VERSION "ZCUD_CAN1"

NS_ :

BS_:

BU_: ETC OGM POT SRS3 TRM ZCUD

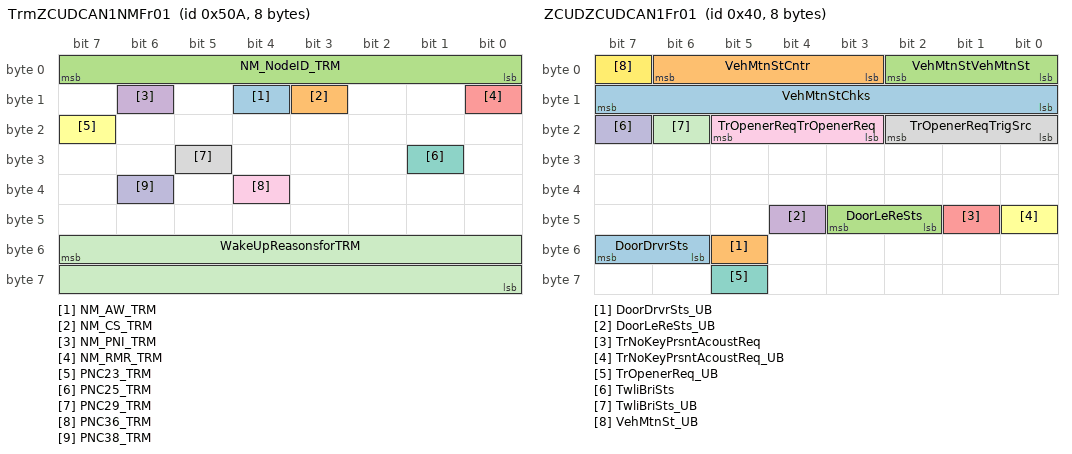
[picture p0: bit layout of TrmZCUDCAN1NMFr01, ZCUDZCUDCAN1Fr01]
BO_ 1290 TrmZCUDCAN1NMFr01: 8 TRM
 SG_ NM_AW_TRM : 12|1@0+ (1,0) [0|0] "" Vector__XXX
 SG_ NM_CS_TRM : 11|1@0+ (1,0) [0|0] "" Vector__XXX
 SG_ NM_NodeID_TRM : 7|8@0+ (1,0) [0|0] "" Vector__XXX
 SG_ NM_PNI_TRM : 14|1@0+ (1,0) [0|0] "" Vector__XXX
 SG_ NM_RMR_TRM : 8|1@0+ (1,0) [0|0] "" Vector__XXX
 SG_ PNC23_TRM : 23|1@0+ (1,0) [0|0] "" Vector__XXX
 SG_ PNC25_TRM : 25|1@0+ (1,0) [0|0] "" Vector__XXX
 SG_ PNC29_TRM : 29|1@0+ (1,0) [0|0] "" Vector__XXX
 SG_ PNC36_TRM : 36|1@0+ (1,0) [0|0] "" Vector__XXX
 SG_ PNC38_TRM : 38|1@0+ (1,0) [0|0] "" Vector__XXX
 SG_ WakeUpReasonsforTRM : 55|16@0+ (1,0) [0|65535] "" Vector__XXX

BO_ 1354 TrmZcudCAN1VFCVectorFr: 8 TRM
 SG_ VFCVectorTRMBlockID : 1|2@0+ (1,0) [0|3] "Unitless"  ZCUD
 SG_ VFCVectorTRMVFCid0 : 2|1@0+ (1,0) [0|1] ""  ZCUD
 SG_ VFCVectorTRMVFCid1 : 3|1@0+ (1,0) [0|1] ""  ZCUD
 SG_ VFCVectorTRMVFCid10 : 12|1@0+ (1,0) [0|1] ""  ZCUD
 SG_ VFCVectorTRMVFCid11 : 13|1@0+ (1,0) [0|1] ""  ZCUD
 SG_ VFCVectorTRMVFCid12 : 14|1@0+ (1,0) [0|1] ""  ZCUD
 SG_ VFCVectorTRMVFCid13 : 15|1@0+ (1,0) [0|1] ""  ZCUD
 SG_ VFCVectorTRMVFCid14 : 16|1@0+ (1,0) [0|1] ""  ZCUD
 SG_ VFCVectorTRMVFCid15 : 17|1@0+ (1,0) [0|1] ""  ZCUD
 SG_ VFCVectorTRMVFCid16 : 18|1@0+ (1,0) [0|1] ""  ZCUD
 SG_ VFCVectorTRMVFCid17 : 19|1@0+ (1,0) [0|1] ""  ZCUD
 SG_ VFCVectorTRMVFCid18 : 20|1@0+ (1,0) [0|1] ""  ZCUD
 SG_ VFCVectorTRMVFCid19 : 21|1@0+ (1,0) [0|1] ""  ZCUD
 SG_ VFCVectorTRMVFCid2 : 4|1@0+ (1,0) [0|1] ""  ZCUD
 SG_ VFCVectorTRMVFCid20 : 22|1@0+ (1,0) [0|1] ""  ZCUD
 SG_ VFCVectorTRMVFCid21 : 23|1@0+ (1,0) [0|1] ""  ZCUD
 SG_ VFCVectorTRMVFCid22 : 24|1@0+ (1,0) [0|1] ""  ZCUD
 SG_ VFCVectorTRMVFCid23 : 25|1@0+ (1,0) [0|1] ""  ZCUD
 SG_ VFCVectorTRMVFCid24 : 26|1@0+ (1,0) [0|1] ""  ZCUD
 SG_ VFCVectorTRMVFCid25 : 27|1@0+ (1,0) [0|1] ""  ZCUD
 SG_ VFCVectorTRMVFCid26 : 28|1@0+ (1,0) [0|1] ""  ZCUD
 SG_ VFCVectorTRMVFCid27 : 29|1@0+ (1,0) [0|1] ""  ZCUD
 SG_ VFCVectorTRMVFCid28 : 30|1@0+ (1,0) [0|1] ""  ZCUD
 SG_ VFCVectorTRMVFCid29 : 31|1@0+ (1,0) [0|1] ""  ZCUD
 SG_ VFCVectorTRMVFCid3 : 5|1@0+ (1,0) [0|1] ""  ZCUD
 SG_ VFCVectorTRMVFCid30 : 32|1@0+ (1,0) [0|1] ""  ZCUD
 SG_ VFCVectorTRMVFCid31 : 33|1@0+ (1,0) [0|1] ""  ZCUD
 SG_ VFCVectorTRMVFCid32 : 34|1@0+ (1,0) [0|1] ""  ZCUD
 SG_ VFCVectorTRMVFCid33 : 35|1@0+ (1,0) [0|1] ""  ZCUD
 SG_ VFCVectorTRMVFCid34 : 36|1@0+ (1,0) [0|1] ""  ZCUD
 SG_ VFCVectorTRMVFCid35 : 37|1@0+ (1,0) [0|1] ""  ZCUD
 SG_ VFCVectorTRMVFCid36 : 38|1@0+ (1,0) [0|1] ""  ZCUD
 SG_ VFCVectorTRMVFCid37 : 39|1@0+ (1,0) [0|1] ""  ZCUD
 SG_ VFCVectorTRMVFCid38 : 40|1@0+ (1,0) [0|1] ""  ZCUD
 SG_ VFCVectorTRMVFCid39 : 41|1@0+ (1,0) [0|1] ""  ZCUD
 SG_ VFCVectorTRMVFCid4 : 6|1@0+ (1,0) [0|1] ""  ZCUD
 SG_ VFCVectorTRMVFCid40 : 42|1@0+ (1,0) [0|1] ""  ZCUD
 SG_ VFCVectorTRMVFCid41 : 43|1@0+ (1,0) [0|1] ""  ZCUD
 SG_ VFCVectorTRMVFCid42 : 44|1@0+ (1,0) [0|1] ""  ZCUD
 SG_ VFCVectorTRMVFCid43 : 45|1@0+ (1,0) [0|1] ""  ZCUD
 SG_ VFCVectorTRMVFCid44 : 46|1@0+ (1,0) [0|1] ""  ZCUD
 SG_ VFCVectorTRMVFCid45 : 47|1@0+ (1,0) [0|1] ""  ZCUD
 SG_ VFCVectorTRMVFCid46 : 48|1@0+ (1,0) [0|1] ""  ZCUD
 SG_ VFCVectorTRMVFCid47 : 49|1@0+ (1,0) [0|1] ""  ZCUD
 SG_ VFCVectorTRMVFCid48 : 50|1@0+ (1,0) [0|1] ""  ZCUD
 SG_ VFCVectorTRMVFCid49 : 51|1@0+ (1,0) [0|1] ""  ZCUD
 SG_ VFCVectorTRMVFCid5 : 7|1@0+ (1,0) [0|1] ""  ZCUD
 SG_ VFCVectorTRMVFCid50 : 52|1@0+ (1,0) [0|1] ""  ZCUD
 SG_ VFCVectorTRMVFCid51 : 53|1@0+ (1,0) [0|1] ""  ZCUD
 SG_ VFCVectorTRMVFCid52 : 54|1@0+ (1,0) [0|1] ""  ZCUD
 SG_ VFCVectorTRMVFCid53 : 55|1@0+ (1,0) [0|1] ""  ZCUD
 SG_ VFCVectorTRMVFCid54 : 56|1@0+ (1,0) [0|1] ""  ZCUD
 SG_ VFCVectorTRMVFCid55 : 57|1@0+ (1,0) [0|1] ""  ZCUD
 SG_ VFCVectorTRMVFCid56 : 58|1@0+ (1,0) [0|1] ""  ZCUD
 SG_ VFCVectorTRMVFCid57 : 59|1@0+ (1,0) [0|1] ""  ZCUD
 SG_ VFCVectorTRMVFCid58 : 60|1@0+ (1,0) [0|1] ""  ZCUD
 SG_ VFCVectorTRMVFCid59 : 61|1@0+ (1,0) [0|1] ""  ZCUD
 SG_ VFCVectorTRMVFCid6 : 8|1@0+ (1,0) [0|1] ""  ZCUD
 SG_ VFCVectorTRMVFCid60 : 62|1@0+ (1,0) [0|1] ""  ZCUD
 SG_ VFCVectorTRMVFCid61 : 63|1@0+ (1,0) [0|1] ""  ZCUD
 SG_ VFCVectorTRMVFCid7 : 9|1@0+ (1,0) [0|1] ""  ZCUD
 SG_ VFCVectorTRMVFCid8 : 10|1@0+ (1,0) [0|1] ""  ZCUD
 SG_ VFCVectorTRMVFCid9 : 11|1@0+ (1,0) [0|1] ""  ZCUD

BO_ 2047 ZcudToAllFuncZcudCAN1DiagReqFr: 8 ZCUD
 SG_ ZcudToAllFuncZcudCAN1DiagReqNpdu : 7|64@0+ (1,0) [0|0] ""  OGM,POT,SRS3,TRM

BO_ 1820 ZcudToCmdZCUDCan1DiagReqFr: 8 ZCUD
 SG_ ZcudToCmdZCUDCan1DiagReqNpdu : 7|64@0+ (1,0) [0|0] "" Vector__XXX

BO_ 1830 ZcudToCrpmZCUDCan1DiagReqFr: 8 ZCUD
 SG_ ZcudToCrpmZCUDCan1DiagReqNpdu : 7|64@0+ (1,0) [0|0] "" Vector__XXX

BO_ 1840 ZcudToHrmZCUDCan1DiagReqFr: 8 ZCUD
 SG_ ZcudToHrmZCUDCAN1DiagReqNpdu : 7|64@0+ (1,0) [0|0] "" Vector__XXX

BO_ 1852 ZcudToOgmZCUDCan1DiagReqFr: 8 ZCUD
 SG_ ZcudToOgmZCUDCan1DiagReqNpdu : 7|64@0+ (1,0) [0|0] ""  OGM

BO_ 1813 ZcudToPotZCUDCan1DiagReqFr: 8 ZCUD
 SG_ ZcudToPotZCUDCan1DiagReqNpdu : 7|64@0+ (1,0) [0|0] ""  POT

BO_ 1808 ZcudToRmlZCUDCAN1DiagReqFrame: 8 ZCUD
 SG_ ZcudToRmlZCUDCAN1DiagReqNpdu : 7|64@0+ (1,0) [0|0] "" Vector__XXX

BO_ 1809 ZcudToRmrZCUDCAN1DiagReqFrame: 8 ZCUD
 SG_ ZcudToRmrZCUDCAN1DiagReqNpdu : 7|64@0+ (1,0) [0|0] "" Vector__XXX

BO_ 1827 ZcudToSdlZCUDCan1DiagReqFr: 8 ZCUD
 SG_ ZcudToSdlZCUDCAN1DiagReqNpdu : 7|64@0+ (1,0) [0|0] "" Vector__XXX

BO_ 1828 ZcudToSdrZCUDCan1DiagReqFr: 8 ZCUD
 SG_ ZcudToSdrZCUDCAN1DiagReqNpdu : 7|64@0+ (1,0) [0|0] "" Vector__XXX

BO_ 1841 ZcudToSmblZCUDCAN1DiagReqFrame: 8 ZCUD
 SG_ ZcudToSmblZCUDCAN1DiagReqNpdu : 7|64@0+ (1,0) [0|0] "" Vector__XXX

BO_ 1842 ZcudToSmbrZCUDCAN1DiagReqFrame: 8 ZCUD
 SG_ ZcudToSmbrZCUDCAN1DiagReqNpdu : 7|64@0+ (1,0) [0|0] "" Vector__XXX

BO_ 1833 ZcudToSmrZCUDCAN1DiagReqFrame: 8 ZCUD
 SG_ ZcudToSmbZCUDCAN1DiagReqNpdu : 7|64@0+ (1,0) [0|0] "" Vector__XXX

BO_ 2033 ZcudToSrsISO26021ZCUDCAN1DiagRes: 8 ZCUD
 SG_ ZcudToSrsISO26021ZCUDCan1ReqNpdu : 7|64@0+ (1,0) [0|0] ""  SRS3

BO_ 1849 ZcudToSrsZCUDCan1DiagReqFr: 8 ZCUD
 SG_ ZcudToSrsZCUDCan1DiagReqNpdu : 7|64@0+ (1,0) [0|0] ""  SRS3

BO_ 1834 ZcudToTcmbZCUDCan1DiagReqFr: 8 ZCUD
 SG_ ZcudToTcmbZCUDCan1DiagReqNpdu : 7|64@0+ (1,0) [0|0] "" Vector__XXX

BO_ 1815 ZcudToTrmZCUDCAN1DiagReqFrame: 8 ZCUD
 SG_ ZcudToTrmZCUDCAN1DiagReqNpdu : 7|64@0+ (1,0) [0|0] ""  TRM

BO_ 1835 ZcudToWpcZCUDCan1DiagReqFr: 8 ZCUD
 SG_ ZcudToWpcZCUDCan1DiagReqNpdu : 7|64@0+ (1,0) [0|0] "" Vector__XXX

BO_ 1846 ZcudToWprlZCUDCan1DiagReqFr: 8 ZCUD
 SG_ ZcudToWprlZCUDCAN1DiagReqNpdu : 7|64@0+ (1,0) [0|0] "" Vector__XXX

BO_ 1847 ZcudToWprrZCUDCan1DiagReqFr: 8 ZCUD
 SG_ ZcudToWprrZCUDCAN1DiagReqNpdu : 7|64@0+ (1,0) [0|0] "" Vector__XXX

BO_ 1345 ZcudZCUCAN1VFCVectorFr: 8 ZCUD
 SG_ VFCVectorZCUDMBlockID : 1|2@0+ (1,0) [0|3] "Unitless" Vector__XXX
 SG_ VFCVectorZCUDMVFCid0 : 2|1@0+ (1,0) [0|1] "" Vector__XXX
 SG_ VFCVectorZCUDMVFCid1 : 3|1@0+ (1,0) [0|1] "" Vector__XXX
 SG_ VFCVectorZCUDMVFCid10 : 12|1@0+ (1,0) [0|1] "" Vector__XXX
 SG_ VFCVectorZCUDMVFCid11 : 13|1@0+ (1,0) [0|1] "" Vector__XXX
 SG_ VFCVectorZCUDMVFCid12 : 14|1@0+ (1,0) [0|1] "" Vector__XXX
 SG_ VFCVectorZCUDMVFCid13 : 15|1@0+ (1,0) [0|1] "" Vector__XXX
 SG_ VFCVectorZCUDMVFCid14 : 16|1@0+ (1,0) [0|1] "" Vector__XXX
 SG_ VFCVectorZCUDMVFCid15 : 17|1@0+ (1,0) [0|1] "" Vector__XXX
 SG_ VFCVectorZCUDMVFCid16 : 18|1@0+ (1,0) [0|1] "" Vector__XXX
 SG_ VFCVectorZCUDMVFCid17 : 19|1@0+ (1,0) [0|1] "" Vector__XXX
 SG_ VFCVectorZCUDMVFCid18 : 20|1@0+ (1,0) [0|1] "" Vector__XXX
 SG_ VFCVectorZCUDMVFCid19 : 21|1@0+ (1,0) [0|1] "" Vector__XXX
 SG_ VFCVectorZCUDMVFCid2 : 4|1@0+ (1,0) [0|1] "" Vector__XXX
 SG_ VFCVectorZCUDMVFCid20 : 22|1@0+ (1,0) [0|1] "" Vector__XXX
 SG_ VFCVectorZCUDMVFCid21 : 23|1@0+ (1,0) [0|1] "" Vector__XXX
 SG_ VFCVectorZCUDMVFCid22 : 24|1@0+ (1,0) [0|1] "" Vector__XXX
 SG_ VFCVectorZCUDMVFCid23 : 25|1@0+ (1,0) [0|1] "" Vector__XXX
 SG_ VFCVectorZCUDMVFCid24 : 26|1@0+ (1,0) [0|1] "" Vector__XXX
 SG_ VFCVectorZCUDMVFCid25 : 27|1@0+ (1,0) [0|1] "" Vector__XXX
 SG_ VFCVectorZCUDMVFCid26 : 28|1@0+ (1,0) [0|1] "" Vector__XXX
 SG_ VFCVectorZCUDMVFCid27 : 29|1@0+ (1,0) [0|1] "" Vector__XXX
 SG_ VFCVectorZCUDMVFCid28 : 30|1@0+ (1,0) [0|1] "" Vector__XXX
 SG_ VFCVectorZCUDMVFCid29 : 31|1@0+ (1,0) [0|1] "" Vector__XXX
 SG_ VFCVectorZCUDMVFCid3 : 5|1@0+ (1,0) [0|1] "" Vector__XXX
 SG_ VFCVectorZCUDMVFCid30 : 32|1@0+ (1,0) [0|1] "" Vector__XXX
 SG_ VFCVectorZCUDMVFCid31 : 33|1@0+ (1,0) [0|1] "" Vector__XXX
 SG_ VFCVectorZCUDMVFCid32 : 34|1@0+ (1,0) [0|1] "" Vector__XXX
 SG_ VFCVectorZCUDMVFCid33 : 35|1@0+ (1,0) [0|1] "" Vector__XXX
 SG_ VFCVectorZCUDMVFCid34 : 36|1@0+ (1,0) [0|1] "" Vector__XXX
 SG_ VFCVectorZCUDMVFCid35 : 37|1@0+ (1,0) [0|1] "" Vector__XXX
 SG_ VFCVectorZCUDMVFCid36 : 38|1@0+ (1,0) [0|1] "" Vector__XXX
 SG_ VFCVectorZCUDMVFCid37 : 39|1@0+ (1,0) [0|1] "" Vector__XXX
 SG_ VFCVectorZCUDMVFCid38 : 40|1@0+ (1,0) [0|1] "" Vector__XXX
 SG_ VFCVectorZCUDMVFCid39 : 41|1@0+ (1,0) [0|1] "" Vector__XXX
 SG_ VFCVectorZCUDMVFCid4 : 6|1@0+ (1,0) [0|1] "" Vector__XXX
 SG_ VFCVectorZCUDMVFCid40 : 42|1@0+ (1,0) [0|1] "" Vector__XXX
 SG_ VFCVectorZCUDMVFCid41 : 43|1@0+ (1,0) [0|1] "" Vector__XXX
 SG_ VFCVectorZCUDMVFCid42 : 44|1@0+ (1,0) [0|1] "" Vector__XXX
 SG_ VFCVectorZCUDMVFCid43 : 45|1@0+ (1,0) [0|1] "" Vector__XXX
 SG_ VFCVectorZCUDMVFCid44 : 46|1@0+ (1,0) [0|1] "" Vector__XXX
 SG_ VFCVectorZCUDMVFCid45 : 47|1@0+ (1,0) [0|1] "" Vector__XXX
 SG_ VFCVectorZCUDMVFCid46 : 48|1@0+ (1,0) [0|1] "" Vector__XXX
 SG_ VFCVectorZCUDMVFCid47 : 49|1@0+ (1,0) [0|1] "" Vector__XXX
 SG_ VFCVectorZCUDMVFCid48 : 50|1@0+ (1,0) [0|1] "" Vector__XXX
 SG_ VFCVectorZCUDMVFCid49 : 51|1@0+ (1,0) [0|1] "" Vector__XXX
 SG_ VFCVectorZCUDMVFCid5 : 7|1@0+ (1,0) [0|1] "" Vector__XXX
 SG_ VFCVectorZCUDMVFCid50 : 52|1@0+ (1,0) [0|1] "" Vector__XXX
 SG_ VFCVectorZCUDMVFCid51 : 53|1@0+ (1,0) [0|1] "" Vector__XXX
 SG_ VFCVectorZCUDMVFCid52 : 54|1@0+ (1,0) [0|1] "" Vector__XXX
 SG_ VFCVectorZCUDMVFCid53 : 55|1@0+ (1,0) [0|1] "" Vector__XXX
 SG_ VFCVectorZCUDMVFCid54 : 56|1@0+ (1,0) [0|1] "" Vector__XXX
 SG_ VFCVectorZCUDMVFCid55 : 57|1@0+ (1,0) [0|1] "" Vector__XXX
 SG_ VFCVectorZCUDMVFCid56 : 58|1@0+ (1,0) [0|1] "" Vector__XXX
 SG_ VFCVectorZCUDMVFCid57 : 59|1@0+ (1,0) [0|1] "" Vector__XXX
 SG_ VFCVectorZCUDMVFCid58 : 60|1@0+ (1,0) [0|1] "" Vector__XXX
 SG_ VFCVectorZCUDMVFCid59 : 61|1@0+ (1,0) [0|1] "" Vector__XXX
 SG_ VFCVectorZCUDMVFCid6 : 8|1@0+ (1,0) [0|1] "" Vector__XXX
 SG_ VFCVectorZCUDMVFCid60 : 62|1@0+ (1,0) [0|1] "" Vector__XXX
 SG_ VFCVectorZCUDMVFCid61 : 63|1@0+ (1,0) [0|1] "" Vector__XXX
 SG_ VFCVectorZCUDMVFCid7 : 9|1@0+ (1,0) [0|1] "" Vector__XXX
 SG_ VFCVectorZCUDMVFCid8 : 10|1@0+ (1,0) [0|1] "" Vector__XXX
 SG_ VFCVectorZCUDMVFCid9 : 11|1@0+ (1,0) [0|1] "" Vector__XXX

BO_ 64 ZCUDZCUDCAN1Fr01: 8 ZCUD
 SG_ DoorDrvrSts : 55|2@0+ (1,0) [0|3] ""  SRS3,TRM
 SG_ DoorDrvrSts_UB : 53|1@0+ (1,0) [0|1] ""  SRS3,TRM
 SG_ DoorLeReSts : 43|2@0+ (1,0) [0|3] ""  SRS3,TRM
 SG_ DoorLeReSts_UB : 44|1@0+ (1,0) [0|1] ""  SRS3,TRM
 SG_ TrNoKeyPrsntAcoustReq : 41|1@0+ (1,0) [0|1] "" Vector__XXX
 SG_ TrNoKeyPrsntAcoustReq_UB : 40|1@0+ (1,0) [0|1] "" Vector__XXX
 SG_ TrOpenerReq_UB : 61|1@0+ (1,0) [0|1] "" Vector__XXX
 SG_ TrOpenerReqTrigSrc : 18|3@0+ (1,0) [0|7] "" Vector__XXX
 SG_ TrOpenerReqTrOpenerReq : 21|3@0+ (1,0) [0|7] "" Vector__XXX
 SG_ TwliBriSts : 23|1@0+ (1,0) [0|1] ""  TRM
 SG_ TwliBriSts_UB : 22|1@0+ (1,0) [0|1] ""  TRM
 SG_ VehMtnSt_UB : 7|1@0+ (1,0) [0|1] ""  POT,SRS3,TRM
 SG_ VehMtnStChks : 15|8@0+ (1,0) [0|255] "Unitless"  POT,SRS3,TRM
 SG_ VehMtnStCntr : 6|4@0+ (1,0) [0|15] "Unitless"  POT,SRS3,TRM
 SG_ VehMtnStVehMtnSt : 2|3@0+ (1,0) [0|7] ""  POT,SRS3,TRM

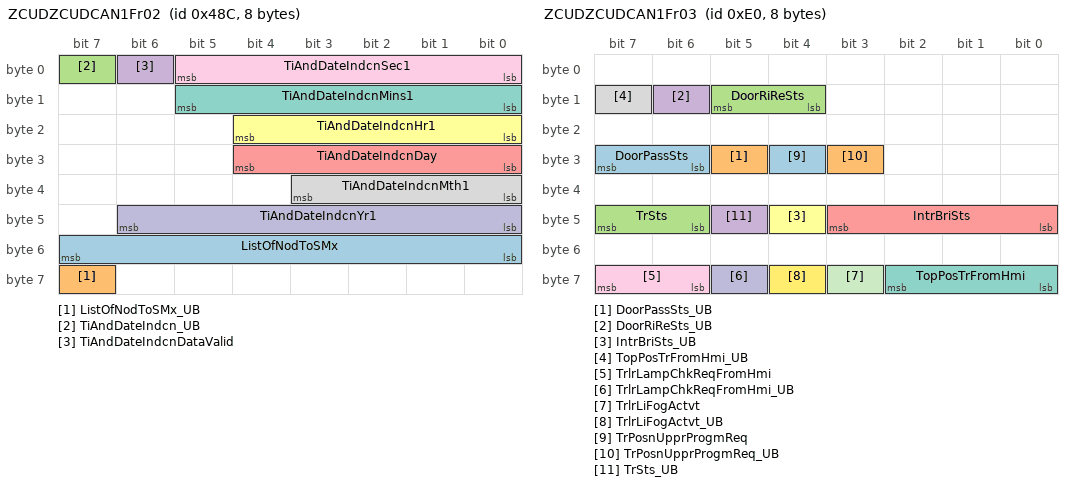
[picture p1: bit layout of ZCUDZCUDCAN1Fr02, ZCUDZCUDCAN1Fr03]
BO_ 1164 ZCUDZCUDCAN1Fr02: 8 ZCUD
 SG_ ListOfNodToSMx : 55|8@0+ (1,0) [0|255] "Unitless" Vector__XXX
 SG_ ListOfNodToSMx_UB : 63|1@0+ (1,0) [0|1] "" Vector__XXX
 SG_ TiAndDateIndcn_UB : 7|1@0+ (1,0) [0|1] ""  OGM,POT,SRS3,TRM
 SG_ TiAndDateIndcnDataValid : 6|1@0+ (1,0) [0|1] ""  OGM,POT,SRS3,TRM
 SG_ TiAndDateIndcnDay : 28|5@0+ (1,0) [1|31] "Days"  OGM,POT,SRS3,TRM
 SG_ TiAndDateIndcnHr1 : 20|5@0+ (1,0) [0|23] "hours"  OGM,POT,SRS3,TRM
 SG_ TiAndDateIndcnMins1 : 13|6@0+ (1,0) [0|59] "Mins"  OGM,POT,SRS3,TRM
 SG_ TiAndDateIndcnMth1 : 35|4@0+ (1,0) [1|12] "Month"  OGM,POT,SRS3,TRM
 SG_ TiAndDateIndcnSec1 : 5|6@0+ (1,0) [0|59] "s"  OGM,POT,SRS3,TRM
 SG_ TiAndDateIndcnYr1 : 46|7@0+ (1,0) [0|99] "Year"  OGM,POT,SRS3,TRM

BO_ 224 ZCUDZCUDCAN1Fr03: 8 ZCUD
 SG_ DoorPassSts : 31|2@0+ (1,0) [0|3] ""  SRS3,TRM
 SG_ DoorPassSts_UB : 29|1@0+ (1,0) [0|1] ""  SRS3,TRM
 SG_ DoorRiReSts : 13|2@0+ (1,0) [0|3] ""  SRS3,TRM
 SG_ DoorRiReSts_UB : 14|1@0+ (1,0) [0|1] ""  SRS3,TRM
 SG_ IntrBriSts : 43|4@0+ (1,0) [0|15] "Unitless" Vector__XXX
 SG_ IntrBriSts_UB : 44|1@0+ (1,0) [0|1] "" Vector__XXX
 SG_ TopPosTrFromHmi : 58|3@0+ (1,0) [0|7] "" Vector__XXX
 SG_ TopPosTrFromHmi_UB : 15|1@0+ (1,0) [0|1] "" Vector__XXX
 SG_ TrlrLampChkReqFromHmi : 63|2@0+ (1,0) [0|3] ""  TRM
 SG_ TrlrLampChkReqFromHmi_UB : 61|1@0+ (1,0) [0|1] ""  TRM
 SG_ TrlrLiFogActvt : 59|1@0+ (1,0) [0|1] ""  TRM
 SG_ TrlrLiFogActvt_UB : 60|1@0+ (1,0) [0|1] ""  TRM
 SG_ TrPosnUpprProgmReq : 28|1@0+ (1,0) [0|1] "" Vector__XXX
 SG_ TrPosnUpprProgmReq_UB : 27|1@0+ (1,0) [0|1] "" Vector__XXX
 SG_ TrSts : 47|2@0+ (1,0) [0|3] ""  POT,TRM
 SG_ TrSts_UB : 45|1@0+ (1,0) [0|1] ""  POT,TRM

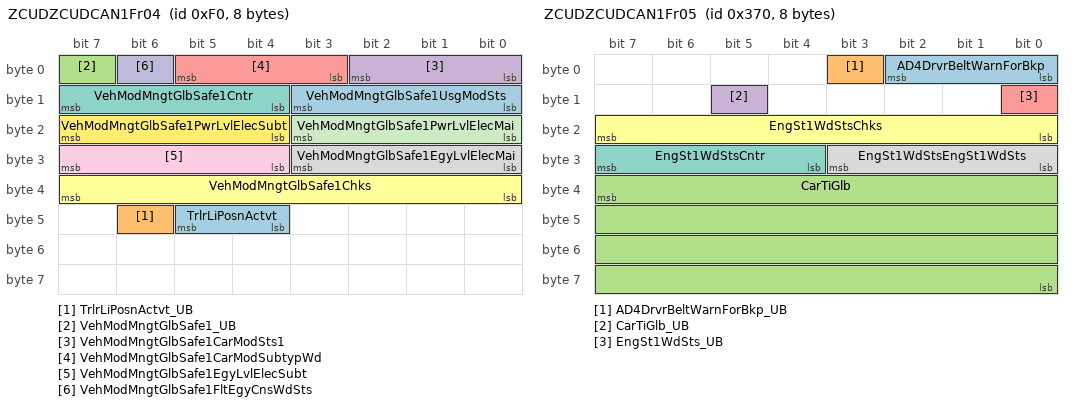
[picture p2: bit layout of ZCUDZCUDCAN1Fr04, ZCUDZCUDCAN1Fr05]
BO_ 240 ZCUDZCUDCAN1Fr04: 8 ZCUD
 SG_ TrlrLiPosnActvt : 45|2@0+ (1,0) [0|3] ""  TRM
 SG_ TrlrLiPosnActvt_UB : 46|1@0+ (1,0) [0|1] ""  TRM
 SG_ VehModMngtGlbSafe1_UB : 7|1@0+ (1,0) [0|1] ""  OGM,POT,SRS3,TRM
 SG_ VehModMngtGlbSafe1CarModSts1 : 2|3@0+ (1,0) [0|7] ""  OGM,POT,SRS3,TRM
 SG_ VehModMngtGlbSafe1CarModSubtypWd : 5|3@0+ (1,0) [0|7] "Unitless"  OGM,POT,SRS3,TRM
 SG_ VehModMngtGlbSafe1Chks : 39|8@0+ (1,0) [0|255] "Unitless"  OGM,POT,SRS3,TRM
 SG_ VehModMngtGlbSafe1Cntr : 15|4@0+ (1,0) [0|15] "Unitless"  OGM,POT,SRS3,TRM
 SG_ VehModMngtGlbSafe1EgyLvlElecMai : 27|4@0+ (1,0) [0|15] "Unitless"  OGM,POT,SRS3,TRM
 SG_ VehModMngtGlbSafe1EgyLvlElecSubt : 31|4@0+ (1,0) [0|15] "Unitless"  OGM,POT,SRS3,TRM
 SG_ VehModMngtGlbSafe1FltEgyCnsWdSts : 6|1@0+ (1,0) [0|1] ""  OGM,POT,SRS3,TRM
 SG_ VehModMngtGlbSafe1PwrLvlElecMai : 19|4@0+ (1,0) [0|15] "Unitless"  OGM,POT,SRS3,TRM
 SG_ VehModMngtGlbSafe1PwrLvlElecSubt : 23|4@0+ (1,0) [0|15] "Unitless"  OGM,POT,SRS3,TRM
 SG_ VehModMngtGlbSafe1UsgModSts : 11|4@0+ (1,0) [0|15] ""  OGM,POT,SRS3,TRM

BO_ 880 ZCUDZCUDCAN1Fr05: 8 ZCUD
 SG_ AD4DrvrBeltWarnForBkp : 2|3@0+ (1,0) [0|7] "" Vector__XXX
 SG_ AD4DrvrBeltWarnForBkp_UB : 3|1@0+ (1,0) [0|1] "" Vector__XXX
 SG_ CarTiGlb : 39|32@0+ (0.1,0) [0|429496729.5] "s"  OGM,POT,SRS3,TRM
 SG_ CarTiGlb_UB : 13|1@0+ (1,0) [0|1] ""  OGM,POT,SRS3,TRM
 SG_ EngSt1WdSts_UB : 8|1@0+ (1,0) [0|1] "" Vector__XXX
 SG_ EngSt1WdStsChks : 23|8@0+ (1,0) [0|255] "Unitless" Vector__XXX
 SG_ EngSt1WdStsCntr : 31|4@0+ (1,0) [0|15] "Unitless" Vector__XXX
 SG_ EngSt1WdStsEngSt1WdSts : 27|4@0+ (1,0) [0|15] "" Vector__XXX

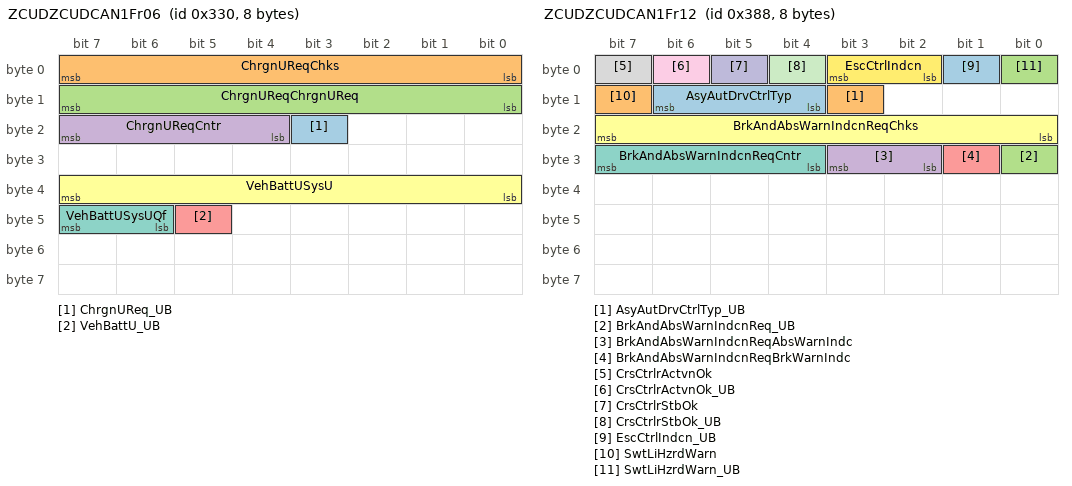
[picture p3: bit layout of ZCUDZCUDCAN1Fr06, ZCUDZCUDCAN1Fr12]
BO_ 816 ZCUDZCUDCAN1Fr06: 8 ZCUD
 SG_ ChrgnUReq_UB : 19|1@0+ (1,0) [0|1] "" Vector__XXX
 SG_ ChrgnUReqChks : 7|8@0+ (1,0) [0|255] "Unitless" Vector__XXX
 SG_ ChrgnUReqChrgnUReq : 15|8@0+ (0.025,10.6) [10.6|16] "Volt" Vector__XXX
 SG_ ChrgnUReqCntr : 23|4@0+ (1,0) [0|15] "Unitless" Vector__XXX
 SG_ VehBattU_UB : 45|1@0+ (1,0) [0|1] ""  OGM,POT,SRS3,TRM
 SG_ VehBattUSysU : 39|8@0+ (0.1,0) [0|25] "Volt"  OGM,POT,SRS3,TRM
 SG_ VehBattUSysUQf : 47|2@0+ (1,0) [0|3] ""  OGM,POT,SRS3,TRM

BO_ 881 ZCUDZCUDCAN1Fr09: 8 ZCUD
 SG_ AD4DrvrBeltWarn : 2|3@0+ (1,0) [0|7] "" Vector__XXX
 SG_ AD4DrvrBeltWarn_UB : 3|1@0+ (1,0) [0|1] "" Vector__XXX
 SG_ CarModCrashSaved : 7|1@0+ (1,0) [0|1] ""  SRS3
 SG_ CarModCrashSaved_UB : 6|1@0+ (1,0) [0|1] ""  SRS3
 SG_ DrvrSeatSnsrSts : 5|2@0+ (1,0) [0|3] "" Vector__XXX
 SG_ DrvrSeatSnsrSts_UB : 31|1@0+ (1,0) [0|1] "" Vector__XXX
 SG_ EngN2 : 14|15@0+ (0.5,0) [0|16383.5] "rpm"  SRS3
 SG_ EngN2_UB : 15|1@0+ (1,0) [0|1] ""  SRS3
 SG_ HvBattPreChrgReq : 52|1@0+ (1,0) [0|1] "" Vector__XXX
 SG_ HvBattPreChrgReq_UB : 51|1@0+ (1,0) [0|1] "" Vector__XXX
 SG_ IsgSpdActSgn : 39|16@0+ (1,-20000) [-20000|45535] "rpm"  SRS3
 SG_ IsgSpdActSgn_UB : 53|1@0+ (1,0) [0|1] ""  SRS3
 SG_ PostImpctBrkgRdy : 29|2@0+ (1,0) [0|3] ""  SRS3
 SG_ PostImpctBrkgRdy_UB : 30|1@0+ (1,0) [0|1] ""  SRS3
 SG_ RlyPwrDistbnCmd1WdPreBattSaveCmd : 50|1@0+ (1,0) [0|1] "" Vector__XXX
 SG_ RlyPwrDistbnCmd1WdPreBattSa_0000 : 49|1@0+ (1,0) [0|1] "" Vector__XXX
 SG_ SeatOccptAtRowSecDrSide2 : 27|2@0+ (1,0) [0|3] "" Vector__XXX
 SG_ SeatOccptAtRowSecDrSide2_UB : 25|1@0+ (1,0) [0|1] "" Vector__XXX
 SG_ SeatOccptAtRowSecDrSideSnsSts2 : 55|2@0+ (1,0) [0|3] "" Vector__XXX
 SG_ SeatOccptAtRowSecDrSideSnsSts2_U : 24|1@0+ (1,0) [0|1] "" Vector__XXX

BO_ 912 ZCUDZCUDCAN1Fr10: 8 ZCUD
 SG_ DispOfPrpsnMod : 60|4@0+ (1,0) [0|15] ""  SRS3
 SG_ DispOfPrpsnMod_UB : 56|1@0+ (1,0) [0|1] ""  SRS3
 SG_ DispOfPrpsnModForEv : 7|4@0+ (1,0) [0|15] ""  SRS3
 SG_ DispOfPrpsnModForEv_UB : 3|1@0+ (1,0) [0|1] ""  SRS3
 SG_ DrvrSeatPosPerc_UB : 2|1@0+ (1,0) [0|1] ""  SRS3
 SG_ DrvrSeatPosPercSeatPosFrntHeiPer : 15|10@0+ (0.1,0) [0|100] "%"  SRS3
 SG_ DrvrSeatPosPercSeatPosFrntHeiQF : 1|2@0+ (1,0) [0|3] ""  SRS3
 SG_ DrvrSeatPosPercSeatPosHeiPerc : 17|10@0+ (0.1,0) [0|100] "%"  SRS3
 SG_ DrvrSeatPosPercSeatPosHeiQF : 19|2@0+ (1,0) [0|3] ""  SRS3
 SG_ DrvrSeatPosPercSeatPosSldPerc : 39|10@0+ (0.1,0) [0|100] "%"  SRS3
 SG_ DrvrSeatPosPercSeatPosSldQF : 21|2@0+ (1,0) [0|3] ""  SRS3
 SG_ PassAirbLampStsRec_UB : 63|1@0+ (1,0) [0|1] ""  SRS3
 SG_ PassAirbLampStsRecPassAirbLampSt : 45|2@0+ (1,0) [0|3] ""  SRS3
 SG_ PassAirbLampStsRecPassAirbL_0000 : 55|8@0+ (1,0) [0|255] "Unitless"  SRS3
 SG_ PassAirbLampStsRecPassAirbL_0001 : 43|4@0+ (1,0) [0|15] "Unitless"  SRS3
 SG_ RlyPwrDistbnCmd1WdIgnRlyExtCmd : 62|1@0+ (1,0) [0|1] ""  SRS3
 SG_ RlyPwrDistbnCmd1WdIgnRlyExtCmd_U : 61|1@0+ (1,0) [0|1] ""  SRS3

BO_ 924 ZCUDZCUDCAN1Fr11: 8 ZCUD
 SG_ RiFrntTireMsg_UB : 31|1@0+ (1,0) [0|1] ""  SRS3
 SG_ RiFrntTireMsgBattLoSt : 7|1@0+ (1,0) [0|1] ""  SRS3
 SG_ RiFrntTireMsgFastLoseWarnFlg : 6|1@0+ (1,0) [0|1] ""  SRS3
 SG_ RiFrntTireMsgMsgOldFlg : 5|1@0+ (1,0) [0|1] ""  SRS3
 SG_ RiFrntTireMsgP : 15|8@0+ (1.373,0) [0|350.115] "KiloPa"  SRS3
 SG_ RiFrntTireMsgPWarnFlg : 4|2@0+ (1,0) [0|3] ""  SRS3
 SG_ RiFrntTireMsgSysWarnFlg : 2|1@0+ (1,0) [0|1] ""  SRS3
 SG_ RiFrntTireMsgT : 23|8@0+ (1,-50) [-50|205] "degC"  SRS3
 SG_ RiFrntTireMsgTireFillgAssiPSts : 0|1@0+ (1,0) [0|1] ""  SRS3
 SG_ RiFrntTireMsgTWarnFlg : 1|1@0+ (1,0) [0|1] ""  SRS3
 SG_ RiReTireMsg_UB : 30|1@0+ (1,0) [0|1] ""  SRS3
 SG_ RiReTireMsgBattLoSt : 47|1@0+ (1,0) [0|1] ""  SRS3
 SG_ RiReTireMsgFastLoseWarnFlg : 46|1@0+ (1,0) [0|1] ""  SRS3
 SG_ RiReTireMsgMsgOldFlg : 45|1@0+ (1,0) [0|1] ""  SRS3
 SG_ RiReTireMsgP : 55|8@0+ (1.373,0) [0|350.115] "KiloPa"  SRS3
 SG_ RiReTireMsgPWarnFlg : 44|2@0+ (1,0) [0|3] ""  SRS3
 SG_ RiReTireMsgSysWarnFlg : 42|1@0+ (1,0) [0|1] ""  SRS3
 SG_ RiReTireMsgT : 63|8@0+ (1,-50) [-50|205] "degC"  SRS3
 SG_ RiReTireMsgTireFillgAssiPSts : 40|1@0+ (1,0) [0|1] ""  SRS3
 SG_ RiReTireMsgTWarnFlg : 41|1@0+ (1,0) [0|1] ""  SRS3

BO_ 904 ZCUDZCUDCAN1Fr12: 8 ZCUD
 SG_ AsyAutDrvCtrlTyp : 14|3@0+ (1,0) [0|7] ""  SRS3
 SG_ AsyAutDrvCtrlTyp_UB : 11|1@0+ (1,0) [0|1] ""  SRS3
 SG_ BrkAndAbsWarnIndcnReq_UB : 24|1@0+ (1,0) [0|1] ""  SRS3
 SG_ BrkAndAbsWarnIndcnReqAbsWarnIndc : 27|2@0+ (1,0) [0|3] ""  SRS3
 SG_ BrkAndAbsWarnIndcnReqBrkWarnIndc : 25|1@0+ (1,0) [0|1] ""  SRS3
 SG_ BrkAndAbsWarnIndcnReqChks : 23|8@0+ (1,0) [0|255] "Unitless"  SRS3
 SG_ BrkAndAbsWarnIndcnReqCntr : 31|4@0+ (1,0) [0|15] "Unitless"  SRS3
 SG_ CrsCtrlrActvnOk : 7|1@0+ (1,0) [0|1] ""  SRS3
 SG_ CrsCtrlrActvnOk_UB : 6|1@0+ (1,0) [0|1] ""  SRS3
 SG_ CrsCtrlrStbOk : 5|1@0+ (1,0) [0|1] ""  SRS3
 SG_ CrsCtrlrStbOk_UB : 4|1@0+ (1,0) [0|1] ""  SRS3
 SG_ EscCtrlIndcn : 3|2@0+ (1,0) [0|3] ""  SRS3
 SG_ EscCtrlIndcn_UB : 1|1@0+ (1,0) [0|1] ""  SRS3
 SG_ SwtLiHzrdWarn : 15|1@0+ (1,0) [0|1] ""  SRS3
 SG_ SwtLiHzrdWarn_UB : 0|1@0+ (1,0) [0|1] ""  SRS3

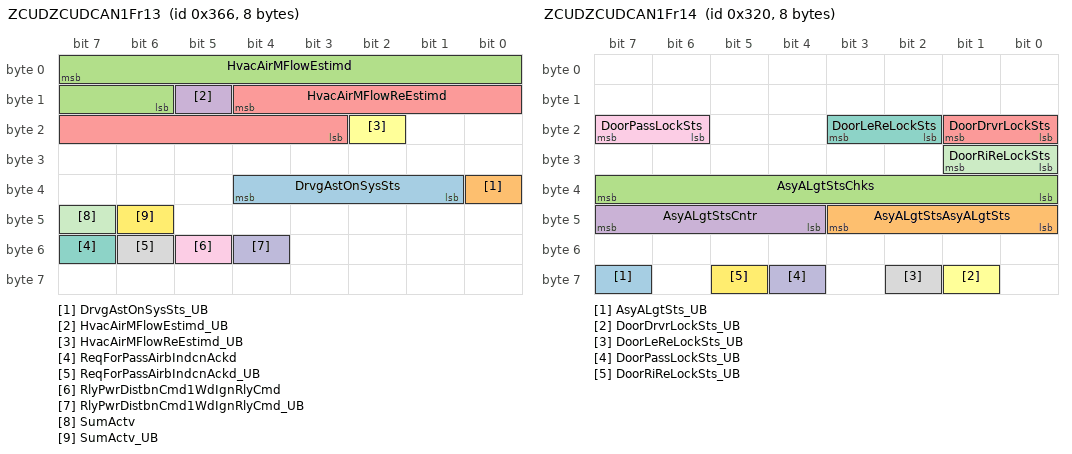
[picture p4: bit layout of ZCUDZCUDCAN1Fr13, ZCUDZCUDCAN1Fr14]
BO_ 870 ZCUDZCUDCAN1Fr13: 8 ZCUD
 SG_ DrvgAstOnSysSts : 36|4@0+ (1,0) [0|15] "" Vector__XXX
 SG_ DrvgAstOnSysSts_UB : 32|1@0+ (1,0) [0|1] "" Vector__XXX
 SG_ HvacAirMFlowEstimd : 7|10@0+ (1,0) [0|1000] "Kg / h" Vector__XXX
 SG_ HvacAirMFlowEstimd_UB : 13|1@0+ (1,0) [0|1] "" Vector__XXX
 SG_ HvacAirMFlowReEstimd : 12|10@0+ (1,0) [0|1000] "Kg / h" Vector__XXX
 SG_ HvacAirMFlowReEstimd_UB : 18|1@0+ (1,0) [0|1] "" Vector__XXX
 SG_ ReqForPassAirbIndcnAckd : 55|1@0+ (1,0) [0|1] ""  SRS3
 SG_ ReqForPassAirbIndcnAckd_UB : 54|1@0+ (1,0) [0|1] ""  SRS3
 SG_ RlyPwrDistbnCmd1WdIgnRlyCmd : 53|1@0+ (1,0) [0|1] ""  SRS3
 SG_ RlyPwrDistbnCmd1WdIgnRlyCmd_UB : 52|1@0+ (1,0) [0|1] ""  SRS3
 SG_ SumActv : 47|1@0+ (1,0) [0|1] ""  SRS3
 SG_ SumActv_UB : 46|1@0+ (1,0) [0|1] ""  SRS3

BO_ 800 ZCUDZCUDCAN1Fr14: 8 ZCUD
 SG_ AsyALgtSts_UB : 63|1@0+ (1,0) [0|1] ""  SRS3
 SG_ AsyALgtStsAsyALgtSts : 43|4@0+ (1,0) [0|15] ""  SRS3
 SG_ AsyALgtStsChks : 39|8@0+ (1,0) [0|255] "Unitless"  SRS3
 SG_ AsyALgtStsCntr : 47|4@0+ (1,0) [0|15] "Unitless"  SRS3
 SG_ DoorDrvrLockSts : 17|2@0+ (1,0) [0|3] ""  SRS3
 SG_ DoorDrvrLockSts_UB : 57|1@0+ (1,0) [0|1] ""  SRS3
 SG_ DoorLeReLockSts : 19|2@0+ (1,0) [0|3] ""  SRS3
 SG_ DoorLeReLockSts_UB : 58|1@0+ (1,0) [0|1] ""  SRS3
 SG_ DoorPassLockSts : 23|2@0+ (1,0) [0|3] ""  SRS3
 SG_ DoorPassLockSts_UB : 60|1@0+ (1,0) [0|1] ""  SRS3
 SG_ DoorRiReLockSts : 25|2@0+ (1,0) [0|3] ""  SRS3
 SG_ DoorRiReLockSts_UB : 61|1@0+ (1,0) [0|1] ""  SRS3

BO_ 385 ZCUDZCUDCAN1Fr18: 8 ZCUD
 SG_ EmgyAsscTrigSts : 53|2@0+ (1,0) [0|3] ""  SRS3
 SG_ EmgyAsscTrigSts_UB : 54|1@0+ (1,0) [0|1] ""  SRS3

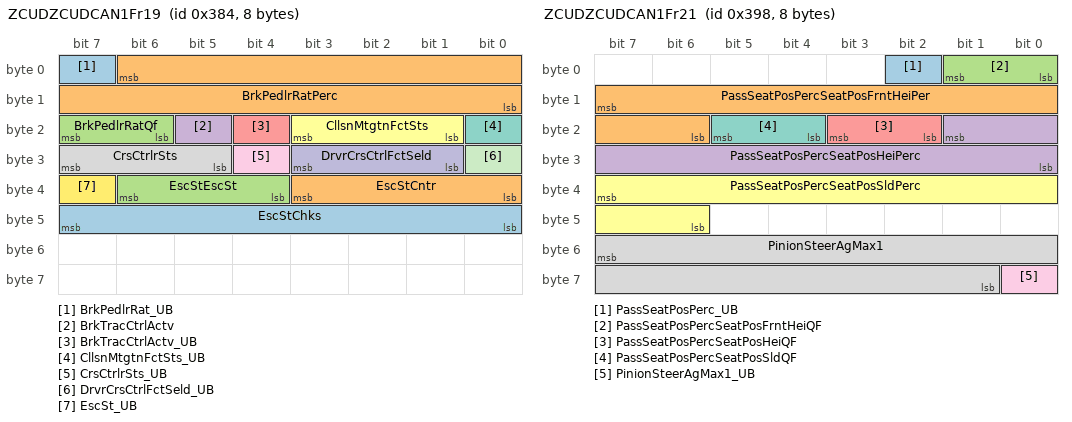
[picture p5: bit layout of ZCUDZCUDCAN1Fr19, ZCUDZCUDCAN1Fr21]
BO_ 900 ZCUDZCUDCAN1Fr19: 8 ZCUD
 SG_ BrkPedlrRat_UB : 7|1@0+ (1,0) [0|1] ""  SRS3
 SG_ BrkPedlrRatPerc : 6|15@0+ (0.00390625,0) [0|100] "%"  SRS3
 SG_ BrkPedlrRatQf : 23|2@0+ (1,0) [0|3] ""  SRS3
 SG_ BrkTracCtrlActv : 21|1@0+ (1,0) [0|1] ""  SRS3
 SG_ BrkTracCtrlActv_UB : 20|1@0+ (1,0) [0|1] ""  SRS3
 SG_ CllsnMtgtnFctSts : 19|3@0+ (1,0) [0|7] ""  SRS3
 SG_ CllsnMtgtnFctSts_UB : 16|1@0+ (1,0) [0|1] ""  SRS3
 SG_ CrsCtrlrSts : 31|3@0+ (1,0) [0|7] ""  SRS3
 SG_ CrsCtrlrSts_UB : 28|1@0+ (1,0) [0|1] ""  SRS3
 SG_ DrvrCrsCtrlFctSeld : 27|3@0+ (1,0) [0|7] ""  SRS3
 SG_ DrvrCrsCtrlFctSeld_UB : 24|1@0+ (1,0) [0|1] ""  SRS3
 SG_ EscSt_UB : 39|1@0+ (1,0) [0|1] ""  SRS3
 SG_ EscStChks : 47|8@0+ (1,0) [0|255] "Unitless"  SRS3
 SG_ EscStCntr : 35|4@0+ (1,0) [0|15] "Unitless"  SRS3
 SG_ EscStEscSt : 38|3@0+ (1,0) [0|7] ""  SRS3

BO_ 916 ZCUDZCUDCAN1Fr20: 8 ZCUD
 SG_ LeFrntTireMsg_UB : 31|1@0+ (1,0) [0|1] ""  SRS3
 SG_ LeFrntTireMsgBattLoSt : 7|1@0+ (1,0) [0|1] ""  SRS3
 SG_ LeFrntTireMsgFastLoseWarnFlg : 6|1@0+ (1,0) [0|1] ""  SRS3
 SG_ LeFrntTireMsgMsgOldFlg : 5|1@0+ (1,0) [0|1] ""  SRS3
 SG_ LeFrntTireMsgP : 15|8@0+ (1.373,0) [0|350.115] "KiloPa"  SRS3
 SG_ LeFrntTireMsgPWarnFlg : 4|2@0+ (1,0) [0|3] ""  SRS3
 SG_ LeFrntTireMsgSysWarnFlg : 2|1@0+ (1,0) [0|1] ""  SRS3
 SG_ LeFrntTireMsgT : 23|8@0+ (1,-50) [-50|205] "degC"  SRS3
 SG_ LeFrntTireMsgTireFillgAssiPSts : 0|1@0+ (1,0) [0|1] ""  SRS3
 SG_ LeFrntTireMsgTWarnFlg : 1|1@0+ (1,0) [0|1] ""  SRS3
 SG_ LeReTireMsg_UB : 30|1@0+ (1,0) [0|1] ""  SRS3
 SG_ LeReTireMsgBattLoSt : 47|1@0+ (1,0) [0|1] ""  SRS3
 SG_ LeReTireMsgFastLoseWarnFlg : 46|1@0+ (1,0) [0|1] ""  SRS3
 SG_ LeReTireMsgMsgOldFlg : 45|1@0+ (1,0) [0|1] ""  SRS3
 SG_ LeReTireMsgP : 55|8@0+ (1.373,0) [0|350.115] "KiloPa"  SRS3
 SG_ LeReTireMsgPWarnFlg : 44|2@0+ (1,0) [0|3] ""  SRS3
 SG_ LeReTireMsgSysWarnFlg : 42|1@0+ (1,0) [0|1] ""  SRS3
 SG_ LeReTireMsgT : 63|8@0+ (1,-50) [-50|205] "degC"  SRS3
 SG_ LeReTireMsgTireFillgAssiPSts : 40|1@0+ (1,0) [0|1] ""  SRS3
 SG_ LeReTireMsgTWarnFlg : 41|1@0+ (1,0) [0|1] ""  SRS3

BO_ 920 ZCUDZCUDCAN1Fr21: 8 ZCUD
 SG_ PassSeatPosPerc_UB : 2|1@0+ (1,0) [0|1] ""  SRS3
 SG_ PassSeatPosPercSeatPosFrntHeiPer : 15|10@0+ (0.1,0) [0|100] "%"  SRS3
 SG_ PassSeatPosPercSeatPosFrntHeiQF : 1|2@0+ (1,0) [0|3] ""  SRS3
 SG_ PassSeatPosPercSeatPosHeiPerc : 17|10@0+ (0.1,0) [0|100] "%"  SRS3
 SG_ PassSeatPosPercSeatPosHeiQF : 19|2@0+ (1,0) [0|3] ""  SRS3
 SG_ PassSeatPosPercSeatPosSldPerc : 39|10@0+ (0.1,0) [0|100] "%"  SRS3
 SG_ PassSeatPosPercSeatPosSldQF : 21|2@0+ (1,0) [0|3] ""  SRS3
 SG_ PinionSteerAgMax1 : 55|15@0- (0.0009765625,0) [-14.5|14.5] "rad"  SRS3
 SG_ PinionSteerAgMax1_UB : 56|1@0+ (1,0) [0|1] ""  SRS3

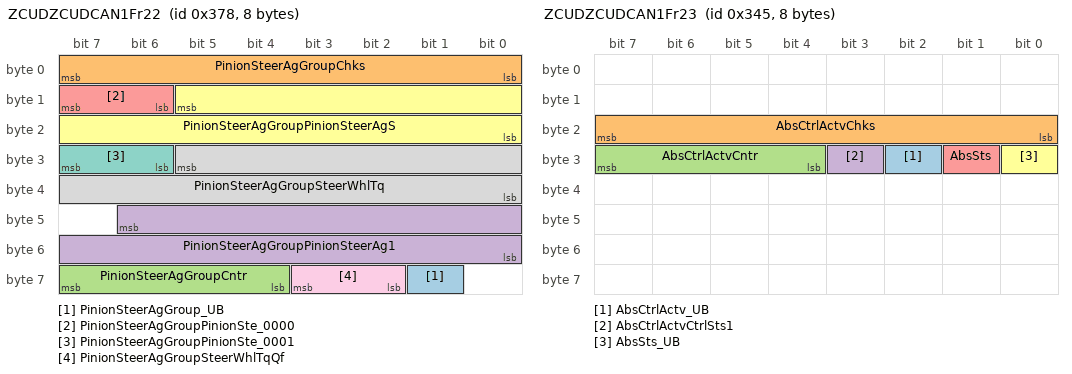
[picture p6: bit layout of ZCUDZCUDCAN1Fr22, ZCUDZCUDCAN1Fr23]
BO_ 888 ZCUDZCUDCAN1Fr22: 8 ZCUD
 SG_ PinionSteerAgGroup_UB : 57|1@0+ (1,0) [0|1] ""  SRS3
 SG_ PinionSteerAgGroupChks : 7|8@0+ (1,0) [0|255] "Unitless"  SRS3
 SG_ PinionSteerAgGroupCntr : 63|4@0+ (1,0) [0|15] "Unitless"  SRS3
 SG_ PinionSteerAgGroupPinionSteerAg1 : 46|15@0- (0.0009765625,0) [-14.5|14.5] "rad"  SRS3
 SG_ PinionSteerAgGroupPinionSte_0000 : 15|2@0+ (1,0) [0|3] ""  SRS3
 SG_ PinionSteerAgGroupPinionSteerAgS : 13|14@0- (0.0078125,0) [-50|50] "rad/s"  SRS3
 SG_ PinionSteerAgGroupPinionSte_0001 : 31|2@0+ (1,0) [0|3] ""  SRS3
 SG_ PinionSteerAgGroupSteerWhlTq : 29|14@0- (0.00390625,0) [-30|30] "NewtonMeter"  SRS3
 SG_ PinionSteerAgGroupSteerWhlTqQf : 59|2@0+ (1,0) [0|3] ""  SRS3

BO_ 837 ZCUDZCUDCAN1Fr23: 8 ZCUD
 SG_ AbsCtrlActv_UB : 26|1@0+ (1,0) [0|1] ""  SRS3
 SG_ AbsCtrlActvChks : 23|8@0+ (1,0) [0|255] "Unitless"  SRS3
 SG_ AbsCtrlActvCntr : 31|4@0+ (1,0) [0|15] "Unitless"  SRS3
 SG_ AbsCtrlActvCtrlSts1 : 27|1@0+ (1,0) [0|1] ""  SRS3
 SG_ AbsSts : 25|1@0+ (1,0) [0|1] ""  SRS3
 SG_ AbsSts_UB : 24|1@0+ (1,0) [0|1] ""  SRS3

BO_ 518 ZCUDZCUDCAN1Fr24: 8 ZCUD
 SG_ AccrPedlRat_UB : 7|1@0+ (1,0) [0|1] ""  SRS3
 SG_ AccrPedlRatAccrPedlRat : 6|15@0+ (0.00390625,0) [0|100] "%"  SRS3
 SG_ AccrPedlRatChks : 23|8@0+ (1,0) [0|255] "Unitless"  SRS3
 SG_ AccrPedlRatCntr : 31|4@0+ (1,0) [0|15] "Unitless"  SRS3
 SG_ AccrPedlRatGrdt : 54|15@0- (0.0625,0) [-1000|1000] "PercPerSec" Vector__XXX
 SG_ AccrPedlRatGrdt_UB : 55|1@0+ (1,0) [0|1] "" Vector__XXX
 SG_ CllsnAidPost : 44|1@0+ (1,0) [0|1] ""  SRS3
 SG_ CllsnAidPost_UB : 45|1@0+ (1,0) [0|1] ""  SRS3
 SG_ SldngDoorLeReModSts : 27|1@0+ (1,0) [0|1] "" Vector__XXX
 SG_ SldngDoorLeReModSts_UB : 26|1@0+ (1,0) [0|1] "" Vector__XXX
 SG_ SldngDoorRiReModSts : 25|1@0+ (1,0) [0|1] "" Vector__XXX
 SG_ SldngDoorRiReModSts_UB : 24|1@0+ (1,0) [0|1] "" Vector__XXX
 SG_ ThrPos : 39|8@0+ (0.5,0) [0|100] "%"  SRS3
 SG_ ThrPos_UB : 47|1@0+ (1,0) [0|1] ""  SRS3
 SG_ TrlrLampChkAutReq : 41|1@0+ (1,0) [0|1] ""  TRM
 SG_ TrlrLampChkAutReq_UB : 40|1@0+ (1,0) [0|1] ""  TRM
 SG_ TwbrRelsReq : 43|2@0+ (1,0) [0|3] ""  TRM
 SG_ TwbrRelsReq_UB : 46|1@0+ (1,0) [0|1] ""  TRM

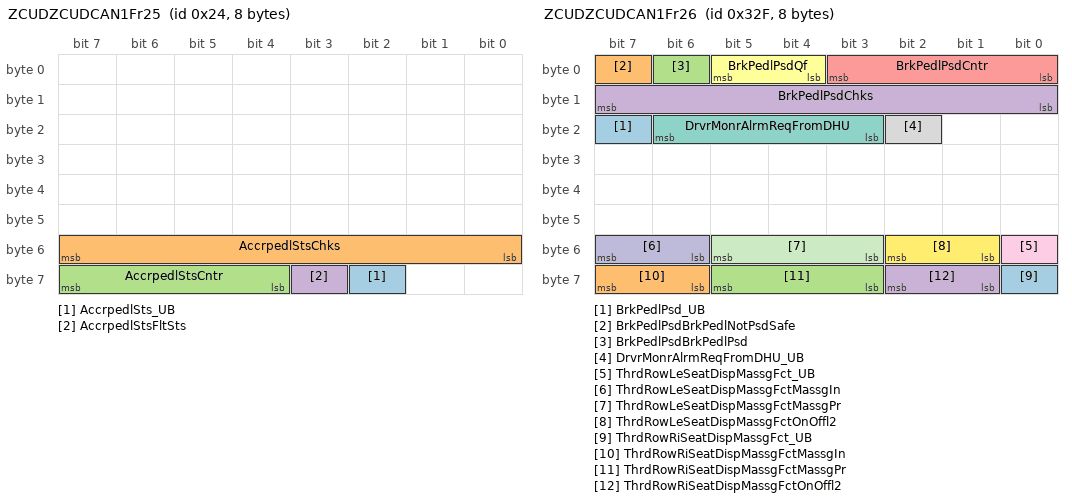
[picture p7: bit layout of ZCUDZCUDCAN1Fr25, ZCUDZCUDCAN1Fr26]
BO_ 36 ZCUDZCUDCAN1Fr25: 8 ZCUD
 SG_ AccrpedlSts_UB : 58|1@0+ (1,0) [0|1] ""  SRS3
 SG_ AccrpedlStsChks : 55|8@0+ (1,0) [0|255] "Unitless"  SRS3
 SG_ AccrpedlStsCntr : 63|4@0+ (1,0) [0|15] "Unitless"  SRS3
 SG_ AccrpedlStsFltSts : 59|1@0+ (1,0) [0|1] ""  SRS3

BO_ 815 ZCUDZCUDCAN1Fr26: 8 ZCUD
 SG_ BrkPedlPsd_UB : 23|1@0+ (1,0) [0|1] ""  SRS3
 SG_ BrkPedlPsdBrkPedlNotPsdSafe : 7|1@0+ (1,0) [0|1] ""  SRS3
 SG_ BrkPedlPsdBrkPedlPsd : 6|1@0+ (1,0) [0|1] ""  SRS3
 SG_ BrkPedlPsdChks : 15|8@0+ (1,0) [0|255] "Unitless"  SRS3
 SG_ BrkPedlPsdCntr : 3|4@0+ (1,0) [0|15] "Unitless"  SRS3
 SG_ BrkPedlPsdQf : 5|2@0+ (1,0) [0|3] ""  SRS3
 SG_ DrvrMonrAlrmReqFromDHU : 22|4@0+ (1,0) [0|15] "Unitless" Vector__XXX
 SG_ DrvrMonrAlrmReqFromDHU_UB : 18|1@0+ (1,0) [0|1] "" Vector__XXX
 SG_ ThrdRowLeSeatDispMassgFct_UB : 48|1@0+ (1,0) [0|1] "" Vector__XXX
 SG_ ThrdRowLeSeatDispMassgFctMassgIn : 55|2@0+ (1,0) [0|3] "" Vector__XXX
 SG_ ThrdRowLeSeatDispMassgFctMassgPr : 53|3@0+ (1,0) [0|7] "" Vector__XXX
 SG_ ThrdRowLeSeatDispMassgFctOnOffl2 : 50|2@0+ (1,0) [0|3] "" Vector__XXX
 SG_ ThrdRowRiSeatDispMassgFct_UB : 56|1@0+ (1,0) [0|1] "" Vector__XXX
 SG_ ThrdRowRiSeatDispMassgFctMassgIn : 63|2@0+ (1,0) [0|3] "" Vector__XXX
 SG_ ThrdRowRiSeatDispMassgFctMassgPr : 61|3@0+ (1,0) [0|7] "" Vector__XXX
 SG_ ThrdRowRiSeatDispMassgFctOnOffl2 : 58|2@0+ (1,0) [0|3] "" Vector__XXX

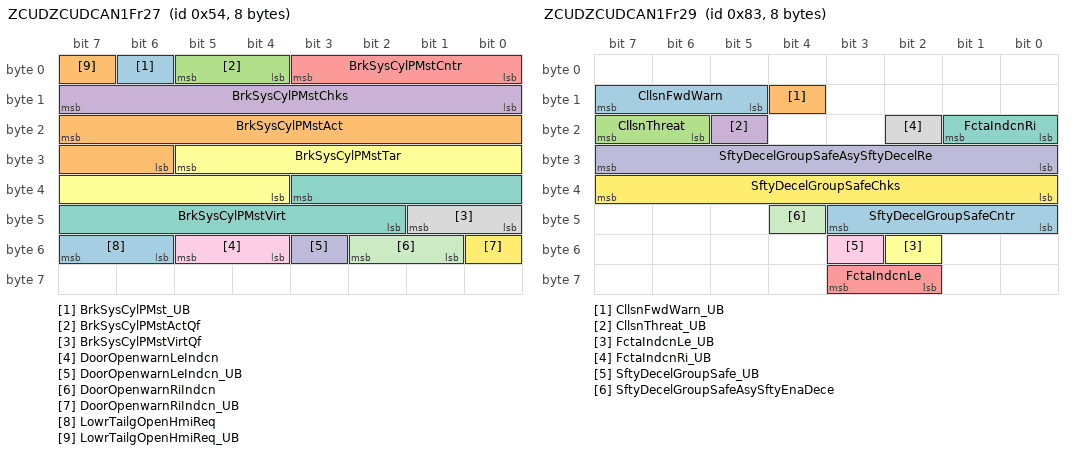
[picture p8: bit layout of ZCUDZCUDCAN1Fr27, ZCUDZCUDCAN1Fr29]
BO_ 84 ZCUDZCUDCAN1Fr27: 8 ZCUD
 SG_ BrkSysCylPMst_UB : 6|1@0+ (1,0) [0|1] ""  SRS3
 SG_ BrkSysCylPMstAct : 23|10@0+ (0.3,-30) [-30|276.6] "bar"  SRS3
 SG_ BrkSysCylPMstActQf : 5|2@0+ (1,0) [0|3] ""  SRS3
 SG_ BrkSysCylPMstChks : 15|8@0+ (1,0) [0|255] "Unitless"  SRS3
 SG_ BrkSysCylPMstCntr : 3|4@0+ (1,0) [0|15] "Unitless"  SRS3
 SG_ BrkSysCylPMstTar : 29|10@0+ (0.25,0) [0|250] "bar"  SRS3
 SG_ BrkSysCylPMstVirt : 35|10@0+ (0.25,0) [0|250] "bar"  SRS3
 SG_ BrkSysCylPMstVirtQf : 41|2@0+ (1,0) [0|3] ""  SRS3
 SG_ DoorOpenwarnLeIndcn : 53|2@0+ (1,0) [0|3] "" Vector__XXX
 SG_ DoorOpenwarnLeIndcn_UB : 51|1@0+ (1,0) [0|1] "" Vector__XXX
 SG_ DoorOpenwarnRiIndcn : 50|2@0+ (1,0) [0|3] "" Vector__XXX
 SG_ DoorOpenwarnRiIndcn_UB : 48|1@0+ (1,0) [0|1] "" Vector__XXX
 SG_ LowrTailgOpenHmiReq : 55|2@0+ (1,0) [0|3] "" Vector__XXX
 SG_ LowrTailgOpenHmiReq_UB : 7|1@0+ (1,0) [0|1] "" Vector__XXX

BO_ 131 ZCUDZCUDCAN1Fr29: 8 ZCUD
 SG_ CllsnFwdWarn : 15|3@0+ (1,0) [0|7] ""  SRS3
 SG_ CllsnFwdWarn_UB : 12|1@0+ (1,0) [0|1] ""  SRS3
 SG_ CllsnThreat : 23|2@0+ (1,0) [0|3] "" Vector__XXX
 SG_ CllsnThreat_UB : 21|1@0+ (1,0) [0|1] "" Vector__XXX
 SG_ FctaIndcnLe : 59|2@0+ (1,0) [0|3] "" Vector__XXX
 SG_ FctaIndcnLe_UB : 50|1@0+ (1,0) [0|1] "" Vector__XXX
 SG_ FctaIndcnRi : 17|2@0+ (1,0) [0|3] "" Vector__XXX
 SG_ FctaIndcnRi_UB : 18|1@0+ (1,0) [0|1] "" Vector__XXX
 SG_ SftyDecelGroupSafe_UB : 51|1@0+ (1,0) [0|1] ""  SRS3
 SG_ SftyDecelGroupSafeAsySftyDecelRe : 31|8@0+ (0.1,0) [0|15] "m/s^2"  SRS3
 SG_ SftyDecelGroupSafeAsySftyEnaDece : 44|1@0+ (1,0) [0|1] ""  SRS3
 SG_ SftyDecelGroupSafeChks : 39|8@0+ (1,0) [0|255] "Unitless"  SRS3
 SG_ SftyDecelGroupSafeCntr : 43|4@0+ (1,0) [0|15] "Unitless"  SRS3

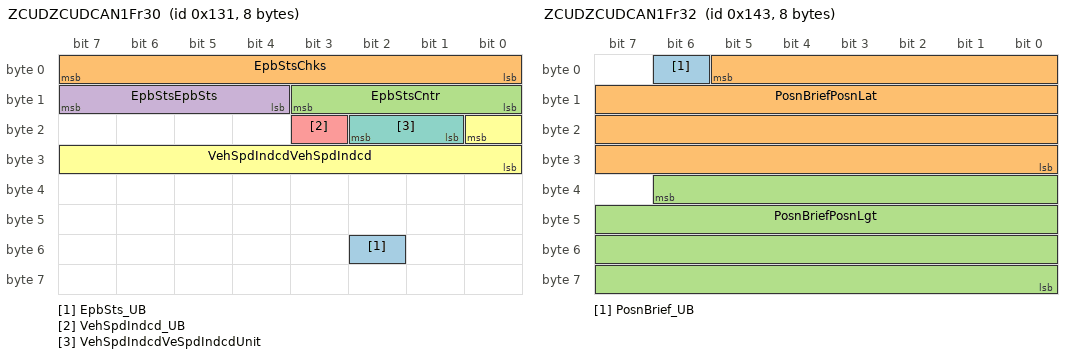
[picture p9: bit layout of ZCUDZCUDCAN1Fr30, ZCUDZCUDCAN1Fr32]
BO_ 305 ZCUDZCUDCAN1Fr30: 8 ZCUD
 SG_ EpbSts_UB : 50|1@0+ (1,0) [0|1] ""  SRS3
 SG_ EpbStsChks : 7|8@0+ (1,0) [0|255] "Unitless"  SRS3
 SG_ EpbStsCntr : 11|4@0+ (1,0) [0|15] "Unitless"  SRS3
 SG_ EpbStsEpbSts : 15|4@0+ (1,0) [0|15] ""  SRS3
 SG_ VehSpdIndcd_UB : 19|1@0+ (1,0) [0|1] ""  SRS3
 SG_ VehSpdIndcdVehSpdIndcd : 16|9@0+ (1,0) [0|511] "Unitless"  SRS3
 SG_ VehSpdIndcdVeSpdIndcdUnit : 18|2@0+ (1,0) [0|3] ""  SRS3

BO_ 120 ZCUDZCUDCAN1Fr31: 8 ZCUD
 SG_ GearLvrIndcn : 54|3@0+ (1,0) [0|7] ""  SRS3
 SG_ GearLvrIndcn_UB : 55|1@0+ (1,0) [0|1] ""  SRS3
 SG_ OccupyMonSts_UB : 28|1@0+ (1,0) [0|1] "" Vector__XXX
 SG_ OccupyMonStsDrvrSts : 27|2@0+ (1,0) [0|3] "" Vector__XXX
 SG_ OccupyMonStsPassSts : 25|2@0+ (1,0) [0|3] "" Vector__XXX
 SG_ OccupyMonStsSeccLeSts : 39|2@0+ (1,0) [0|3] "" Vector__XXX
 SG_ OccupyMonStsSecMidSts : 37|2@0+ (1,0) [0|3] "" Vector__XXX
 SG_ OccupyMonStsSecRiSts : 35|2@0+ (1,0) [0|3] "" Vector__XXX
 SG_ OccupyMonStsThrdLeSts : 33|2@0+ (1,0) [0|3] "" Vector__XXX
 SG_ OccupyMonStsThrdMidSts : 47|2@0+ (1,0) [0|3] "" Vector__XXX
 SG_ OccupyMonStsThrdRiSts : 45|2@0+ (1,0) [0|3] "" Vector__XXX
 SG_ SeatOccptAtRowSecPasSide2 : 43|2@0+ (1,0) [0|3] "" Vector__XXX
 SG_ SeatOccptAtRowSecPasSide2_UB : 41|1@0+ (1,0) [0|1] "" Vector__XXX
 SG_ SeatOccptAtRowSecPasSideSnsSts2 : 51|2@0+ (1,0) [0|3] "" Vector__XXX
 SG_ SeatOccptAtRowSecPasSideSnsSts2_ : 40|1@0+ (1,0) [0|1] "" Vector__XXX
 SG_ SwtIndcr_UB : 6|1@0+ (1,0) [0|1] ""  SRS3
 SG_ SwtIndcrIndcrTypExtReq : 5|2@0+ (1,0) [0|3] ""  SRS3
 SG_ SwtIndcrIndcrTypExtReqChks : 15|8@0+ (1,0) [0|255] "Unitless"  SRS3
 SG_ SwtIndcrIndcrTypExtReqCntr : 3|2@0+ (1,0) [0|3] "Unitless"  SRS3
 SG_ SwtIndcrIndcrTypExtReqToUpdQf : 1|2@0+ (1,0) [0|3] ""  SRS3

BO_ 323 ZCUDZCUDCAN1Fr32: 8 ZCUD
 SG_ PosnBrief_UB : 6|1@0+ (1,0) [0|1] ""  SRS3
 SG_ PosnBriefPosnLat : 5|30@0- (2.77777777777778E-007,0) [-90|90] "Deg"  SRS3
 SG_ PosnBriefPosnLgt : 38|31@0- (2.77777777777778E-007,0) [-180|180] "Deg"  SRS3

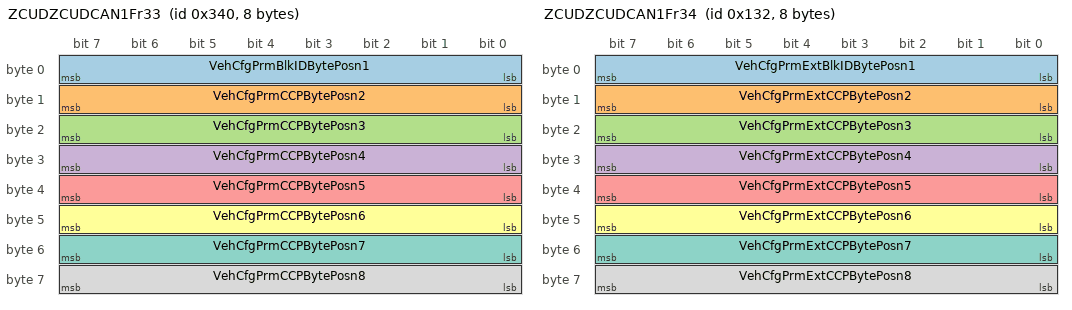
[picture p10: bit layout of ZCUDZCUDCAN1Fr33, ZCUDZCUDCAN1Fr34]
BO_ 832 ZCUDZCUDCAN1Fr33: 8 ZCUD
 SG_ VehCfgPrmBlkIDBytePosn1 : 7|8@0+ (1,0) [0|255] "Unitless"  OGM,POT,SRS3,TRM
 SG_ VehCfgPrmCCPBytePosn2 : 15|8@0+ (1,0) [0|255] "Unitless"  OGM,POT,SRS3,TRM
 SG_ VehCfgPrmCCPBytePosn3 : 23|8@0+ (1,0) [0|255] "Unitless"  OGM,POT,SRS3,TRM
 SG_ VehCfgPrmCCPBytePosn4 : 31|8@0+ (1,0) [0|255] "Unitless"  OGM,POT,SRS3,TRM
 SG_ VehCfgPrmCCPBytePosn5 : 39|8@0+ (1,0) [0|255] "Unitless"  OGM,POT,SRS3,TRM
 SG_ VehCfgPrmCCPBytePosn6 : 47|8@0+ (1,0) [0|255] "Unitless"  OGM,POT,SRS3,TRM
 SG_ VehCfgPrmCCPBytePosn7 : 55|8@0+ (1,0) [0|255] "Unitless"  OGM,POT,SRS3,TRM
 SG_ VehCfgPrmCCPBytePosn8 : 63|8@0+ (1,0) [0|255] "Unitless"  OGM,POT,SRS3,TRM

BO_ 306 ZCUDZCUDCAN1Fr34: 8 ZCUD
 SG_ VehCfgPrmExtBlkIDBytePosn1 : 7|8@0+ (1,0) [0|255] "Unitless"  OGM,POT,SRS3,TRM
 SG_ VehCfgPrmExtCCPBytePosn2 : 15|8@0+ (1,0) [0|255] "Unitless"  OGM,POT,SRS3,TRM
 SG_ VehCfgPrmExtCCPBytePosn3 : 23|8@0+ (1,0) [0|255] "Unitless"  OGM,POT,SRS3,TRM
 SG_ VehCfgPrmExtCCPBytePosn4 : 31|8@0+ (1,0) [0|255] "Unitless"  OGM,POT,SRS3,TRM
 SG_ VehCfgPrmExtCCPBytePosn5 : 39|8@0+ (1,0) [0|255] "Unitless"  OGM,POT,SRS3,TRM
 SG_ VehCfgPrmExtCCPBytePosn6 : 47|8@0+ (1,0) [0|255] "Unitless"  OGM,POT,SRS3,TRM
 SG_ VehCfgPrmExtCCPBytePosn7 : 55|8@0+ (1,0) [0|255] "Unitless"  OGM,POT,SRS3,TRM
 SG_ VehCfgPrmExtCCPBytePosn8 : 63|8@0+ (1,0) [0|255] "Unitless"  OGM,POT,SRS3,TRM

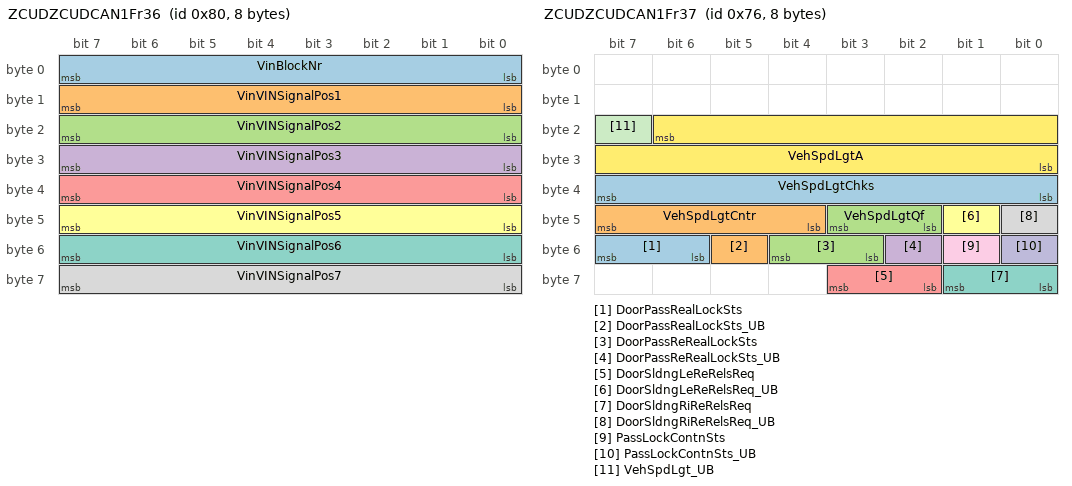
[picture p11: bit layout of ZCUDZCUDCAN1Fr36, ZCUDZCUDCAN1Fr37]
BO_ 128 ZCUDZCUDCAN1Fr36: 8 ZCUD
 SG_ VinBlockNr : 7|8@0+ (1,0) [0|255] "Unitless"  SRS3
 SG_ VinVINSignalPos1 : 15|8@0+ (1,0) [0|255] "Unitless"  SRS3
 SG_ VinVINSignalPos2 : 23|8@0+ (1,0) [0|255] "Unitless"  SRS3
 SG_ VinVINSignalPos3 : 31|8@0+ (1,0) [0|255] "Unitless"  SRS3
 SG_ VinVINSignalPos4 : 39|8@0+ (1,0) [0|255] "Unitless"  SRS3
 SG_ VinVINSignalPos5 : 47|8@0+ (1,0) [0|255] "Unitless"  SRS3
 SG_ VinVINSignalPos6 : 55|8@0+ (1,0) [0|255] "Unitless"  SRS3
 SG_ VinVINSignalPos7 : 63|8@0+ (1,0) [0|255] "Unitless"  SRS3

BO_ 118 ZCUDZCUDCAN1Fr37: 8 ZCUD
 SG_ DoorPassRealLockSts : 55|2@0+ (1,0) [0|3] "" Vector__XXX
 SG_ DoorPassRealLockSts_UB : 53|1@0+ (1,0) [0|1] "" Vector__XXX
 SG_ DoorPassReRealLockSts : 52|2@0+ (1,0) [0|3] "" Vector__XXX
 SG_ DoorPassReRealLockSts_UB : 50|1@0+ (1,0) [0|1] "" Vector__XXX
 SG_ DoorSldngLeReRelsReq : 59|2@0+ (1,0) [0|3] "" Vector__XXX
 SG_ DoorSldngLeReRelsReq_UB : 41|1@0+ (1,0) [0|1] "" Vector__XXX
 SG_ DoorSldngRiReRelsReq : 57|2@0+ (1,0) [0|3] "" Vector__XXX
 SG_ DoorSldngRiReRelsReq_UB : 40|1@0+ (1,0) [0|1] "" Vector__XXX
 SG_ PassLockContnSts : 49|1@0+ (1,0) [0|1] "" Vector__XXX
 SG_ PassLockContnSts_UB : 48|1@0+ (1,0) [0|1] "" Vector__XXX
 SG_ VehSpdLgt_UB : 23|1@0+ (1,0) [0|1] ""  OGM,POT,SRS3,TRM
 SG_ VehSpdLgtA : 22|15@0+ (0.00391,0) [0|125.0027] "m/s"  OGM,POT,SRS3,TRM
 SG_ VehSpdLgtChks : 39|8@0+ (1,0) [0|255] "Unitless"  OGM,POT,SRS3,TRM
 SG_ VehSpdLgtCntr : 47|4@0+ (1,0) [0|15] "Unitless"  OGM,POT,SRS3,TRM
 SG_ VehSpdLgtQf : 43|2@0+ (1,0) [0|3] ""  OGM,POT,SRS3,TRM

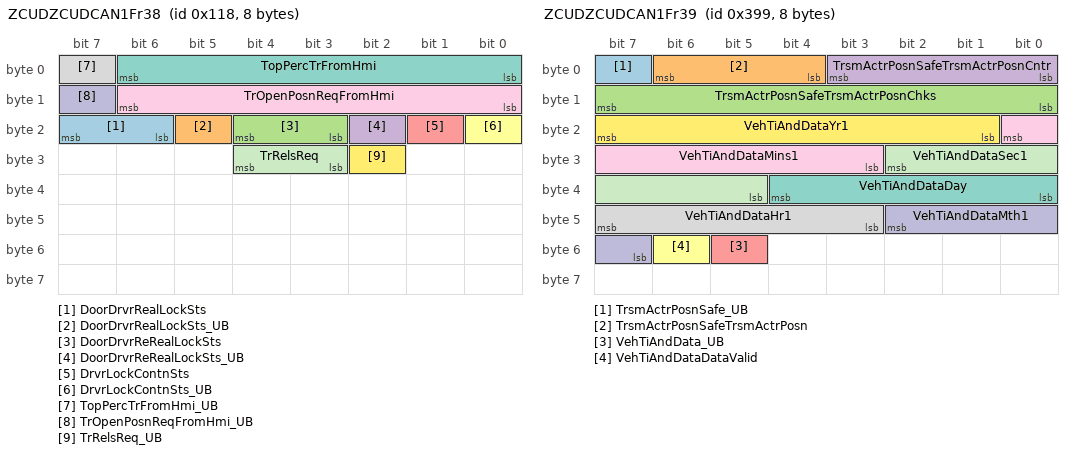
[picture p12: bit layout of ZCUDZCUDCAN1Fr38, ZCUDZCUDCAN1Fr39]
BO_ 280 ZCUDZCUDCAN1Fr38: 8 ZCUD
 SG_ DoorDrvrRealLockSts : 23|2@0+ (1,0) [0|3] "" Vector__XXX
 SG_ DoorDrvrRealLockSts_UB : 21|1@0+ (1,0) [0|1] "" Vector__XXX
 SG_ DoorDrvrReRealLockSts : 20|2@0+ (1,0) [0|3] "" Vector__XXX
 SG_ DoorDrvrReRealLockSts_UB : 18|1@0+ (1,0) [0|1] "" Vector__XXX
 SG_ DrvrLockContnSts : 17|1@0+ (1,0) [0|1] "" Vector__XXX
 SG_ DrvrLockContnSts_UB : 16|1@0+ (1,0) [0|1] "" Vector__XXX
 SG_ TopPercTrFromHmi : 6|7@0+ (1,0) [0|101] "%" Vector__XXX
 SG_ TopPercTrFromHmi_UB : 7|1@0+ (1,0) [0|1] "" Vector__XXX
 SG_ TrOpenPosnReqFromHmi : 14|7@0+ (1,0) [0|101] "%" Vector__XXX
 SG_ TrOpenPosnReqFromHmi_UB : 15|1@0+ (1,0) [0|1] "" Vector__XXX
 SG_ TrRelsReq : 28|2@0+ (1,0) [0|3] ""  POT
 SG_ TrRelsReq_UB : 26|1@0+ (1,0) [0|1] ""  POT

BO_ 921 ZCUDZCUDCAN1Fr39: 8 ZCUD
 SG_ TrsmActrPosnSafe_UB : 7|1@0+ (1,0) [0|1] ""  SRS3
 SG_ TrsmActrPosnSafeTrsmActrPosn : 6|3@0+ (1,0) [0|7] ""  SRS3
 SG_ TrsmActrPosnSafeTrsmActrPosnChks : 15|8@0+ (1,0) [0|255] "Unitless"  SRS3
 SG_ TrsmActrPosnSafeTrsmActrPosnCntr : 3|4@0+ (1,0) [0|15] "Unitless"  SRS3
 SG_ VehTiAndData_UB : 53|1@0+ (1,0) [0|1] ""  SRS3
 SG_ VehTiAndDataDataValid : 54|1@0+ (1,0) [0|1] ""  SRS3
 SG_ VehTiAndDataDay : 36|5@0+ (1,0) [1|31] "Days"  SRS3
 SG_ VehTiAndDataHr1 : 47|5@0+ (1,0) [0|23] "hours"  SRS3
 SG_ VehTiAndDataMins1 : 16|6@0+ (1,0) [0|59] "Mins"  SRS3
 SG_ VehTiAndDataMth1 : 42|4@0+ (1,0) [1|12] "Month"  SRS3
 SG_ VehTiAndDataSec1 : 26|6@0+ (1,0) [0|59] "s"  SRS3
 SG_ VehTiAndDataYr1 : 23|7@0+ (1,0) [0|99] "Year"  SRS3

BO_ 552 ZCUDZCUDCAN1Fr40: 8 ZCUD
 SG_ DrvrSeatAdpvLumSetg : 49|1@0+ (1,0) [0|1] "" Vector__XXX
 SG_ DrvrSeatAdpvLumSetg_UB : 48|1@0+ (1,0) [0|1] "" Vector__XXX
 SG_ HmiSeatHeatgForRowSecLe : 7|3@0+ (1,0) [0|7] "" Vector__XXX
 SG_ HmiSeatHeatgForRowSecLe_UB : 1|1@0+ (1,0) [0|1] "" Vector__XXX
 SG_ HmiSeatHeatgForRowSecRi : 4|3@0+ (1,0) [0|7] "" Vector__XXX
 SG_ HmiSeatHeatgForRowSecRi_UB : 0|1@0+ (1,0) [0|1] "" Vector__XXX
 SG_ HmiSeatHeatgForRowThrdLe : 15|3@0+ (1,0) [0|7] "" Vector__XXX
 SG_ HmiSeatHeatgForRowThrdLe_UB : 9|1@0+ (1,0) [0|1] "" Vector__XXX
 SG_ HmiSeatHeatgForRowThrdRi : 12|3@0+ (1,0) [0|7] "" Vector__XXX
 SG_ HmiSeatHeatgForRowThrdRi_UB : 8|1@0+ (1,0) [0|1] "" Vector__XXX
 SG_ HmiSeatVentnForRowSecLe : 23|3@0+ (1,0) [0|7] "" Vector__XXX
 SG_ HmiSeatVentnForRowSecLe_UB : 17|1@0+ (1,0) [0|1] "" Vector__XXX
 SG_ HmiSeatVentnForRowSecRi : 20|3@0+ (1,0) [0|7] "" Vector__XXX
 SG_ HmiSeatVentnForRowSecRi_UB : 16|1@0+ (1,0) [0|1] "" Vector__XXX
 SG_ HmiSeatVentnForRowThrdLe : 31|3@0+ (1,0) [0|7] "" Vector__XXX
 SG_ HmiSeatVentnForRowThrdLe_UB : 25|1@0+ (1,0) [0|1] "" Vector__XXX
 SG_ HmiSeatVentnForRowThrdRi : 28|3@0+ (1,0) [0|7] "" Vector__XXX
 SG_ HmiSeatVentnForRowThrdRi_UB : 24|1@0+ (1,0) [0|1] "" Vector__XXX
 SG_ KeyScanActv : 63|1@0+ (1,0) [0|1] "" Vector__XXX
 SG_ KeyScanActv_UB : 62|1@0+ (1,0) [0|1] "" Vector__XXX
 SG_ PrkgStsToEDR_UB : 50|1@0+ (1,0) [0|1] ""  SRS3
 SG_ PrkgStsToEDRAPATo : 39|3@0+ (1,0) [0|7] ""  SRS3
 SG_ PrkgStsToEDRHPATo : 36|3@0+ (1,0) [0|7] ""  SRS3
 SG_ PrkgStsToEDRLSDAandTBATo : 33|3@0+ (1,0) [0|7] ""  SRS3
 SG_ PrkgStsToEDRreserved1 : 46|3@0+ (1,0) [0|7] ""  SRS3
 SG_ PrkgStsToEDRreserved2 : 43|3@0+ (1,0) [0|7] ""  SRS3
 SG_ PrkgStsToEDRreserved3 : 40|3@0+ (1,0) [0|7] ""  SRS3
 SG_ PrkgStsToEDRRPATo : 53|3@0+ (1,0) [0|7] ""  SRS3

CM_ SG_ 1290 WakeUpReasonsforTRM "WakeUpReasons";
CM_ SG_ 1354 VFCVectorTRMBlockID "BlockID";
CM_ SG_ 1354 VFCVectorTRMVFCid0 "SettingsComfort";
CM_ SG_ 1354 VFCVectorTRMVFCid1 "ParkingDrivingClimatization";
CM_ SG_ 1354 VFCVectorTRMVFCid10 "ExteriorLighting";
CM_ SG_ 1354 VFCVectorTRMVFCid11 "VFC11";
CM_ SG_ 1354 VFCVectorTRMVFCid12 "Alarm";
CM_ SG_ 1354 VFCVectorTRMVFCid13 "VFC13";
CM_ SG_ 1354 VFCVectorTRMVFCid14 "InteriorLighting";
CM_ SG_ 1354 VFCVectorTRMVFCid15 "VFC15";
CM_ SG_ 1354 VFCVectorTRMVFCid16 "Locking";
CM_ SG_ 1354 VFCVectorTRMVFCid17 "emoteKeyFunctionality";
CM_ SG_ 1354 VFCVectorTRMVFCid18 "PropulsionStart";
CM_ SG_ 1354 VFCVectorTRMVFCid19 "VFC19";
CM_ SG_ 1354 VFCVectorTRMVFCid2 "PostClimatisation";
CM_ SG_ 1354 VFCVectorTRMVFCid20 "VFC20";
CM_ SG_ 1354 VFCVectorTRMVFCid21 "PowerClosures";
CM_ SG_ 1354 VFCVectorTRMVFCid22 "VehicleDriving";
CM_ SG_ 1354 VFCVectorTRMVFCid23 "VFC23";
CM_ SG_ 1354 VFCVectorTRMVFCid24 "SettingsProfile";
CM_ SG_ 1354 VFCVectorTRMVFCid25 "SeatComfortFunctions";
CM_ SG_ 1354 VFCVectorTRMVFCid26 "Brake";
CM_ SG_ 1354 VFCVectorTRMVFCid27 "InfotainmentPoll";
CM_ SG_ 1354 VFCVectorTRMVFCid28 "HVEnergyStorage";
CM_ SG_ 1354 VFCVectorTRMVFCid29 "VFC29";
CM_ SG_ 1354 VFCVectorTRMVFCid3 "PowertrainParkingClimatization";
CM_ SG_ 1354 VFCVectorTRMVFCid30 "TelematicsConnectivity";
CM_ SG_ 1354 VFCVectorTRMVFCid31 "VFC31";
CM_ SG_ 1354 VFCVectorTRMVFCid32 "VFC32";
CM_ SG_ 1354 VFCVectorTRMVFCid33 "Diagnostics";
CM_ SG_ 1354 VFCVectorTRMVFCid34 "VehicleModeManagement";
CM_ SG_ 1354 VFCVectorTRMVFCid35 "TrailerCaravanFunctions";
CM_ SG_ 1354 VFCVectorTRMVFCid36 "Immobilizer";
CM_ SG_ 1354 VFCVectorTRMVFCid37 "Windows";
CM_ SG_ 1354 VFCVectorTRMVFCid38 "Visibility";
CM_ SG_ 1354 VFCVectorTRMVFCid39 "VFC39";
CM_ SG_ 1354 VFCVectorTRMVFCid4 "VFC4";
CM_ SG_ 1354 VFCVectorTRMVFCid40 "VFC40";
CM_ SG_ 1354 VFCVectorTRMVFCid41 "InfotainmentPush";
CM_ SG_ 1354 VFCVectorTRMVFCid42 "ChargingHV";
CM_ SG_ 1354 VFCVectorTRMVFCid43 "BodyPreClimatisation";
CM_ SG_ 1354 VFCVectorTRMVFCid44 "Crash";
CM_ SG_ 1354 VFCVectorTRMVFCid45 "GlobalShortDuration";
CM_ SG_ 1354 VFCVectorTRMVFCid46 "ExteriorLightsHazard";
CM_ SG_ 1354 VFCVectorTRMVFCid47 "VFC47";
CM_ SG_ 1354 VFCVectorTRMVFCid48 "DoorOpenWarning";
CM_ SG_ 1354 VFCVectorTRMVFCid49 "ChargingLVInit";
CM_ SG_ 1354 VFCVectorTRMVFCid5 "VFC5";
CM_ SG_ 1354 VFCVectorTRMVFCid50 "VFC50";
CM_ SG_ 1354 VFCVectorTRMVFCid51 "VFC51";
CM_ SG_ 1354 VFCVectorTRMVFCid52 "HVBatteryThermalEventWarning";
CM_ SG_ 1354 VFCVectorTRMVFCid53 "VisualAssist";
CM_ SG_ 1354 VFCVectorTRMVFCid54 "PassiveSafety";
CM_ SG_ 1354 VFCVectorTRMVFCid55 "LifeDetection";
CM_ SG_ 1354 VFCVectorTRMVFCid56 "BackboneFlexray";
CM_ SG_ 1354 VFCVectorTRMVFCid57 "Functionmarket";
CM_ SG_ 1354 VFCVectorTRMVFCid58 "VFCid58";
CM_ SG_ 1354 VFCVectorTRMVFCid59 "VFCid59";
CM_ SG_ 1354 VFCVectorTRMVFCid6 "SettingsVehicle";
CM_ SG_ 1354 VFCVectorTRMVFCid60 "VFCid60";
CM_ SG_ 1354 VFCVectorTRMVFCid61 "VFCid61";
CM_ SG_ 1354 VFCVectorTRMVFCid7 "VFC7";
CM_ SG_ 1354 VFCVectorTRMVFCid8 "VFC8";
CM_ SG_ 1354 VFCVectorTRMVFCid9 "IPWakeup";
CM_ SG_ 1345 VFCVectorZCUDMBlockID "BlockID";
CM_ SG_ 1345 VFCVectorZCUDMVFCid0 "SettingsComfort";
CM_ SG_ 1345 VFCVectorZCUDMVFCid1 "ParkingDrivingClimatization";
CM_ SG_ 1345 VFCVectorZCUDMVFCid10 "ExteriorLighting";
CM_ SG_ 1345 VFCVectorZCUDMVFCid11 "VFC11";
CM_ SG_ 1345 VFCVectorZCUDMVFCid12 "Alarm";
CM_ SG_ 1345 VFCVectorZCUDMVFCid13 "VFC13";
CM_ SG_ 1345 VFCVectorZCUDMVFCid14 "InteriorLighting";
CM_ SG_ 1345 VFCVectorZCUDMVFCid15 "VFC15";
CM_ SG_ 1345 VFCVectorZCUDMVFCid16 "Locking";
CM_ SG_ 1345 VFCVectorZCUDMVFCid17 "RemoteKeyFunctionality";
CM_ SG_ 1345 VFCVectorZCUDMVFCid18 "PropulsionStart";
CM_ SG_ 1345 VFCVectorZCUDMVFCid19 "VFC19";
CM_ SG_ 1345 VFCVectorZCUDMVFCid2 "PostClimatisation";
CM_ SG_ 1345 VFCVectorZCUDMVFCid20 "VFC20";
CM_ SG_ 1345 VFCVectorZCUDMVFCid21 "PowerClosures";
CM_ SG_ 1345 VFCVectorZCUDMVFCid22 "VehicleDriving";
CM_ SG_ 1345 VFCVectorZCUDMVFCid23 "VFC23";
CM_ SG_ 1345 VFCVectorZCUDMVFCid24 "SettingsProfile";
CM_ SG_ 1345 VFCVectorZCUDMVFCid25 "SeatComfortFunctions";
CM_ SG_ 1345 VFCVectorZCUDMVFCid26 "Brake";
CM_ SG_ 1345 VFCVectorZCUDMVFCid27 "InfotainmentPoll";
CM_ SG_ 1345 VFCVectorZCUDMVFCid28 "HVEnergyStorage";
CM_ SG_ 1345 VFCVectorZCUDMVFCid29 "VFC29";
CM_ SG_ 1345 VFCVectorZCUDMVFCid3 "PowertrainParkingClimatization";
CM_ SG_ 1345 VFCVectorZCUDMVFCid30 "TelematicsConnectivity";
CM_ SG_ 1345 VFCVectorZCUDMVFCid31 "VFC31";
CM_ SG_ 1345 VFCVectorZCUDMVFCid32 "VFC32";
CM_ SG_ 1345 VFCVectorZCUDMVFCid33 "Diagnostics";
CM_ SG_ 1345 VFCVectorZCUDMVFCid34 "VehicleModeManagement";
CM_ SG_ 1345 VFCVectorZCUDMVFCid35 "TrailerCaravanFunctions";
CM_ SG_ 1345 VFCVectorZCUDMVFCid36 "Immobilizer";
CM_ SG_ 1345 VFCVectorZCUDMVFCid37 "Windows";
CM_ SG_ 1345 VFCVectorZCUDMVFCid38 "Visibility";
CM_ SG_ 1345 VFCVectorZCUDMVFCid39 "VFC39";
CM_ SG_ 1345 VFCVectorZCUDMVFCid4 "VFC4";
CM_ SG_ 1345 VFCVectorZCUDMVFCid40 "VFC40";
CM_ SG_ 1345 VFCVectorZCUDMVFCid41 "InfotainmentPush";
CM_ SG_ 1345 VFCVectorZCUDMVFCid42 "ChargingHV";
CM_ SG_ 1345 VFCVectorZCUDMVFCid43 "BodyPreClimatisation";
CM_ SG_ 1345 VFCVectorZCUDMVFCid44 "Crash";
CM_ SG_ 1345 VFCVectorZCUDMVFCid45 "GlobalShortDuration";
CM_ SG_ 1345 VFCVectorZCUDMVFCid46 "ExteriorLightsHazard";
CM_ SG_ 1345 VFCVectorZCUDMVFCid47 "VFC47";
CM_ SG_ 1345 VFCVectorZCUDMVFCid48 "DoorOpenWarning";
CM_ SG_ 1345 VFCVectorZCUDMVFCid49 "ChargingLVInit";
CM_ SG_ 1345 VFCVectorZCUDMVFCid5 "VFC5";
CM_ SG_ 1345 VFCVectorZCUDMVFCid50 "VFC50";
CM_ SG_ 1345 VFCVectorZCUDMVFCid51 "VFC51";
CM_ SG_ 1345 VFCVectorZCUDMVFCid52 "HVBatteryThermalEventWarning";
CM_ SG_ 1345 VFCVectorZCUDMVFCid53 "VisualAssist";
CM_ SG_ 1345 VFCVectorZCUDMVFCid54 "PassiveSafety";
CM_ SG_ 1345 VFCVectorZCUDMVFCid55 "LifeDetection";
CM_ SG_ 1345 VFCVectorZCUDMVFCid56 "BackboneFlexray";
CM_ SG_ 1345 VFCVectorZCUDMVFCid57 "Functionmarket";
CM_ SG_ 1345 VFCVectorZCUDMVFCid58 "VFCid58";
CM_ SG_ 1345 VFCVectorZCUDMVFCid59 "VFCid59";
CM_ SG_ 1345 VFCVectorZCUDMVFCid6 "SettingsVehicle";
CM_ SG_ 1345 VFCVectorZCUDMVFCid60 "VFCid60";
CM_ SG_ 1345 VFCVectorZCUDMVFCid61 "VFCid61";
CM_ SG_ 1345 VFCVectorZCUDMVFCid7 "VFC7";
CM_ SG_ 1345 VFCVectorZCUDMVFCid8 "VFC8";
CM_ SG_ 1345 VFCVectorZCUDMVFCid9 "IPWakeup";
CM_ SG_ 64 DoorDrvrSts "DoorDrvrSts - Driver Door Status
Ukwn - Unknown status
Opend - Opened
Clsd - Closed";
CM_ SG_ 64 DoorLeReSts "DoorLeReSts - Left Rear Side Door Status.
Ukwn - Unknown status
Opend - Opened
Clsd - Closed";
CM_ SG_ 64 TrNoKeyPrsntAcoustReq "TrNoKeyPrsntAcoustReq - Request for audible feedback sound when no valid key is present.
The audible sound shall be given when the signal changes value from off to on.";
CM_ SG_ 64 TrOpenerReqTrigSrc "TrOpenerReq - Tailgate or Bootlid Opener Request
Request signal to POT ECU. Signal contains type of request and trig source of request.";
CM_ SG_ 64 TrOpenerReqTrOpenerReq "TrOpenerReq - Tailgate or Bootlid Opener Request
Request signal to POT ECU. Signal contains type of request and trig source of request";
CM_ SG_ 64 TwliBriSts "Day or night status signal. Lux value (not this signal) sent from SUS to CEM and CEM sets day or night signal.";
CM_ SG_ 64 VehMtnStChks "Vehicle motion state information based on wheel speed sensors. Provides information about vehicle stand still and vehicle rolling direction. Checksum for vehicle motion state";
CM_ SG_ 64 VehMtnStCntr "Vehicle motion state information based on wheel speed sensors. Provides information about vehicle stand still and vehicle rolling direction. Counter for vehicle motion state";
CM_ SG_ 64 VehMtnStVehMtnSt "Vehicle motion state information based on wheel speed sensors. Provides information about vehicle stand still and vehicle rolling direction. Vehicle motion state";
CM_ SG_ 1164 ListOfNodToSMx "listofnode";
CM_ SG_ 1164 TiAndDateIndcnDataValid "Current time (Hr, Min and Sec) and date (Year, Months and days) data for indication. See requirement for more information about the signals. Signal qualifier, No means values should be ignored.";
CM_ SG_ 1164 TiAndDateIndcnDay "Current time (Hr, Min and Sec) and date (Year, Months and days) data for indication. See requirement for more information about the signals. Day";
CM_ SG_ 1164 TiAndDateIndcnHr1 "Current time (Hr, Min and Sec) and date (Year, Months and days) data for indication. See requirement for more information about the signals. Hour";
CM_ SG_ 1164 TiAndDateIndcnMins1 "Current time (Hr, Min and Sec) and date (Year, Months and days) data for indication. See requirement for more information about the signals. Minutes";
CM_ SG_ 1164 TiAndDateIndcnMth1 "Current time (Hr, Min and Sec) and date (Year, Months and days) data for indication. See requirement for more information about the signals. Month, 1-12";
CM_ SG_ 1164 TiAndDateIndcnSec1 "Current time (Hr, Min and Sec) and date (Year, Months and days) data for indication. See requirement for more information about the signals. Seconds";
CM_ SG_ 1164 TiAndDateIndcnYr1 "Current time (Hr, Min and Sec) and date (Year, Months and days) data for indication. See requirement for more information about the signals. Year, 0-99";
CM_ SG_ 224 DoorPassSts "DoorPassSts - Passenger Door Status
Ukwn - Unknown status
Opend - Opened
Clsd - Closed";
CM_ SG_ 224 DoorRiReSts "DoorRiReSts - Right Rear Side Door Status
Ukwn - Unknown status
Opend - Opened
Clsd - Closed";
CM_ SG_ 224 IntrBriSts "Rheostat setting. Set by user through rheostat wheel situated on MyCar Module.";
CM_ SG_ 224 TopPosTrFromHmi "This signal is used to set top position of tailgate";
CM_ SG_ 224 TrlrLampChkReqFromHmi "Distribution of trailer lamp check activation from DIM";
CM_ SG_ 224 TrlrLiFogActvt "Controls the trailer foglight on and off.";
CM_ SG_ 224 TrPosnUpprProgmReq "TrPosnUpprProgmReq - Tailgate Upper Position Program Request
POT shall program upper position when this signal changes value from Off to On.";
CM_ SG_ 224 TrSts "TrSts - Tailgate or Bootlid Status
Ukwn - Unknown status
Opend - Opened
Clsd - Closed";
CM_ SG_ 240 TrlrLiPosnActvt "Activation of rear position light including rear SML (Side Marker Light).";
CM_ SG_ 240 VehModMngtGlbSafe1CarModSts1 "CarMode Status";
CM_ SG_ 240 VehModMngtGlbSafe1CarModSubtypWd "CarMode substate status";
CM_ SG_ 240 VehModMngtGlbSafe1Chks "Checksum";
CM_ SG_ 240 VehModMngtGlbSafe1Cntr "Counter";
CM_ SG_ 240 VehModMngtGlbSafe1EgyLvlElecMai "Main energy level in the vehicle.";
CM_ SG_ 240 VehModMngtGlbSafe1EgyLvlElecSubt "Substate of the energy level in the vehicle.";
CM_ SG_ 240 VehModMngtGlbSafe1FltEgyCnsWdSts "High quiescent current detected by CEM via BMS.";
CM_ SG_ 240 VehModMngtGlbSafe1PwrLvlElecMai "Main Power level in the vehicle.";
CM_ SG_ 240 VehModMngtGlbSafe1PwrLvlElecSubt "Substate of the power level in the vehicle.";
CM_ SG_ 240 VehModMngtGlbSafe1UsgModSts "UsageMode Status";
CM_ SG_ 880 AD4DrvrBeltWarnForBkp "AD4 driver belt haptic and pre-tension warning request";
CM_ SG_ 880 CarTiGlb "Presents a tiime value that shall be used by all ECUs to time-stamp diagnsotic trouble codes (DTC) according to the requirements for Global DTC snapshot data.";
CM_ SG_ 880 EngSt1WdStsChks "checksum";
CM_ SG_ 880 EngSt1WdStsCntr "counter";
CM_ SG_ 880 EngSt1WdStsEngSt1WdSts "Signaling the state of the powerpack";
CM_ SG_ 816 ChrgnUReqChks "checksum";
CM_ SG_ 816 ChrgnUReqChrgnUReq "Expected charging voltage";
CM_ SG_ 816 ChrgnUReqCntr "counter";
CM_ SG_ 816 VehBattUSysU "Vehicle System Voltage At 12V side";
CM_ SG_ 816 VehBattUSysUQf "Present vehicle voltage measured by CEM with QF";
CM_ SG_ 881 AD4DrvrBeltWarn "AD4 driver belt haptic and pre-tension warning request";
CM_ SG_ 881 CarModCrashSaved "Boolean which states if Car Mode has been written to memory.";
CM_ SG_ 881 DrvrSeatSnsrSts "Informs if there is a fault on the driver seat sensor is detected through electrical measurements, or plausibility judgement. NotOk means sensor is judged as faulty. Di means that the sensor is not configured.";
CM_ SG_ 881 EngN2 "Engine Speed [rpm]";
CM_ SG_ 881 HvBattPreChrgReq "Hv battery precharge request";
CM_ SG_ 881 IsgSpdActSgn "Actual ISG speed with sign to indicate forward or backward direction";
CM_ SG_ 881 PostImpctBrkgRdy "Information regarding if Post Impact Braking support is available from VDDM.";
CM_ SG_ 881 RlyPwrDistbnCmd1WdPreBattSaveCmd "Prewarning that BttrySaver relay will be shut off. the value changes to 1, 30 sec prior the shut off";
CM_ SG_ 881 SeatOccptAtRowSecDrSide2 "Describes if an occupant is detected in the  seat.";
CM_ SG_ 881 SeatOccptAtRowSecDrSideSnsSts2 "Informs if there is a fault on the driver seat sensor is detected through electrical measurements, or plausibility judgement. NotOk means sensor is judged as faulty. Di means that the sensor is not configured.";
CM_ SG_ 912 DispOfPrpsnMod "Description: Actual powertrain propulsion mode of the hybrid propulsion system. Usage: For hybrid power flow status display in HMI.";
CM_ SG_ 912 DispOfPrpsnModForEv "Actual powertrain propulsion mode of the BEV propulsion system. Usage: For BEV power flow status display in HMI.";
CM_ SG_ 912 DrvrSeatPosPercSeatPosFrntHeiPer "Front Height Position Percentage";
CM_ SG_ 912 DrvrSeatPosPercSeatPosFrntHeiQF "Front Height Position Quality Factor";
CM_ SG_ 912 DrvrSeatPosPercSeatPosHeiPerc "Height Position Percentage";
CM_ SG_ 912 DrvrSeatPosPercSeatPosHeiQF "Height Position Quality Factor";
CM_ SG_ 912 DrvrSeatPosPercSeatPosSldPerc "Length Position Percentage";
CM_ SG_ 912 DrvrSeatPosPercSeatPosSldQF "Length Position Quality Factor";
CM_ SG_ 912 PassAirbLampStsRecPassAirbLampSt "Signals if there is a HW fault, SW fault or signaling fault related to the PAD and PAE indication lamps.";
CM_ SG_ 912 PassAirbLampStsRecPassAirbL_0000 "Ones complement of the data and counter in the signal group.";
CM_ SG_ 912 PassAirbLampStsRecPassAirbL_0001 "Counter that increases for each updated (not necessarily changed) value.";
CM_ SG_ 912 RlyPwrDistbnCmd1WdIgnRlyExtCmd "status of the ignition extended relay";
CM_ SG_ 924 RiFrntTireMsgBattLoSt "battery low status";
CM_ SG_ 924 RiFrntTireMsgFastLoseWarnFlg "fast lost warn flag";
CM_ SG_ 924 RiFrntTireMsgMsgOldFlg "message old flag";
CM_ SG_ 924 RiFrntTireMsgP "tire temperature";
CM_ SG_ 924 RiFrntTireMsgPWarnFlg "pressure warn flag";
CM_ SG_ 924 RiFrntTireMsgSysWarnFlg "system warn flag";
CM_ SG_ 924 RiFrntTireMsgT "tire pressure";
CM_ SG_ 924 RiFrntTireMsgTireFillgAssiPSts "tire fill status";
CM_ SG_ 924 RiFrntTireMsgTWarnFlg "temperature warn flag";
CM_ SG_ 924 RiReTireMsgBattLoSt "battery low status";
CM_ SG_ 924 RiReTireMsgFastLoseWarnFlg "fast lost warn flag";
CM_ SG_ 924 RiReTireMsgMsgOldFlg "message old flag";
CM_ SG_ 924 RiReTireMsgP "tire temperature";
CM_ SG_ 924 RiReTireMsgPWarnFlg "pressure warn flag";
CM_ SG_ 924 RiReTireMsgSysWarnFlg "system warn flag";
CM_ SG_ 924 RiReTireMsgT "tire pressure";
CM_ SG_ 924 RiReTireMsgTireFillgAssiPSts "tire fill status";
CM_ SG_ 924 RiReTireMsgTWarnFlg "temperature warn flag";
CM_ SG_ 904 AsyAutDrvCtrlTyp "Indicates if autonomous driving is ACC/TJA/HWA/TJP or only ACC.";
CM_ SG_ 904 BrkAndAbsWarnIndcnReqAbsWarnIndc "Request for warning indication to driver in case of brake failure (red warning) or ABS failure (yellow warning) ABS warning indication request";
CM_ SG_ 904 BrkAndAbsWarnIndcnReqBrkWarnIndc "Request for warning indication to driver in case of brake failure (red warning) or ABS failure (yellow warning) Brake warning indication request";
CM_ SG_ 904 BrkAndAbsWarnIndcnReqChks "Request for warning indication to driver in case of brake failure (red warning) or ABS failure (yellow warning) Checksum for Brake and ABS warning indication request";
CM_ SG_ 904 BrkAndAbsWarnIndcnReqCntr "Request for warning indication to driver in case of brake failure (red warning) or ABS failure (yellow warning) Counter for Brake and ABS warning indication request";
CM_ SG_ 904 CrsCtrlrActvnOk "The signal informs if Cruise Controller can be activated or not. Primarily used by HMI to know if Cruise Controller activation requests by driver should be ignored or not.";
CM_ SG_ 904 CrsCtrlrStbOk "The signal informs if the Cruise Controller can be set to standby or not.";
CM_ SG_ 904 EscCtrlIndcn "Indicates that an Electronic stability control (ESC) controller is active";
CM_ SG_ 904 SwtLiHzrdWarn "Hazard warning light switch signal.
0-not pressed, 1-pressed";
CM_ SG_ 870 DrvgAstOnSysSts "the last try function status";
CM_ SG_ 870 HvacAirMFlowEstimd "Estimated total mass air flow in front HVAC. ";
CM_ SG_ 870 HvacAirMFlowReEstimd "Estimated total mass air flow in rear HVAC.";
CM_ SG_ 870 ReqForPassAirbIndcnAckd "info about the acknowledgement";
CM_ SG_ 870 RlyPwrDistbnCmd1WdIgnRlyCmd "Ignition relay status";
CM_ SG_ 870 SumActv "VMM force all the ECUs into sleep mode during abandon. SUM must inform VMM if it is still running.";
CM_ SG_ 800 AsyALgtStsAsyALgtSts "The signal indicates the status of the longitudinal control; off, passive, standby, active etc.";
CM_ SG_ 800 AsyALgtStsChks "check sum for E2E
";
CM_ SG_ 800 AsyALgtStsCntr "counter for E2E";
CM_ SG_ 800 DoorDrvrLockSts "DoorDrvrLockSts - Driver Door Lock Status
Lock status
LockStsUkwn - Lock Status Unknown
Unlckd - Unlocked
Lockd - Locked
SafeLockd - Safe Locked (Double Locked)";
CM_ SG_ 800 DoorLeReLockSts "DoorLeReLockSts - Left Rear Door Lock Status
Lock status
LockStsUkwn - Lock Status Unknown
Unlckd - Unlocked
Lockd - Locked
SafeLockd - Safe Locked (Double Locked)";
CM_ SG_ 800 DoorPassLockSts "DoorPassLockSts - Passenger Door Lock Status
Lock status
LockStsUkwn - Lock Status Unknown
Unlckd - Unlocked
Lockd - Locked
SafeLockd - Safe Locked (Double Locked)";
CM_ SG_ 800 DoorRiReLockSts "DoorRiReLockSts - Right Rear Door Lock Status
Lock status
LockStsUkwn - Lock Status Unknown
Unlckd - Unlocked
Lockd - Locked
SafeLockd - Safe Locked (Double Locked)";
CM_ SG_ 385 EmgyAsscTrigSts "Defined the signal as:
0: when the eCall without trigget
1: eCall been automatically trigget by SRS
2: eCall been manually trigget by user via SOS button
3: eCall has fault when SRS trigget crash   ";
CM_ SG_ 900 BrkPedlrRatPerc "Brake pedal Ratio in percentage value";
CM_ SG_ 900 BrkPedlrRatQf "quality factor";
CM_ SG_ 900 BrkTracCtrlActv "Indicates InCtrl if brake traction control (TC) is active on at least one wheel.";
CM_ SG_ 900 CllsnMtgtnFctSts "Shows if the AEB function is on or off. ";
CM_ SG_ 900 CrsCtrlrSts "The signal indicates the status (or state) of the Cruise Controller; Off, Standby, Actv etc.";
CM_ SG_ 900 DrvrCrsCtrlFctSeld "select ACC function or CC function.";
CM_ SG_ 900 EscStChks "Information on activation/ deactivation of Electronic Stability Control (ESC) Checksum for Esc state";
CM_ SG_ 900 EscStCntr "Information on activation/ deactivation of Electronic Stability Control (ESC) Counter for Esc state";
CM_ SG_ 900 EscStEscSt "Information on activation/ deactivation of Electronic Stability Control (ESC) Esc state information for Esc ON, Esc OFF or Esc Sport";
CM_ SG_ 916 LeFrntTireMsgBattLoSt "battery low status";
CM_ SG_ 916 LeFrntTireMsgFastLoseWarnFlg "fast lost warn flag";
CM_ SG_ 916 LeFrntTireMsgMsgOldFlg "message old flag";
CM_ SG_ 916 LeFrntTireMsgP "tire temperature";
CM_ SG_ 916 LeFrntTireMsgPWarnFlg "pressure warn flag";
CM_ SG_ 916 LeFrntTireMsgSysWarnFlg "system warn flag";
CM_ SG_ 916 LeFrntTireMsgT "tire pressure";
CM_ SG_ 916 LeFrntTireMsgTireFillgAssiPSts "tire fill status";
CM_ SG_ 916 LeFrntTireMsgTWarnFlg "temperature warn flag";
CM_ SG_ 916 LeReTireMsgBattLoSt "battery low status";
CM_ SG_ 916 LeReTireMsgFastLoseWarnFlg "fast lost warn flag";
CM_ SG_ 916 LeReTireMsgMsgOldFlg "message old flag";
CM_ SG_ 916 LeReTireMsgP "tire temperature";
CM_ SG_ 916 LeReTireMsgPWarnFlg "pressure warn flag";
CM_ SG_ 916 LeReTireMsgSysWarnFlg "system warn flag";
CM_ SG_ 916 LeReTireMsgT "tire pressure";
CM_ SG_ 916 LeReTireMsgTireFillgAssiPSts "tire fill status";
CM_ SG_ 916 LeReTireMsgTWarnFlg "temperature warn flag";
CM_ SG_ 920 PassSeatPosPercSeatPosFrntHeiPer "Front Height Position Percentage";
CM_ SG_ 920 PassSeatPosPercSeatPosFrntHeiQF "Front Height Position Quality Factor";
CM_ SG_ 920 PassSeatPosPercSeatPosHeiPerc "Height Position Percentage";
CM_ SG_ 920 PassSeatPosPercSeatPosHeiQF "Height Position Quality Factor";
CM_ SG_ 920 PassSeatPosPercSeatPosSldPerc "Length Position Percentage";
CM_ SG_ 920 PassSeatPosPercSeatPosSldQF "Length Position Quality Factor";
CM_ SG_ 920 PinionSteerAgMax1 "PinionSteerAgMax1 contains the current maximal pinion angle. Depends on tire size and vehicle type.";
CM_ SG_ 888 PinionSteerAgGroupChks "Checksum for PinionSteerAgGroup";
CM_ SG_ 888 PinionSteerAgGroupCntr "Counter for PinionSteerAgGroup";
CM_ SG_ 888 PinionSteerAgGroupPinionSteerAg1 "Calculated pinion steer angle at the front steering device";
CM_ SG_ 888 PinionSteerAgGroupPinionSte_0000 "Quality factor for PinionSteerAg1";
CM_ SG_ 888 PinionSteerAgGroupPinionSteerAgS "Calculated pinion steer angle speed at the front steering device ";
CM_ SG_ 888 PinionSteerAgGroupPinionSte_0001 "Quality factor for PinionSteerAgSpd1";
CM_ SG_ 888 PinionSteerAgGroupSteerWhlTq "Torque on steering wheel";
CM_ SG_ 888 PinionSteerAgGroupSteerWhlTqQf "Quality factor for SteerWhlTq";
CM_ SG_ 837 AbsCtrlActvChks "checksum";
CM_ SG_ 837 AbsCtrlActvCntr "counter";
CM_ SG_ 837 AbsCtrlActvCtrlSts1 "Anti Blocking Systems (ABS) control is active (at least one wheel)
0 = No wheel is in Anti Blocking Systems (ABS) control
1 = At least one wheel is in Anti Blocking Systems (ABS) control";
CM_ SG_ 837 AbsSts "Indicates if the ABS function is temporarily or permantly disabled due to a failure.";
CM_ SG_ 518 AccrPedlRatAccrPedlRat "Accelerator Pedal Position with adapted 0 point. Value as percentage of fully pressed pedal";
CM_ SG_ 518 AccrPedlRatChks "Accelerator Pedal Position with adapted 0 point. Value as percentage of fully pressed pedal. Checksum";
CM_ SG_ 518 AccrPedlRatCntr "Accelerator Pedal Position with adapted 0 point. Value as percentage of fully pressed pedal. Counter";
CM_ SG_ 518 AccrPedlRatGrdt "Derivative of accelerator pedal position.";
CM_ SG_ 518 CllsnAidPost "indicate the AEB  brake intervention to the driver.";
CM_ SG_ 518 SldngDoorLeReModSts "Left Rear Sliding Door Electrical or Manual Mode Status";
CM_ SG_ 518 SldngDoorRiReModSts "Right Rear Sliding Door Electrical or Manual Mode Status";
CM_ SG_ 518 ThrPos " ECM  throttle position (AbsThrottlePosition) on CAN";
CM_ SG_ 518 TrlrLampChkAutReq "Distribution of the setting automatic trailer lamp check";
CM_ SG_ 518 TwbrRelsReq "Control towber request";
CM_ SG_ 36 AccrpedlStsChks " It should provide acceleration pedal Status signal ( AccrpedlSts ) to predict whether the accelerator pedal  has fault or not.1-Fault; 0-NoFault";
CM_ SG_ 36 AccrpedlStsCntr " It should provide acceleration pedal Status signal ( AccrpedlSts ) to predict whether the accelerator pedal  has fault or not.1-Fault; 0-NoFault";
CM_ SG_ 36 AccrpedlStsFltSts " It should provide acceleration pedal Status signal ( AccrpedlSts ) to predict whether the accelerator pedal  has fault or not.1-Fault; 0-NoFault";
CM_ SG_ 815 BrkPedlPsdBrkPedlNotPsdSafe "Set to 1 if brake pedal is not pressed, otherwise 0";
CM_ SG_ 815 BrkPedlPsdBrkPedlPsd "Set to 1 if brake pedal is pressed, otherwise 0";
CM_ SG_ 815 BrkPedlPsdChks "Checksum";
CM_ SG_ 815 BrkPedlPsdCntr "Counter";
CM_ SG_ 815 BrkPedlPsdQf "Quality factor";
CM_ SG_ 815 DrvrMonrAlrmReqFromDHU "this singal indicate the level of fatigue alarm.";
CM_ SG_ 815 ThrdRowLeSeatDispMassgFctMassgIn "Massage program Intensity Level";
CM_ SG_ 815 ThrdRowLeSeatDispMassgFctMassgPr "Massage Programs Types";
CM_ SG_ 815 ThrdRowLeSeatDispMassgFctOnOffl2 "Turn on or off seat massage";
CM_ SG_ 815 ThrdRowRiSeatDispMassgFctMassgIn "Massage program Intensity Level";
CM_ SG_ 815 ThrdRowRiSeatDispMassgFctMassgPr "Massage Programs Types";
CM_ SG_ 815 ThrdRowRiSeatDispMassgFctOnOffl2 "Turn on or off seat massage";
CM_ SG_ 84 BrkSysCylPMstAct "Brake system master cylinder pressure information Actual pressure, raw value";
CM_ SG_ 84 BrkSysCylPMstActQf "Brake system master cylinder pressure information Actual pressure quality factor";
CM_ SG_ 84 BrkSysCylPMstChks "Brake system master cylinder pressure information Checksum";
CM_ SG_ 84 BrkSysCylPMstCntr "Brake system master cylinder pressure information Counter";
CM_ SG_ 84 BrkSysCylPMstTar "Brake system master cylinder pressure information Target pressure";
CM_ SG_ 84 BrkSysCylPMstVirt "Brake system master cylinder pressure information Virtual pressure";
CM_ SG_ 84 BrkSysCylPMstVirtQf "Brake system master cylinder pressure information Virtual pressure quality factor";
CM_ SG_ 84 DoorOpenwarnLeIndcn "Indicates if a left door open,warning shall be shown to the driver or not.
If the left door open (FL door open or  RL door open or FL and RL both open), the warning signal will send out.";
CM_ SG_ 84 DoorOpenwarnRiIndcn "Indicates if a right door open, warning shall be shown to the driver or not.
If the right door open( FR door open or  RR door open or FR and RR both open), the warning signal will send out.";
CM_ SG_ 84 LowrTailgOpenHmiReq "Low tailgate open or close request";
CM_ SG_ 131 CllsnFwdWarn "indicate the FCW warning and Latent warning activation.";
CM_ SG_ 131 CllsnThreat "Indicate the danger level for subsystem.";
CM_ SG_ 131 FctaIndcnLe "Indicates if a left FCTA warning shall be shown to the driver or not.";
CM_ SG_ 131 FctaIndcnRi "Indicates if a right FCTA warning shall be shown to the driver or not.";
CM_ SG_ 131 SftyDecelGroupSafeAsySftyDecelRe "target deceleration";
CM_ SG_ 131 SftyDecelGroupSafeAsySftyEnaDece "brake order
";
CM_ SG_ 131 SftyDecelGroupSafeChks "crc";
CM_ SG_ 131 SftyDecelGroupSafeCntr "counter";
CM_ SG_ 305 EpbStsChks "Electrical Park Brake system status information Status for the rear wheel park actuator";
CM_ SG_ 305 EpbStsCntr "Electrical Park Brake system status information Counter for EPB status";
CM_ SG_ 305 EpbStsEpbSts "Electrical Park Brake system status information Status for the rear wheel park actuator";
CM_ SG_ 305 VehSpdIndcdVehSpdIndcd "Vehicle speed";
CM_ SG_ 305 VehSpdIndcdVeSpdIndcdUnit "Unit for vehicle speed";
CM_ SG_ 120 GearLvrIndcn "Gear lever indication (drivetrain position) to the driver. If drivetrain position is not possible to decide signal is set to undefined. Valid for automatic vehicles.
";
CM_ SG_ 120 OccupyMonStsDrvrSts "Driver occupied status by camera monitor";
CM_ SG_ 120 OccupyMonStsPassSts "Passenger occupied status by camera monitor";
CM_ SG_ 120 OccupyMonStsSeccLeSts "Second row left side occupied status by camera monitor";
CM_ SG_ 120 OccupyMonStsSecMidSts "Second row middle side occupied status by camera monitor";
CM_ SG_ 120 OccupyMonStsSecRiSts "Second row right side occupied status by camera monitor";
CM_ SG_ 120 OccupyMonStsThrdLeSts "Third row left side occupied status by camera monitor";
CM_ SG_ 120 OccupyMonStsThrdMidSts "Third row middle side occupied status by camera monitor";
CM_ SG_ 120 OccupyMonStsThrdRiSts "Third row right side occupied status by camera monitor";
CM_ SG_ 120 SeatOccptAtRowSecPasSide2 "Describes if an occupant is detected in the  seat.";
CM_ SG_ 120 SeatOccptAtRowSecPasSideSnsSts2 "Informs if there is a fault on the driver seat sensor is detected through electrical measurements, or plausibility judgement. NotOk means sensor is judged as faulty. Di means that the sensor is not configured.";
CM_ SG_ 120 SwtIndcrIndcrTypExtReq "Signal represent status of the turn stalk swich";
CM_ SG_ 120 SwtIndcrIndcrTypExtReqChks "Checksum";
CM_ SG_ 120 SwtIndcrIndcrTypExtReqCntr "Counter";
CM_ SG_ 120 SwtIndcrIndcrTypExtReqToUpdQf "Qf";
CM_ SG_ 323 PosnBriefPosnLat "Latitude";
CM_ SG_ 323 PosnBriefPosnLgt "Longitude";
CM_ SG_ 832 VehCfgPrmBlkIDBytePosn1 "signal block counter.";
CM_ SG_ 832 VehCfgPrmCCPBytePosn2 " (BlockID-1)*7 + 1. ";
CM_ SG_ 832 VehCfgPrmCCPBytePosn3 " (BlockID-1)*7 + 2. ";
CM_ SG_ 832 VehCfgPrmCCPBytePosn4 " (BlockID-1)*7 + 3. ";
CM_ SG_ 832 VehCfgPrmCCPBytePosn5 " (BlockID-1)*7 + 4. ";
CM_ SG_ 832 VehCfgPrmCCPBytePosn6 " (BlockID-1)*7 + 5. ";
CM_ SG_ 832 VehCfgPrmCCPBytePosn7 " (BlockID-1)*7 + 6. ";
CM_ SG_ 832 VehCfgPrmCCPBytePosn8 " (BlockID-1)*7 + 7. ";
CM_ SG_ 306 VehCfgPrmExtBlkIDBytePosn1 "CarConfigExtended BlockID";
CM_ SG_ 306 VehCfgPrmExtCCPBytePosn2 "CarConfigExtended BytePos2";
CM_ SG_ 306 VehCfgPrmExtCCPBytePosn3 "CarConfigExtended BytePos3";
CM_ SG_ 306 VehCfgPrmExtCCPBytePosn4 "CarConfigExtended BytePos4";
CM_ SG_ 306 VehCfgPrmExtCCPBytePosn5 "CarConfigExtended BytePos5";
CM_ SG_ 306 VehCfgPrmExtCCPBytePosn6 "CarConfigExtended BytePos6";
CM_ SG_ 306 VehCfgPrmExtCCPBytePosn7 "CarConfigExtended BytePos7";
CM_ SG_ 306 VehCfgPrmExtCCPBytePosn8 "CarConfigExtended BytePos8";
CM_ SG_ 128 VinBlockNr "VIN number block counter. ";
CM_ SG_ 128 VinVINSignalPos1 "VIN byte 1. Used for character 1, 8 and 15.";
CM_ SG_ 128 VinVINSignalPos2 "VIN byte 2. Used for character 2, 9 and 16.";
CM_ SG_ 128 VinVINSignalPos3 "VIN byte 3. Used for character 3, 10 and 17.";
CM_ SG_ 128 VinVINSignalPos4 "VIN byte 4. Used for character 4 and 11.";
CM_ SG_ 128 VinVINSignalPos5 "VIN byte 5. Used for character 5 and 12.";
CM_ SG_ 128 VinVINSignalPos6 "VIN byte 6. Used for character 6 and 13.";
CM_ SG_ 128 VinVINSignalPos7 "VIN byte 7. Used for character 7 and 14.";
CM_ SG_ 118 DoorPassRealLockSts "Real lock status from latch feedback on passenger door";
CM_ SG_ 118 DoorPassReRealLockSts "Real lock status from latch feedback on passenger rear door";
CM_ SG_ 118 DoorSldngLeReRelsReq "DoorSldngLeReRelsReq - Left Rear Sliding Door Release Request
Request to release the left rear sliding door.
On - Release request
Off - No release request
Invalid1and2 - No release request";
CM_ SG_ 118 DoorSldngRiReRelsReq "DoorSldngRiReRelsReq - Right Rear Sliding Door Release Request
Request to release the right rear sliding door.
On - Release request
Off - No release request
Invalid1and2 - No release request";
CM_ SG_ 118 PassLockContnSts "Passenger door lock interface connection status";
CM_ SG_ 118 VehSpdLgtA "Vehicle speed longitudinal based on wheel speed sensors and longitudinal acceleration.";
CM_ SG_ 118 VehSpdLgtChks "Checksum";
CM_ SG_ 118 VehSpdLgtCntr "Counter";
CM_ SG_ 118 VehSpdLgtQf "Quality factor for vehicle speed as measured by wheel speed sensors and longitudinal acceleration.";
CM_ SG_ 280 DoorDrvrRealLockSts "Real lock status from latch feedback on driver door";
CM_ SG_ 280 DoorDrvrReRealLockSts "Real lock status from latch feedback on driver rear door";
CM_ SG_ 280 DrvrLockContnSts "Driver door lock interface connection status";
CM_ SG_ 280 TopPercTrFromHmi "This signal is used to set top percent of tailgate";
CM_ SG_ 280 TrOpenPosnReqFromHmi "Request open position from HMI";
CM_ SG_ 280 TrRelsReq "TrRelsReq - Tailgate or Bootlid Release Request

Request to release the tailgate or bootlid.

On  Release request
Off  No release request
Invalid1and2  No release request";
CM_ SG_ 921 TrsmActrPosnSafeTrsmActrPosn "Describes the transmission position (P, R, N, D). Can also take intermediate positions (PR, RN, ND). If error are detected on position sensors undefined is set. Transmission measured gear lever position";
CM_ SG_ 921 TrsmActrPosnSafeTrsmActrPosnChks "Describes the transmission position (P, R, N, D). Can also take intermediate positions (PR, RN, ND). If error are detected on position sensors undefined is set. Transmission measured gear lever position";
CM_ SG_ 921 TrsmActrPosnSafeTrsmActrPosnCntr "Describes the transmission position (P, R, N, D). Can also take intermediate positions (PR, RN, ND). If error are detected on position sensors undefined is set. Transmission measured gear lever position";
CM_ SG_ 921 VehTiAndDataDataValid "Vehicle time (Hr, Min and Sec) and date (Year, Months and days) data for indication. See requirement for more information about the signals. Signal qualifier, No means values should be ignored.";
CM_ SG_ 921 VehTiAndDataDay "Vehicle time (Hr, Min and Sec) and date (Year, Months and days) data for indication. See requirement for more information about the signals. Day";
CM_ SG_ 921 VehTiAndDataHr1 "Vehicle time (Hr, Min and Sec) and date (Year, Months and days) data for indication. See requirement for more information about the signals. Hour";
CM_ SG_ 921 VehTiAndDataMins1 "Vehicle time (Hr, Min and Sec) and date (Year, Months and days) data for indication. See requirement for more information about the signals. Minutes";
CM_ SG_ 921 VehTiAndDataMth1 "Vehicle time (Hr, Min and Sec) and date (Year, Months and days) data for indication. See requirement for more information about the signals. Month, 1-12";
CM_ SG_ 921 VehTiAndDataSec1 "Vehicle time (Hr, Min and Sec) and date (Year, Months and days) data for indication. See requirement for more information about the signals. Seconds";
CM_ SG_ 921 VehTiAndDataYr1 "Vehicle time (Hr, Min and Sec) and date (Year, Months and days) data for indication. See requirement for more information about the signals. Year, 0-99";
CM_ SG_ 552 DrvrSeatAdpvLumSetg "driver seat adaptive lumbar support setting";
CM_ SG_ 552 HmiSeatHeatgForRowSecLe "HMI/user Request of Seat Heat Row 2 Left Level ";
CM_ SG_ 552 HmiSeatHeatgForRowSecRi "HMI/user Request of Seat Heat Row 2 Right Level ";
CM_ SG_ 552 HmiSeatHeatgForRowThrdLe "HMI/user Request of Seat Heat Row 3 Left Level ";
CM_ SG_ 552 HmiSeatHeatgForRowThrdRi "HMI/user Request of Seat Heat Row 3 Right Level ";
CM_ SG_ 552 HmiSeatVentnForRowSecLe "HMI/user Request of Seat Vent Row 2 Left Level ";
CM_ SG_ 552 HmiSeatVentnForRowSecRi "HMI/user Request of Seat Vent Row 2 Right Level ";
CM_ SG_ 552 HmiSeatVentnForRowThrdLe "HMI/user Request of Seat Vent Row 3 Left Level ";
CM_ SG_ 552 HmiSeatVentnForRowThrdRi "HMI/user Request of Seat Vent Row 3 Rignt Level ";
CM_ SG_ 552 KeyScanActv "Signal to inform about if a key search is in progress.
TRUE - Key search ongoing
FALSE - No key search";
CM_ SG_ 552 PrkgStsToEDRAPATo "APATo";
CM_ SG_ 552 PrkgStsToEDRHPATo "HPATo";
CM_ SG_ 552 PrkgStsToEDRLSDAandTBATo "LSDA&&TBATo";
CM_ SG_ 552 PrkgStsToEDRreserved1 "reserved1";
CM_ SG_ 552 PrkgStsToEDRreserved2 "reserved2";
CM_ SG_ 552 PrkgStsToEDRreserved3 "reserved3";
CM_ SG_ 552 PrkgStsToEDRRPATo "RPATo";
BA_DEF_ BO_  "NmAsrMessage" ENUM  "No","Yes";
BA_DEF_ BO_  "GenMsgStartDelayTime" INT 0 65536;
BA_DEF_ BO_  "GenMsgSendType" ENUM  "cyclic","spontaneous","not-used","not-used","not-used","cyclicAndSpontaneous","not-used","cyclicIfActive","NoMsgSendType";
BA_DEF_ BO_  "GenMsgILSupport" ENUM  "No","Yes";
BA_DEF_ BO_  "GenMsgDelayTime" INT 0 65536;
BA_DEF_ BO_  "GenMsgCycleTime" INT 0 65536;
BA_DEF_ BO_  "CANFD_BRS" ENUM  "0","1";
BA_DEF_ BO_  "VFrameFormat" ENUM  "StandardCAN","ExtendedCAN","reserved","J1939PG","reserved","reserved","reserved","reserved","reserved","reserved","reserved","reserved","reserved","reserved","StandardCAN_FD","ExtendedCAN_FD";
BA_DEF_ SG_  "GenSigStartValue" HEX 0 80000000;
BA_DEF_ SG_  "GenSigSendType" ENUM  "Cyclic","OnWrite","OnWriteWithRepetition","OnChange","OnChangeWithRepetition","IfActive","IfActiveWithRepetition","NoSigSendType";
BA_DEF_ SG_  "GenSigFuncType" ENUM  "NoFunction","n/a","n/a","n/a","n/a","n/a","n/a","n/a","n/a","n/a","n/a","n/a","n/a","n/a","n/a","CHK","CNTR","n/a","n/a","n/a","CNTR_AR_01","CRC_AR_01_BOTH","CRC_AR_01_ALT","CRC_AR_01_LOW","CRC_AR_01_NIBBLE","CNTR_AR_04","CRC_AR_04A","CNTR_AR_05","CRC_AR_05";
BA_DEF_ SG_  "GenSigDataID" STRING ;
BA_DEF_ SG_  "SystemSignalLongSymbol" STRING ;
BA_DEF_ BO_  "SystemMessageLongSymbol" STRING ;
BA_DEF_DEF_  "NmAsrMessage" "No";
BA_DEF_DEF_  "GenMsgStartDelayTime" 0;
BA_DEF_DEF_  "GenMsgSendType" "NoMsgSendType";
BA_DEF_DEF_  "GenMsgILSupport" "Yes";
BA_DEF_DEF_  "GenMsgDelayTime" 0;
BA_DEF_DEF_  "GenMsgCycleTime" 0;
BA_DEF_DEF_  "CANFD_BRS" "1";
BA_DEF_DEF_  "VFrameFormat" "J1939PG";
BA_DEF_DEF_  "GenSigStartValue" 0;
BA_DEF_DEF_  "GenSigSendType" "NoSigSendType";
BA_DEF_DEF_  "GenSigFuncType" "NoFunction";
BA_DEF_DEF_  "GenSigDataID" "";
BA_DEF_DEF_  "SystemSignalLongSymbol" "";
BA_DEF_DEF_  "SystemMessageLongSymbol" "";
BA_ "VFrameFormat" BO_ 1290 0;
BA_ "GenMsgSendType" BO_ 1290 1;
BA_ "GenMsgILSupport" BO_ 1290 0;
BA_ "NmAsrMessage" BO_ 1290 1;
BA_ "GenMsgDelayTime" BO_ 1290 20;
BA_ "VFrameFormat" BO_ 1354 0;
BA_ "GenMsgSendType" BO_ 1354 0;
BA_ "GenMsgCycleTime" BO_ 1354 1000;
BA_ "VFrameFormat" BO_ 2047 0;
BA_ "GenMsgSendType" BO_ 2047 1;
BA_ "VFrameFormat" BO_ 1820 0;
BA_ "GenMsgSendType" BO_ 1820 1;
BA_ "VFrameFormat" BO_ 1830 0;
BA_ "GenMsgSendType" BO_ 1830 1;
BA_ "VFrameFormat" BO_ 1840 0;
BA_ "GenMsgSendType" BO_ 1840 1;
BA_ "VFrameFormat" BO_ 1852 0;
BA_ "GenMsgSendType" BO_ 1852 1;
BA_ "VFrameFormat" BO_ 1813 0;
BA_ "GenMsgSendType" BO_ 1813 1;
BA_ "VFrameFormat" BO_ 1808 0;
BA_ "GenMsgSendType" BO_ 1808 1;
BA_ "VFrameFormat" BO_ 1809 0;
BA_ "GenMsgSendType" BO_ 1809 1;
BA_ "VFrameFormat" BO_ 1827 0;
BA_ "GenMsgSendType" BO_ 1827 1;
BA_ "VFrameFormat" BO_ 1828 0;
BA_ "GenMsgSendType" BO_ 1828 1;
BA_ "VFrameFormat" BO_ 1841 0;
BA_ "GenMsgSendType" BO_ 1841 1;
BA_ "VFrameFormat" BO_ 1842 0;
BA_ "GenMsgSendType" BO_ 1842 1;
BA_ "VFrameFormat" BO_ 1833 0;
BA_ "GenMsgSendType" BO_ 1833 1;
BA_ "VFrameFormat" BO_ 2033 0;
BA_ "GenMsgSendType" BO_ 2033 1;
BA_ "GenMsgDelayTime" BO_ 2033 5;
BA_ "SystemMessageLongSymbol" BO_ 2033 "ZcudToSrsISO26021ZCUDCAN1DiagResFrame11";
BA_ "VFrameFormat" BO_ 1849 0;
BA_ "GenMsgSendType" BO_ 1849 1;
BA_ "VFrameFormat" BO_ 1834 0;
BA_ "GenMsgSendType" BO_ 1834 1;
BA_ "VFrameFormat" BO_ 1815 0;
BA_ "GenMsgSendType" BO_ 1815 1;
BA_ "VFrameFormat" BO_ 1835 0;
BA_ "GenMsgSendType" BO_ 1835 1;
BA_ "VFrameFormat" BO_ 1846 0;
BA_ "GenMsgSendType" BO_ 1846 1;
BA_ "VFrameFormat" BO_ 1847 0;
BA_ "GenMsgSendType" BO_ 1847 1;
BA_ "VFrameFormat" BO_ 1345 0;
BA_ "GenMsgSendType" BO_ 1345 0;
BA_ "GenMsgCycleTime" BO_ 1345 1000;
BA_ "VFrameFormat" BO_ 64 0;
BA_ "GenMsgSendType" BO_ 64 0;
BA_ "GenMsgCycleTime" BO_ 64 15;
BA_ "VFrameFormat" BO_ 1164 0;
BA_ "GenMsgSendType" BO_ 1164 0;
BA_ "GenMsgCycleTime" BO_ 1164 1000;
BA_ "VFrameFormat" BO_ 224 0;
BA_ "GenMsgSendType" BO_ 224 0;
BA_ "GenMsgCycleTime" BO_ 224 40;
BA_ "VFrameFormat" BO_ 240 0;
BA_ "GenMsgSendType" BO_ 240 0;
BA_ "GenMsgCycleTime" BO_ 240 30;
BA_ "VFrameFormat" BO_ 880 0;
BA_ "GenMsgSendType" BO_ 880 0;
BA_ "GenMsgCycleTime" BO_ 880 620;
BA_ "VFrameFormat" BO_ 816 0;
BA_ "GenMsgSendType" BO_ 816 0;
BA_ "GenMsgCycleTime" BO_ 816 215;
BA_ "VFrameFormat" BO_ 881 0;
BA_ "GenMsgSendType" BO_ 881 0;
BA_ "GenMsgCycleTime" BO_ 881 150;
BA_ "VFrameFormat" BO_ 912 0;
BA_ "GenMsgSendType" BO_ 912 0;
BA_ "GenMsgCycleTime" BO_ 912 800;
BA_ "VFrameFormat" BO_ 924 0;
BA_ "GenMsgSendType" BO_ 924 0;
BA_ "GenMsgCycleTime" BO_ 924 800;
BA_ "VFrameFormat" BO_ 904 0;
BA_ "GenMsgSendType" BO_ 904 0;
BA_ "GenMsgCycleTime" BO_ 904 350;
BA_ "VFrameFormat" BO_ 870 0;
BA_ "GenMsgSendType" BO_ 870 0;
BA_ "GenMsgCycleTime" BO_ 870 40;
BA_ "VFrameFormat" BO_ 800 0;
BA_ "GenMsgSendType" BO_ 800 0;
BA_ "GenMsgCycleTime" BO_ 800 180;
BA_ "VFrameFormat" BO_ 385 0;
BA_ "GenMsgSendType" BO_ 385 1;
BA_ "GenMsgDelayTime" BO_ 385 10;
BA_ "VFrameFormat" BO_ 900 0;
BA_ "GenMsgSendType" BO_ 900 0;
BA_ "GenMsgCycleTime" BO_ 900 350;
BA_ "VFrameFormat" BO_ 916 0;
BA_ "GenMsgSendType" BO_ 916 0;
BA_ "GenMsgCycleTime" BO_ 916 800;
BA_ "VFrameFormat" BO_ 920 0;
BA_ "GenMsgSendType" BO_ 920 0;
BA_ "GenMsgCycleTime" BO_ 920 800;
BA_ "VFrameFormat" BO_ 888 0;
BA_ "GenMsgSendType" BO_ 888 0;
BA_ "GenMsgCycleTime" BO_ 888 150;
BA_ "VFrameFormat" BO_ 837 0;
BA_ "GenMsgSendType" BO_ 837 0;
BA_ "GenMsgCycleTime" BO_ 837 420;
BA_ "VFrameFormat" BO_ 518 0;
BA_ "GenMsgSendType" BO_ 518 0;
BA_ "GenMsgCycleTime" BO_ 518 100;
BA_ "VFrameFormat" BO_ 36 0;
BA_ "GenMsgSendType" BO_ 36 0;
BA_ "GenMsgCycleTime" BO_ 36 15;
BA_ "VFrameFormat" BO_ 815 0;
BA_ "GenMsgSendType" BO_ 815 0;
BA_ "GenMsgCycleTime" BO_ 815 85;
BA_ "VFrameFormat" BO_ 84 0;
BA_ "GenMsgSendType" BO_ 84 0;
BA_ "GenMsgCycleTime" BO_ 84 10;
BA_ "VFrameFormat" BO_ 131 0;
BA_ "GenMsgSendType" BO_ 131 0;
BA_ "GenMsgCycleTime" BO_ 131 40;
BA_ "VFrameFormat" BO_ 305 0;
BA_ "GenMsgSendType" BO_ 305 0;
BA_ "GenMsgCycleTime" BO_ 305 15;
BA_ "VFrameFormat" BO_ 120 0;
BA_ "GenMsgSendType" BO_ 120 0;
BA_ "GenMsgCycleTime" BO_ 120 40;
BA_ "VFrameFormat" BO_ 323 0;
BA_ "GenMsgSendType" BO_ 323 0;
BA_ "GenMsgCycleTime" BO_ 323 25;
BA_ "VFrameFormat" BO_ 832 0;
BA_ "GenMsgSendType" BO_ 832 1;
BA_ "GenMsgDelayTime" BO_ 832 100;
BA_ "VFrameFormat" BO_ 306 0;
BA_ "GenMsgSendType" BO_ 306 1;
BA_ "GenMsgDelayTime" BO_ 306 90;
BA_ "VFrameFormat" BO_ 128 0;
BA_ "GenMsgSendType" BO_ 128 0;
BA_ "GenMsgCycleTime" BO_ 128 90;
BA_ "VFrameFormat" BO_ 118 0;
BA_ "GenMsgSendType" BO_ 118 0;
BA_ "GenMsgCycleTime" BO_ 118 20;
BA_ "VFrameFormat" BO_ 280 0;
BA_ "GenMsgSendType" BO_ 280 0;
BA_ "GenMsgCycleTime" BO_ 280 30;
BA_ "VFrameFormat" BO_ 921 0;
BA_ "GenMsgSendType" BO_ 921 0;
BA_ "GenMsgCycleTime" BO_ 921 1000;
BA_ "VFrameFormat" BO_ 552 0;
BA_ "GenMsgSendType" BO_ 552 0;
BA_ "GenMsgCycleTime" BO_ 552 100;
BA_ "GenSigSendType" SG_ 1290 WakeUpReasonsforTRM 0;
BA_ "GenSigSendType" SG_ 1354 VFCVectorTRMBlockID 0;
BA_ "GenSigSendType" SG_ 1354 VFCVectorTRMVFCid0 0;
BA_ "GenSigSendType" SG_ 1354 VFCVectorTRMVFCid1 0;
BA_ "GenSigSendType" SG_ 1354 VFCVectorTRMVFCid10 0;
BA_ "GenSigSendType" SG_ 1354 VFCVectorTRMVFCid11 0;
BA_ "GenSigSendType" SG_ 1354 VFCVectorTRMVFCid12 0;
BA_ "GenSigSendType" SG_ 1354 VFCVectorTRMVFCid13 0;
BA_ "GenSigSendType" SG_ 1354 VFCVectorTRMVFCid14 0;
BA_ "GenSigSendType" SG_ 1354 VFCVectorTRMVFCid15 0;
BA_ "GenSigSendType" SG_ 1354 VFCVectorTRMVFCid16 0;
BA_ "GenSigSendType" SG_ 1354 VFCVectorTRMVFCid17 0;
BA_ "GenSigSendType" SG_ 1354 VFCVectorTRMVFCid18 0;
BA_ "GenSigSendType" SG_ 1354 VFCVectorTRMVFCid19 0;
BA_ "GenSigSendType" SG_ 1354 VFCVectorTRMVFCid2 0;
BA_ "GenSigSendType" SG_ 1354 VFCVectorTRMVFCid20 0;
BA_ "GenSigSendType" SG_ 1354 VFCVectorTRMVFCid21 0;
BA_ "GenSigSendType" SG_ 1354 VFCVectorTRMVFCid22 0;
BA_ "GenSigSendType" SG_ 1354 VFCVectorTRMVFCid23 0;
BA_ "GenSigSendType" SG_ 1354 VFCVectorTRMVFCid24 0;
BA_ "GenSigSendType" SG_ 1354 VFCVectorTRMVFCid25 0;
BA_ "GenSigSendType" SG_ 1354 VFCVectorTRMVFCid26 0;
BA_ "GenSigSendType" SG_ 1354 VFCVectorTRMVFCid27 0;
BA_ "GenSigSendType" SG_ 1354 VFCVectorTRMVFCid28 0;
BA_ "GenSigSendType" SG_ 1354 VFCVectorTRMVFCid29 0;
BA_ "GenSigSendType" SG_ 1354 VFCVectorTRMVFCid3 0;
BA_ "GenSigSendType" SG_ 1354 VFCVectorTRMVFCid30 0;
BA_ "GenSigSendType" SG_ 1354 VFCVectorTRMVFCid31 0;
BA_ "GenSigSendType" SG_ 1354 VFCVectorTRMVFCid32 0;
BA_ "GenSigSendType" SG_ 1354 VFCVectorTRMVFCid33 0;
BA_ "GenSigSendType" SG_ 1354 VFCVectorTRMVFCid34 0;
BA_ "GenSigSendType" SG_ 1354 VFCVectorTRMVFCid35 0;
BA_ "GenSigSendType" SG_ 1354 VFCVectorTRMVFCid36 0;
BA_ "GenSigSendType" SG_ 1354 VFCVectorTRMVFCid37 0;
BA_ "GenSigSendType" SG_ 1354 VFCVectorTRMVFCid38 0;
BA_ "GenSigSendType" SG_ 1354 VFCVectorTRMVFCid39 0;
BA_ "GenSigSendType" SG_ 1354 VFCVectorTRMVFCid4 0;
BA_ "GenSigSendType" SG_ 1354 VFCVectorTRMVFCid40 0;
BA_ "GenSigSendType" SG_ 1354 VFCVectorTRMVFCid41 0;
BA_ "GenSigSendType" SG_ 1354 VFCVectorTRMVFCid42 0;
BA_ "GenSigSendType" SG_ 1354 VFCVectorTRMVFCid43 0;
BA_ "GenSigSendType" SG_ 1354 VFCVectorTRMVFCid44 0;
BA_ "GenSigSendType" SG_ 1354 VFCVectorTRMVFCid45 0;
BA_ "GenSigSendType" SG_ 1354 VFCVectorTRMVFCid46 0;
BA_ "GenSigSendType" SG_ 1354 VFCVectorTRMVFCid47 0;
BA_ "GenSigSendType" SG_ 1354 VFCVectorTRMVFCid48 0;
BA_ "GenSigSendType" SG_ 1354 VFCVectorTRMVFCid49 0;
BA_ "GenSigSendType" SG_ 1354 VFCVectorTRMVFCid5 0;
BA_ "GenSigSendType" SG_ 1354 VFCVectorTRMVFCid50 0;
BA_ "GenSigSendType" SG_ 1354 VFCVectorTRMVFCid51 0;
BA_ "GenSigSendType" SG_ 1354 VFCVectorTRMVFCid52 0;
BA_ "GenSigSendType" SG_ 1354 VFCVectorTRMVFCid53 0;
BA_ "GenSigSendType" SG_ 1354 VFCVectorTRMVFCid54 0;
BA_ "GenSigSendType" SG_ 1354 VFCVectorTRMVFCid55 0;
BA_ "GenSigSendType" SG_ 1354 VFCVectorTRMVFCid56 0;
BA_ "GenSigSendType" SG_ 1354 VFCVectorTRMVFCid57 0;
BA_ "GenSigSendType" SG_ 1354 VFCVectorTRMVFCid58 0;
BA_ "GenSigSendType" SG_ 1354 VFCVectorTRMVFCid59 0;
BA_ "GenSigSendType" SG_ 1354 VFCVectorTRMVFCid6 0;
BA_ "GenSigSendType" SG_ 1354 VFCVectorTRMVFCid60 0;
BA_ "GenSigSendType" SG_ 1354 VFCVectorTRMVFCid61 0;
BA_ "GenSigSendType" SG_ 1354 VFCVectorTRMVFCid7 0;
BA_ "GenSigSendType" SG_ 1354 VFCVectorTRMVFCid8 0;
BA_ "GenSigSendType" SG_ 1354 VFCVectorTRMVFCid9 0;
BA_ "SystemSignalLongSymbol" SG_ 2033 ZcudToSrsISO26021ZCUDCan1ReqNpdu "ZcudToSrsISO26021ZCUDCan1ReqNpdu11";
BA_ "GenSigSendType" SG_ 1345 VFCVectorZCUDMBlockID 0;
BA_ "GenSigSendType" SG_ 1345 VFCVectorZCUDMVFCid0 0;
BA_ "GenSigSendType" SG_ 1345 VFCVectorZCUDMVFCid1 0;
BA_ "GenSigSendType" SG_ 1345 VFCVectorZCUDMVFCid10 0;
BA_ "GenSigSendType" SG_ 1345 VFCVectorZCUDMVFCid11 0;
BA_ "GenSigSendType" SG_ 1345 VFCVectorZCUDMVFCid12 0;
BA_ "GenSigSendType" SG_ 1345 VFCVectorZCUDMVFCid13 0;
BA_ "GenSigSendType" SG_ 1345 VFCVectorZCUDMVFCid14 0;
BA_ "GenSigSendType" SG_ 1345 VFCVectorZCUDMVFCid15 0;
BA_ "GenSigSendType" SG_ 1345 VFCVectorZCUDMVFCid16 0;
BA_ "GenSigSendType" SG_ 1345 VFCVectorZCUDMVFCid17 0;
BA_ "GenSigSendType" SG_ 1345 VFCVectorZCUDMVFCid18 0;
BA_ "GenSigSendType" SG_ 1345 VFCVectorZCUDMVFCid19 0;
BA_ "GenSigSendType" SG_ 1345 VFCVectorZCUDMVFCid2 0;
BA_ "GenSigSendType" SG_ 1345 VFCVectorZCUDMVFCid20 0;
BA_ "GenSigSendType" SG_ 1345 VFCVectorZCUDMVFCid21 0;
BA_ "GenSigSendType" SG_ 1345 VFCVectorZCUDMVFCid22 0;
BA_ "GenSigSendType" SG_ 1345 VFCVectorZCUDMVFCid23 0;
BA_ "GenSigSendType" SG_ 1345 VFCVectorZCUDMVFCid24 0;
BA_ "GenSigSendType" SG_ 1345 VFCVectorZCUDMVFCid25 0;
BA_ "GenSigSendType" SG_ 1345 VFCVectorZCUDMVFCid26 0;
BA_ "GenSigSendType" SG_ 1345 VFCVectorZCUDMVFCid27 0;
BA_ "GenSigSendType" SG_ 1345 VFCVectorZCUDMVFCid28 0;
BA_ "GenSigSendType" SG_ 1345 VFCVectorZCUDMVFCid29 0;
BA_ "GenSigSendType" SG_ 1345 VFCVectorZCUDMVFCid3 0;
BA_ "GenSigSendType" SG_ 1345 VFCVectorZCUDMVFCid30 0;
BA_ "GenSigSendType" SG_ 1345 VFCVectorZCUDMVFCid31 0;
BA_ "GenSigSendType" SG_ 1345 VFCVectorZCUDMVFCid32 0;
BA_ "GenSigSendType" SG_ 1345 VFCVectorZCUDMVFCid33 0;
BA_ "GenSigSendType" SG_ 1345 VFCVectorZCUDMVFCid34 0;
BA_ "GenSigSendType" SG_ 1345 VFCVectorZCUDMVFCid35 0;
BA_ "GenSigSendType" SG_ 1345 VFCVectorZCUDMVFCid36 0;
BA_ "GenSigSendType" SG_ 1345 VFCVectorZCUDMVFCid37 0;
BA_ "GenSigSendType" SG_ 1345 VFCVectorZCUDMVFCid38 0;
BA_ "GenSigSendType" SG_ 1345 VFCVectorZCUDMVFCid39 0;
BA_ "GenSigSendType" SG_ 1345 VFCVectorZCUDMVFCid4 0;
BA_ "GenSigSendType" SG_ 1345 VFCVectorZCUDMVFCid40 0;
BA_ "GenSigSendType" SG_ 1345 VFCVectorZCUDMVFCid41 0;
BA_ "GenSigSendType" SG_ 1345 VFCVectorZCUDMVFCid42 0;
BA_ "GenSigSendType" SG_ 1345 VFCVectorZCUDMVFCid43 0;
BA_ "GenSigSendType" SG_ 1345 VFCVectorZCUDMVFCid44 0;
BA_ "GenSigSendType" SG_ 1345 VFCVectorZCUDMVFCid45 0;
BA_ "GenSigSendType" SG_ 1345 VFCVectorZCUDMVFCid46 0;
BA_ "GenSigSendType" SG_ 1345 VFCVectorZCUDMVFCid47 0;
BA_ "GenSigSendType" SG_ 1345 VFCVectorZCUDMVFCid48 0;
BA_ "GenSigSendType" SG_ 1345 VFCVectorZCUDMVFCid49 0;
BA_ "GenSigSendType" SG_ 1345 VFCVectorZCUDMVFCid5 0;
BA_ "GenSigSendType" SG_ 1345 VFCVectorZCUDMVFCid50 0;
BA_ "GenSigSendType" SG_ 1345 VFCVectorZCUDMVFCid51 0;
BA_ "GenSigSendType" SG_ 1345 VFCVectorZCUDMVFCid52 0;
BA_ "GenSigSendType" SG_ 1345 VFCVectorZCUDMVFCid53 0;
BA_ "GenSigSendType" SG_ 1345 VFCVectorZCUDMVFCid54 0;
BA_ "GenSigSendType" SG_ 1345 VFCVectorZCUDMVFCid55 0;
BA_ "GenSigSendType" SG_ 1345 VFCVectorZCUDMVFCid56 0;
BA_ "GenSigSendType" SG_ 1345 VFCVectorZCUDMVFCid57 0;
BA_ "GenSigSendType" SG_ 1345 VFCVectorZCUDMVFCid58 0;
BA_ "GenSigSendType" SG_ 1345 VFCVectorZCUDMVFCid59 0;
BA_ "GenSigSendType" SG_ 1345 VFCVectorZCUDMVFCid6 0;
BA_ "GenSigSendType" SG_ 1345 VFCVectorZCUDMVFCid60 0;
BA_ "GenSigSendType" SG_ 1345 VFCVectorZCUDMVFCid61 0;
BA_ "GenSigSendType" SG_ 1345 VFCVectorZCUDMVFCid7 0;
BA_ "GenSigSendType" SG_ 1345 VFCVectorZCUDMVFCid8 0;
BA_ "GenSigSendType" SG_ 1345 VFCVectorZCUDMVFCid9 0;
BA_ "GenSigSendType" SG_ 64 DoorDrvrSts 0;
BA_ "GenSigSendType" SG_ 64 DoorLeReSts 0;
BA_ "GenSigSendType" SG_ 64 TrNoKeyPrsntAcoustReq 0;
BA_ "GenSigSendType" SG_ 64 TrOpenerReqTrigSrc 0;
BA_ "GenSigSendType" SG_ 64 TrOpenerReqTrOpenerReq 0;
BA_ "GenSigSendType" SG_ 64 TwliBriSts 0;
BA_ "GenSigStartValue" SG_ 64 VehMtnSt_UB 1;
BA_ "GenSigSendType" SG_ 64 VehMtnStChks 0;
BA_ "GenSigFuncType" SG_ 64 VehMtnStChks 15;
BA_ "GenSigDataID" SG_ 64 VehMtnStChks "0x36";
BA_ "GenSigSendType" SG_ 64 VehMtnStCntr 0;
BA_ "GenSigFuncType" SG_ 64 VehMtnStCntr 16;
BA_ "GenSigSendType" SG_ 64 VehMtnStVehMtnSt 0;
BA_ "GenSigSendType" SG_ 1164 ListOfNodToSMx 0;
BA_ "GenSigSendType" SG_ 1164 TiAndDateIndcnDataValid 0;
BA_ "GenSigSendType" SG_ 1164 TiAndDateIndcnDay 0;
BA_ "GenSigStartValue" SG_ 1164 TiAndDateIndcnDay 1;
BA_ "GenSigSendType" SG_ 1164 TiAndDateIndcnHr1 0;
BA_ "GenSigSendType" SG_ 1164 TiAndDateIndcnMins1 0;
BA_ "GenSigSendType" SG_ 1164 TiAndDateIndcnMth1 0;
BA_ "GenSigStartValue" SG_ 1164 TiAndDateIndcnMth1 1;
BA_ "GenSigSendType" SG_ 1164 TiAndDateIndcnSec1 0;
BA_ "GenSigSendType" SG_ 1164 TiAndDateIndcnYr1 0;
BA_ "GenSigSendType" SG_ 224 DoorPassSts 0;
BA_ "GenSigSendType" SG_ 224 DoorRiReSts 0;
BA_ "GenSigSendType" SG_ 224 IntrBriSts 0;
BA_ "GenSigSendType" SG_ 224 TopPosTrFromHmi 1;
BA_ "GenSigSendType" SG_ 224 TrlrLampChkReqFromHmi 0;
BA_ "GenSigSendType" SG_ 224 TrlrLiFogActvt 0;
BA_ "GenSigSendType" SG_ 224 TrPosnUpprProgmReq 0;
BA_ "GenSigSendType" SG_ 224 TrSts 0;
BA_ "GenSigSendType" SG_ 240 TrlrLiPosnActvt 0;
BA_ "GenSigStartValue" SG_ 240 TrlrLiPosnActvt 1;
BA_ "GenSigStartValue" SG_ 240 VehModMngtGlbSafe1_UB 1;
BA_ "GenSigSendType" SG_ 240 VehModMngtGlbSafe1CarModSts1 0;
BA_ "GenSigSendType" SG_ 240 VehModMngtGlbSafe1CarModSubtypWd 0;
BA_ "SystemSignalLongSymbol" SG_ 240 VehModMngtGlbSafe1CarModSubtypWd "VehModMngtGlbSafe1CarModSubtypWdCarModSubtyp";
BA_ "GenSigSendType" SG_ 240 VehModMngtGlbSafe1Chks 0;
BA_ "GenSigFuncType" SG_ 240 VehModMngtGlbSafe1Chks 15;
BA_ "GenSigDataID" SG_ 240 VehModMngtGlbSafe1Chks "0x74";
BA_ "GenSigSendType" SG_ 240 VehModMngtGlbSafe1Cntr 0;
BA_ "GenSigFuncType" SG_ 240 VehModMngtGlbSafe1Cntr 16;
BA_ "GenSigSendType" SG_ 240 VehModMngtGlbSafe1EgyLvlElecMai 0;
BA_ "GenSigSendType" SG_ 240 VehModMngtGlbSafe1EgyLvlElecSubt 0;
BA_ "SystemSignalLongSymbol" SG_ 240 VehModMngtGlbSafe1EgyLvlElecSubt "VehModMngtGlbSafe1EgyLvlElecSubtyp";
BA_ "GenSigSendType" SG_ 240 VehModMngtGlbSafe1FltEgyCnsWdSts 0;
BA_ "GenSigSendType" SG_ 240 VehModMngtGlbSafe1PwrLvlElecMai 0;
BA_ "GenSigSendType" SG_ 240 VehModMngtGlbSafe1PwrLvlElecSubt 0;
BA_ "SystemSignalLongSymbol" SG_ 240 VehModMngtGlbSafe1PwrLvlElecSubt "VehModMngtGlbSafe1PwrLvlElecSubtyp";
BA_ "GenSigSendType" SG_ 240 VehModMngtGlbSafe1UsgModSts 0;
BA_ "GenSigStartValue" SG_ 240 VehModMngtGlbSafe1UsgModSts 1;
BA_ "GenSigSendType" SG_ 880 AD4DrvrBeltWarnForBkp 0;
BA_ "GenSigSendType" SG_ 880 CarTiGlb 0;
BA_ "GenSigSendType" SG_ 880 EngSt1WdStsChks 0;
BA_ "GenSigFuncType" SG_ 880 EngSt1WdStsChks 15;
BA_ "GenSigDataID" SG_ 880 EngSt1WdStsChks "0x89";
BA_ "GenSigSendType" SG_ 880 EngSt1WdStsCntr 0;
BA_ "GenSigFuncType" SG_ 880 EngSt1WdStsCntr 16;
BA_ "GenSigSendType" SG_ 880 EngSt1WdStsEngSt1WdSts 0;
BA_ "GenSigSendType" SG_ 816 ChrgnUReqChks 0;
BA_ "GenSigFuncType" SG_ 816 ChrgnUReqChks 15;
BA_ "GenSigDataID" SG_ 816 ChrgnUReqChks "0x1BE0";
BA_ "GenSigSendType" SG_ 816 ChrgnUReqChrgnUReq 0;
BA_ "GenSigSendType" SG_ 816 ChrgnUReqCntr 0;
BA_ "GenSigFuncType" SG_ 816 ChrgnUReqCntr 16;
BA_ "GenSigSendType" SG_ 816 VehBattUSysU 0;
BA_ "GenSigSendType" SG_ 816 VehBattUSysUQf 0;
BA_ "GenSigStartValue" SG_ 816 VehBattUSysUQf 1;
BA_ "GenSigSendType" SG_ 881 AD4DrvrBeltWarn 0;
BA_ "GenSigSendType" SG_ 881 CarModCrashSaved 0;
BA_ "GenSigSendType" SG_ 881 DrvrSeatSnsrSts 0;
BA_ "GenSigSendType" SG_ 881 EngN2 0;
BA_ "GenSigSendType" SG_ 881 HvBattPreChrgReq 0;
BA_ "GenSigSendType" SG_ 881 IsgSpdActSgn 0;
BA_ "GenSigStartValue" SG_ 881 IsgSpdActSgn 20000;
BA_ "GenSigSendType" SG_ 881 PostImpctBrkgRdy 0;
BA_ "GenSigSendType" SG_ 881 RlyPwrDistbnCmd1WdPreBattSaveCmd 0;
BA_ "SystemSignalLongSymbol" SG_ 881 RlyPwrDistbnCmd1WdPreBattSa_0000 "RlyPwrDistbnCmd1WdPreBattSaveCmd_UB";
BA_ "GenSigSendType" SG_ 881 SeatOccptAtRowSecDrSide2 0;
BA_ "GenSigStartValue" SG_ 881 SeatOccptAtRowSecDrSide2 1;
BA_ "GenSigSendType" SG_ 881 SeatOccptAtRowSecDrSideSnsSts2 0;
BA_ "SystemSignalLongSymbol" SG_ 881 SeatOccptAtRowSecDrSideSnsSts2_U "SeatOccptAtRowSecDrSideSnsSts2_UB";
BA_ "GenSigSendType" SG_ 912 DispOfPrpsnMod 0;
BA_ "GenSigSendType" SG_ 912 DispOfPrpsnModForEv 0;
BA_ "GenSigSendType" SG_ 912 DrvrSeatPosPercSeatPosFrntHeiPer 0;
BA_ "GenSigStartValue" SG_ 912 DrvrSeatPosPercSeatPosFrntHeiPer 1000;
BA_ "SystemSignalLongSymbol" SG_ 912 DrvrSeatPosPercSeatPosFrntHeiPer "DrvrSeatPosPercSeatPosFrntHeiPerc";
BA_ "GenSigSendType" SG_ 912 DrvrSeatPosPercSeatPosFrntHeiQF 0;
BA_ "GenSigStartValue" SG_ 912 DrvrSeatPosPercSeatPosFrntHeiQF 1;
BA_ "GenSigSendType" SG_ 912 DrvrSeatPosPercSeatPosHeiPerc 0;
BA_ "GenSigStartValue" SG_ 912 DrvrSeatPosPercSeatPosHeiPerc 1000;
BA_ "GenSigSendType" SG_ 912 DrvrSeatPosPercSeatPosHeiQF 0;
BA_ "GenSigStartValue" SG_ 912 DrvrSeatPosPercSeatPosHeiQF 1;
BA_ "GenSigSendType" SG_ 912 DrvrSeatPosPercSeatPosSldPerc 0;
BA_ "GenSigStartValue" SG_ 912 DrvrSeatPosPercSeatPosSldPerc 1000;
BA_ "GenSigSendType" SG_ 912 DrvrSeatPosPercSeatPosSldQF 0;
BA_ "GenSigStartValue" SG_ 912 DrvrSeatPosPercSeatPosSldQF 1;
BA_ "GenSigStartValue" SG_ 912 PassAirbLampStsRec_UB 1;
BA_ "GenSigSendType" SG_ 912 PassAirbLampStsRecPassAirbLampSt 0;
BA_ "GenSigStartValue" SG_ 912 PassAirbLampStsRecPassAirbLampSt 1;
BA_ "SystemSignalLongSymbol" SG_ 912 PassAirbLampStsRecPassAirbLampSt "PassAirbLampStsRecPassAirbLampSts";
BA_ "GenSigSendType" SG_ 912 PassAirbLampStsRecPassAirbL_0000 0;
BA_ "GenSigFuncType" SG_ 912 PassAirbLampStsRecPassAirbL_0000 15;
BA_ "GenSigDataID" SG_ 912 PassAirbLampStsRecPassAirbL_0000 "0x474";
BA_ "GenSigStartValue" SG_ 912 PassAirbLampStsRecPassAirbL_0000 255;
BA_ "SystemSignalLongSymbol" SG_ 912 PassAirbLampStsRecPassAirbL_0000 "PassAirbLampStsRecPassAirbLampStsChks";
BA_ "GenSigSendType" SG_ 912 PassAirbLampStsRecPassAirbL_0001 0;
BA_ "GenSigFuncType" SG_ 912 PassAirbLampStsRecPassAirbL_0001 16;
BA_ "SystemSignalLongSymbol" SG_ 912 PassAirbLampStsRecPassAirbL_0001 "PassAirbLampStsRecPassAirbLampStsCntr";
BA_ "GenSigSendType" SG_ 912 RlyPwrDistbnCmd1WdIgnRlyExtCmd 0;
BA_ "SystemSignalLongSymbol" SG_ 912 RlyPwrDistbnCmd1WdIgnRlyExtCmd_U "RlyPwrDistbnCmd1WdIgnRlyExtCmd_UB";
BA_ "GenSigSendType" SG_ 924 RiFrntTireMsgBattLoSt 0;
BA_ "GenSigSendType" SG_ 924 RiFrntTireMsgFastLoseWarnFlg 0;
BA_ "GenSigSendType" SG_ 924 RiFrntTireMsgMsgOldFlg 0;
BA_ "GenSigSendType" SG_ 924 RiFrntTireMsgP 0;
BA_ "GenSigStartValue" SG_ 924 RiFrntTireMsgP 255;
BA_ "GenSigSendType" SG_ 924 RiFrntTireMsgPWarnFlg 0;
BA_ "GenSigSendType" SG_ 924 RiFrntTireMsgSysWarnFlg 0;
BA_ "GenSigSendType" SG_ 924 RiFrntTireMsgT 0;
BA_ "GenSigStartValue" SG_ 924 RiFrntTireMsgT 255;
BA_ "GenSigSendType" SG_ 924 RiFrntTireMsgTireFillgAssiPSts 0;
BA_ "GenSigSendType" SG_ 924 RiFrntTireMsgTWarnFlg 0;
BA_ "GenSigSendType" SG_ 924 RiReTireMsgBattLoSt 0;
BA_ "GenSigSendType" SG_ 924 RiReTireMsgFastLoseWarnFlg 0;
BA_ "GenSigSendType" SG_ 924 RiReTireMsgMsgOldFlg 0;
BA_ "GenSigSendType" SG_ 924 RiReTireMsgP 0;
BA_ "GenSigStartValue" SG_ 924 RiReTireMsgP 255;
BA_ "GenSigSendType" SG_ 924 RiReTireMsgPWarnFlg 0;
BA_ "GenSigSendType" SG_ 924 RiReTireMsgSysWarnFlg 0;
BA_ "GenSigSendType" SG_ 924 RiReTireMsgT 0;
BA_ "GenSigStartValue" SG_ 924 RiReTireMsgT 255;
BA_ "GenSigSendType" SG_ 924 RiReTireMsgTireFillgAssiPSts 0;
BA_ "GenSigSendType" SG_ 924 RiReTireMsgTWarnFlg 0;
BA_ "GenSigSendType" SG_ 904 AsyAutDrvCtrlTyp 0;
BA_ "GenSigSendType" SG_ 904 BrkAndAbsWarnIndcnReqAbsWarnIndc 0;
BA_ "GenSigStartValue" SG_ 904 BrkAndAbsWarnIndcnReqAbsWarnIndc 3;
BA_ "SystemSignalLongSymbol" SG_ 904 BrkAndAbsWarnIndcnReqAbsWarnIndc "BrkAndAbsWarnIndcnReqAbsWarnIndcnReq";
BA_ "GenSigSendType" SG_ 904 BrkAndAbsWarnIndcnReqBrkWarnIndc 0;
BA_ "GenSigStartValue" SG_ 904 BrkAndAbsWarnIndcnReqBrkWarnIndc 1;
BA_ "SystemSignalLongSymbol" SG_ 904 BrkAndAbsWarnIndcnReqBrkWarnIndc "BrkAndAbsWarnIndcnReqBrkWarnIndcnReq";
BA_ "GenSigSendType" SG_ 904 BrkAndAbsWarnIndcnReqChks 0;
BA_ "GenSigFuncType" SG_ 904 BrkAndAbsWarnIndcnReqChks 15;
BA_ "GenSigDataID" SG_ 904 BrkAndAbsWarnIndcnReqChks "0x65";
BA_ "GenSigSendType" SG_ 904 BrkAndAbsWarnIndcnReqCntr 0;
BA_ "GenSigFuncType" SG_ 904 BrkAndAbsWarnIndcnReqCntr 16;
BA_ "GenSigSendType" SG_ 904 CrsCtrlrActvnOk 0;
BA_ "GenSigSendType" SG_ 904 CrsCtrlrStbOk 0;
BA_ "GenSigSendType" SG_ 904 EscCtrlIndcn 0;
BA_ "GenSigStartValue" SG_ 904 EscCtrlIndcn 1;
BA_ "GenSigSendType" SG_ 904 SwtLiHzrdWarn 0;
BA_ "GenSigSendType" SG_ 870 DrvgAstOnSysSts 0;
BA_ "GenSigSendType" SG_ 870 HvacAirMFlowEstimd 0;
BA_ "GenSigSendType" SG_ 870 HvacAirMFlowReEstimd 0;
BA_ "GenSigSendType" SG_ 870 ReqForPassAirbIndcnAckd 0;
BA_ "GenSigSendType" SG_ 870 RlyPwrDistbnCmd1WdIgnRlyCmd 0;
BA_ "GenSigSendType" SG_ 870 SumActv 0;
BA_ "GenSigSendType" SG_ 800 AsyALgtStsAsyALgtSts 0;
BA_ "GenSigSendType" SG_ 800 AsyALgtStsChks 0;
BA_ "GenSigFuncType" SG_ 800 AsyALgtStsChks 15;
BA_ "GenSigDataID" SG_ 800 AsyALgtStsChks "0xAF0";
BA_ "GenSigSendType" SG_ 800 AsyALgtStsCntr 0;
BA_ "GenSigFuncType" SG_ 800 AsyALgtStsCntr 16;
BA_ "GenSigSendType" SG_ 800 DoorDrvrLockSts 0;
BA_ "GenSigSendType" SG_ 800 DoorLeReLockSts 0;
BA_ "GenSigSendType" SG_ 800 DoorPassLockSts 0;
BA_ "GenSigSendType" SG_ 800 DoorRiReLockSts 0;
BA_ "GenSigSendType" SG_ 385 EmgyAsscTrigSts 1;
BA_ "GenSigSendType" SG_ 900 BrkPedlrRatPerc 0;
BA_ "GenSigSendType" SG_ 900 BrkPedlrRatQf 0;
BA_ "GenSigSendType" SG_ 900 BrkTracCtrlActv 0;
BA_ "GenSigSendType" SG_ 900 CllsnMtgtnFctSts 0;
BA_ "GenSigStartValue" SG_ 900 CllsnMtgtnFctSts 2;
BA_ "GenSigSendType" SG_ 900 CrsCtrlrSts 0;
BA_ "GenSigStartValue" SG_ 900 CrsCtrlrSts 1;
BA_ "GenSigSendType" SG_ 900 DrvrCrsCtrlFctSeld 0;
BA_ "GenSigSendType" SG_ 900 EscStChks 0;
BA_ "GenSigFuncType" SG_ 900 EscStChks 15;
BA_ "GenSigDataID" SG_ 900 EscStChks "0x7F";
BA_ "GenSigSendType" SG_ 900 EscStCntr 0;
BA_ "GenSigFuncType" SG_ 900 EscStCntr 16;
BA_ "GenSigSendType" SG_ 900 EscStEscSt 0;
BA_ "GenSigStartValue" SG_ 900 EscStEscSt 1;
BA_ "GenSigSendType" SG_ 916 LeFrntTireMsgBattLoSt 0;
BA_ "GenSigSendType" SG_ 916 LeFrntTireMsgFastLoseWarnFlg 0;
BA_ "GenSigSendType" SG_ 916 LeFrntTireMsgMsgOldFlg 0;
BA_ "GenSigSendType" SG_ 916 LeFrntTireMsgP 0;
BA_ "GenSigStartValue" SG_ 916 LeFrntTireMsgP 255;
BA_ "GenSigSendType" SG_ 916 LeFrntTireMsgPWarnFlg 0;
BA_ "GenSigSendType" SG_ 916 LeFrntTireMsgSysWarnFlg 0;
BA_ "GenSigSendType" SG_ 916 LeFrntTireMsgT 0;
BA_ "GenSigStartValue" SG_ 916 LeFrntTireMsgT 255;
BA_ "GenSigSendType" SG_ 916 LeFrntTireMsgTireFillgAssiPSts 0;
BA_ "GenSigSendType" SG_ 916 LeFrntTireMsgTWarnFlg 0;
BA_ "GenSigSendType" SG_ 916 LeReTireMsgBattLoSt 0;
BA_ "GenSigSendType" SG_ 916 LeReTireMsgFastLoseWarnFlg 0;
BA_ "GenSigSendType" SG_ 916 LeReTireMsgMsgOldFlg 0;
BA_ "GenSigSendType" SG_ 916 LeReTireMsgP 0;
BA_ "GenSigStartValue" SG_ 916 LeReTireMsgP 255;
BA_ "GenSigSendType" SG_ 916 LeReTireMsgPWarnFlg 0;
BA_ "GenSigSendType" SG_ 916 LeReTireMsgSysWarnFlg 0;
BA_ "GenSigSendType" SG_ 916 LeReTireMsgT 0;
BA_ "GenSigStartValue" SG_ 916 LeReTireMsgT 255;
BA_ "GenSigSendType" SG_ 916 LeReTireMsgTireFillgAssiPSts 0;
BA_ "GenSigSendType" SG_ 916 LeReTireMsgTWarnFlg 0;
BA_ "GenSigSendType" SG_ 920 PassSeatPosPercSeatPosFrntHeiPer 0;
BA_ "GenSigStartValue" SG_ 920 PassSeatPosPercSeatPosFrntHeiPer 1000;
BA_ "SystemSignalLongSymbol" SG_ 920 PassSeatPosPercSeatPosFrntHeiPer "PassSeatPosPercSeatPosFrntHeiPerc";
BA_ "GenSigSendType" SG_ 920 PassSeatPosPercSeatPosFrntHeiQF 0;
BA_ "GenSigStartValue" SG_ 920 PassSeatPosPercSeatPosFrntHeiQF 1;
BA_ "GenSigSendType" SG_ 920 PassSeatPosPercSeatPosHeiPerc 0;
BA_ "GenSigStartValue" SG_ 920 PassSeatPosPercSeatPosHeiPerc 1000;
BA_ "GenSigSendType" SG_ 920 PassSeatPosPercSeatPosHeiQF 0;
BA_ "GenSigStartValue" SG_ 920 PassSeatPosPercSeatPosHeiQF 1;
BA_ "GenSigSendType" SG_ 920 PassSeatPosPercSeatPosSldPerc 0;
BA_ "GenSigStartValue" SG_ 920 PassSeatPosPercSeatPosSldPerc 1000;
BA_ "GenSigSendType" SG_ 920 PassSeatPosPercSeatPosSldQF 0;
BA_ "GenSigStartValue" SG_ 920 PassSeatPosPercSeatPosSldQF 1;
BA_ "GenSigSendType" SG_ 920 PinionSteerAgMax1 0;
BA_ "GenSigSendType" SG_ 888 PinionSteerAgGroupChks 0;
BA_ "GenSigFuncType" SG_ 888 PinionSteerAgGroupChks 15;
BA_ "GenSigDataID" SG_ 888 PinionSteerAgGroupChks "0x40D";
BA_ "GenSigSendType" SG_ 888 PinionSteerAgGroupCntr 0;
BA_ "GenSigFuncType" SG_ 888 PinionSteerAgGroupCntr 16;
BA_ "GenSigSendType" SG_ 888 PinionSteerAgGroupPinionSteerAg1 0;
BA_ "GenSigSendType" SG_ 888 PinionSteerAgGroupPinionSte_0000 0;
BA_ "GenSigStartValue" SG_ 888 PinionSteerAgGroupPinionSte_0000 1;
BA_ "SystemSignalLongSymbol" SG_ 888 PinionSteerAgGroupPinionSte_0000 "PinionSteerAgGroupPinionSteerAg1Qf";
BA_ "GenSigSendType" SG_ 888 PinionSteerAgGroupPinionSteerAgS 0;
BA_ "SystemSignalLongSymbol" SG_ 888 PinionSteerAgGroupPinionSteerAgS "PinionSteerAgGroupPinionSteerAgSpd1";
BA_ "GenSigSendType" SG_ 888 PinionSteerAgGroupPinionSte_0001 0;
BA_ "GenSigStartValue" SG_ 888 PinionSteerAgGroupPinionSte_0001 1;
BA_ "SystemSignalLongSymbol" SG_ 888 PinionSteerAgGroupPinionSte_0001 "PinionSteerAgGroupPinionSteerAgSpd1Qf";
BA_ "GenSigSendType" SG_ 888 PinionSteerAgGroupSteerWhlTq 0;
BA_ "GenSigSendType" SG_ 888 PinionSteerAgGroupSteerWhlTqQf 0;
BA_ "GenSigStartValue" SG_ 888 PinionSteerAgGroupSteerWhlTqQf 1;
BA_ "GenSigSendType" SG_ 837 AbsCtrlActvChks 0;
BA_ "GenSigFuncType" SG_ 837 AbsCtrlActvChks 15;
BA_ "GenSigDataID" SG_ 837 AbsCtrlActvChks "0xD06";
BA_ "GenSigSendType" SG_ 837 AbsCtrlActvCntr 0;
BA_ "GenSigFuncType" SG_ 837 AbsCtrlActvCntr 16;
BA_ "GenSigSendType" SG_ 837 AbsCtrlActvCtrlSts1 0;
BA_ "GenSigSendType" SG_ 837 AbsSts 0;
BA_ "GenSigSendType" SG_ 518 AccrPedlRatAccrPedlRat 0;
BA_ "GenSigSendType" SG_ 518 AccrPedlRatChks 0;
BA_ "GenSigFuncType" SG_ 518 AccrPedlRatChks 15;
BA_ "GenSigDataID" SG_ 518 AccrPedlRatChks "0x364";
BA_ "GenSigSendType" SG_ 518 AccrPedlRatCntr 0;
BA_ "GenSigFuncType" SG_ 518 AccrPedlRatCntr 16;
BA_ "GenSigSendType" SG_ 518 AccrPedlRatGrdt 0;
BA_ "GenSigSendType" SG_ 518 CllsnAidPost 0;
BA_ "GenSigSendType" SG_ 518 SldngDoorLeReModSts 0;
BA_ "GenSigSendType" SG_ 518 SldngDoorRiReModSts 0;
BA_ "GenSigSendType" SG_ 518 ThrPos 0;
BA_ "GenSigSendType" SG_ 518 TrlrLampChkAutReq 0;
BA_ "GenSigSendType" SG_ 518 TwbrRelsReq 0;
BA_ "GenSigSendType" SG_ 36 AccrpedlStsChks 0;
BA_ "GenSigFuncType" SG_ 36 AccrpedlStsChks 15;
BA_ "GenSigDataID" SG_ 36 AccrpedlStsChks "0x1781";
BA_ "GenSigSendType" SG_ 36 AccrpedlStsCntr 0;
BA_ "GenSigFuncType" SG_ 36 AccrpedlStsCntr 16;
BA_ "GenSigSendType" SG_ 36 AccrpedlStsFltSts 0;
BA_ "GenSigSendType" SG_ 815 BrkPedlPsdBrkPedlNotPsdSafe 0;
BA_ "GenSigSendType" SG_ 815 BrkPedlPsdBrkPedlPsd 0;
BA_ "GenSigSendType" SG_ 815 BrkPedlPsdChks 0;
BA_ "GenSigFuncType" SG_ 815 BrkPedlPsdChks 15;
BA_ "GenSigDataID" SG_ 815 BrkPedlPsdChks "0x38";
BA_ "GenSigSendType" SG_ 815 BrkPedlPsdCntr 0;
BA_ "GenSigFuncType" SG_ 815 BrkPedlPsdCntr 16;
BA_ "GenSigSendType" SG_ 815 BrkPedlPsdQf 0;
BA_ "GenSigSendType" SG_ 815 DrvrMonrAlrmReqFromDHU 0;
BA_ "GenSigSendType" SG_ 815 ThrdRowLeSeatDispMassgFctMassgIn 0;
BA_ "SystemSignalLongSymbol" SG_ 815 ThrdRowLeSeatDispMassgFctMassgIn "ThrdRowLeSeatDispMassgFctMassgInten";
BA_ "GenSigSendType" SG_ 815 ThrdRowLeSeatDispMassgFctMassgPr 0;
BA_ "SystemSignalLongSymbol" SG_ 815 ThrdRowLeSeatDispMassgFctMassgPr "ThrdRowLeSeatDispMassgFctMassgProg";
BA_ "GenSigSendType" SG_ 815 ThrdRowLeSeatDispMassgFctOnOffl2 0;
BA_ "GenSigStartValue" SG_ 815 ThrdRowLeSeatDispMassgFctOnOffl2 2;
BA_ "GenSigSendType" SG_ 815 ThrdRowRiSeatDispMassgFctMassgIn 0;
BA_ "SystemSignalLongSymbol" SG_ 815 ThrdRowRiSeatDispMassgFctMassgIn "ThrdRowRiSeatDispMassgFctMassgInten";
BA_ "GenSigSendType" SG_ 815 ThrdRowRiSeatDispMassgFctMassgPr 0;
BA_ "SystemSignalLongSymbol" SG_ 815 ThrdRowRiSeatDispMassgFctMassgPr "ThrdRowRiSeatDispMassgFctMassgProg";
BA_ "GenSigSendType" SG_ 815 ThrdRowRiSeatDispMassgFctOnOffl2 0;
BA_ "GenSigStartValue" SG_ 815 ThrdRowRiSeatDispMassgFctOnOffl2 2;
BA_ "GenSigSendType" SG_ 84 BrkSysCylPMstAct 0;
BA_ "GenSigStartValue" SG_ 84 BrkSysCylPMstAct 100;
BA_ "GenSigSendType" SG_ 84 BrkSysCylPMstActQf 0;
BA_ "GenSigStartValue" SG_ 84 BrkSysCylPMstActQf 1;
BA_ "GenSigSendType" SG_ 84 BrkSysCylPMstChks 0;
BA_ "GenSigFuncType" SG_ 84 BrkSysCylPMstChks 15;
BA_ "GenSigDataID" SG_ 84 BrkSysCylPMstChks "0xB7";
BA_ "GenSigSendType" SG_ 84 BrkSysCylPMstCntr 0;
BA_ "GenSigFuncType" SG_ 84 BrkSysCylPMstCntr 16;
BA_ "GenSigSendType" SG_ 84 BrkSysCylPMstTar 0;
BA_ "GenSigSendType" SG_ 84 BrkSysCylPMstVirt 0;
BA_ "GenSigSendType" SG_ 84 BrkSysCylPMstVirtQf 0;
BA_ "GenSigStartValue" SG_ 84 BrkSysCylPMstVirtQf 1;
BA_ "GenSigSendType" SG_ 84 DoorOpenwarnLeIndcn 0;
BA_ "GenSigSendType" SG_ 84 DoorOpenwarnRiIndcn 0;
BA_ "GenSigSendType" SG_ 84 LowrTailgOpenHmiReq 0;
BA_ "GenSigSendType" SG_ 131 CllsnFwdWarn 0;
BA_ "GenSigSendType" SG_ 131 CllsnThreat 0;
BA_ "GenSigSendType" SG_ 131 FctaIndcnLe 0;
BA_ "GenSigSendType" SG_ 131 FctaIndcnRi 0;
BA_ "GenSigSendType" SG_ 131 SftyDecelGroupSafeAsySftyDecelRe 0;
BA_ "SystemSignalLongSymbol" SG_ 131 SftyDecelGroupSafeAsySftyDecelRe "SftyDecelGroupSafeAsySftyDecelReq";
BA_ "GenSigSendType" SG_ 131 SftyDecelGroupSafeAsySftyEnaDece 0;
BA_ "SystemSignalLongSymbol" SG_ 131 SftyDecelGroupSafeAsySftyEnaDece "SftyDecelGroupSafeAsySftyEnaDecel";
BA_ "GenSigSendType" SG_ 131 SftyDecelGroupSafeChks 0;
BA_ "GenSigFuncType" SG_ 131 SftyDecelGroupSafeChks 15;
BA_ "GenSigDataID" SG_ 131 SftyDecelGroupSafeChks "0x4C";
BA_ "GenSigSendType" SG_ 131 SftyDecelGroupSafeCntr 0;
BA_ "GenSigFuncType" SG_ 131 SftyDecelGroupSafeCntr 16;
BA_ "GenSigSendType" SG_ 305 EpbStsChks 0;
BA_ "GenSigFuncType" SG_ 305 EpbStsChks 15;
BA_ "GenSigDataID" SG_ 305 EpbStsChks "0x84";
BA_ "GenSigSendType" SG_ 305 EpbStsCntr 0;
BA_ "GenSigFuncType" SG_ 305 EpbStsCntr 16;
BA_ "GenSigSendType" SG_ 305 EpbStsEpbSts 0;
BA_ "GenSigSendType" SG_ 305 VehSpdIndcdVehSpdIndcd 0;
BA_ "GenSigSendType" SG_ 305 VehSpdIndcdVeSpdIndcdUnit 0;
BA_ "GenSigSendType" SG_ 120 GearLvrIndcn 0;
BA_ "GenSigStartValue" SG_ 120 GearLvrIndcn 7;
BA_ "GenSigSendType" SG_ 120 OccupyMonStsDrvrSts 0;
BA_ "GenSigSendType" SG_ 120 OccupyMonStsPassSts 0;
BA_ "GenSigSendType" SG_ 120 OccupyMonStsSeccLeSts 0;
BA_ "GenSigSendType" SG_ 120 OccupyMonStsSecMidSts 0;
BA_ "GenSigSendType" SG_ 120 OccupyMonStsSecRiSts 0;
BA_ "GenSigSendType" SG_ 120 OccupyMonStsThrdLeSts 0;
BA_ "GenSigSendType" SG_ 120 OccupyMonStsThrdMidSts 0;
BA_ "GenSigSendType" SG_ 120 OccupyMonStsThrdRiSts 0;
BA_ "GenSigSendType" SG_ 120 SeatOccptAtRowSecPasSide2 0;
BA_ "GenSigStartValue" SG_ 120 SeatOccptAtRowSecPasSide2 1;
BA_ "GenSigSendType" SG_ 120 SeatOccptAtRowSecPasSideSnsSts2 0;
BA_ "SystemSignalLongSymbol" SG_ 120 SeatOccptAtRowSecPasSideSnsSts2_ "SeatOccptAtRowSecPasSideSnsSts2_UB";
BA_ "GenSigSendType" SG_ 120 SwtIndcrIndcrTypExtReq 0;
BA_ "GenSigSendType" SG_ 120 SwtIndcrIndcrTypExtReqChks 0;
BA_ "GenSigSendType" SG_ 120 SwtIndcrIndcrTypExtReqCntr 0;
BA_ "GenSigSendType" SG_ 120 SwtIndcrIndcrTypExtReqToUpdQf 0;
BA_ "GenSigStartValue" SG_ 120 SwtIndcrIndcrTypExtReqToUpdQf 1;
BA_ "GenSigSendType" SG_ 323 PosnBriefPosnLat 0;
BA_ "GenSigStartValue" SG_ 323 PosnBriefPosnLat 90;
BA_ "GenSigSendType" SG_ 323 PosnBriefPosnLgt 0;
BA_ "GenSigStartValue" SG_ 323 PosnBriefPosnLgt 180;
BA_ "GenSigSendType" SG_ 832 VehCfgPrmBlkIDBytePosn1 1;
BA_ "GenSigSendType" SG_ 832 VehCfgPrmCCPBytePosn2 1;
BA_ "GenSigSendType" SG_ 832 VehCfgPrmCCPBytePosn3 1;
BA_ "GenSigSendType" SG_ 832 VehCfgPrmCCPBytePosn4 1;
BA_ "GenSigSendType" SG_ 832 VehCfgPrmCCPBytePosn5 1;
BA_ "GenSigSendType" SG_ 832 VehCfgPrmCCPBytePosn6 1;
BA_ "GenSigSendType" SG_ 832 VehCfgPrmCCPBytePosn7 1;
BA_ "GenSigSendType" SG_ 832 VehCfgPrmCCPBytePosn8 1;
BA_ "GenSigSendType" SG_ 306 VehCfgPrmExtBlkIDBytePosn1 1;
BA_ "GenSigSendType" SG_ 306 VehCfgPrmExtCCPBytePosn2 1;
BA_ "GenSigSendType" SG_ 306 VehCfgPrmExtCCPBytePosn3 1;
BA_ "GenSigSendType" SG_ 306 VehCfgPrmExtCCPBytePosn4 1;
BA_ "GenSigSendType" SG_ 306 VehCfgPrmExtCCPBytePosn5 1;
BA_ "GenSigSendType" SG_ 306 VehCfgPrmExtCCPBytePosn6 1;
BA_ "GenSigSendType" SG_ 306 VehCfgPrmExtCCPBytePosn7 1;
BA_ "GenSigSendType" SG_ 306 VehCfgPrmExtCCPBytePosn8 1;
BA_ "GenSigSendType" SG_ 128 VinBlockNr 0;
BA_ "GenSigSendType" SG_ 128 VinVINSignalPos1 0;
BA_ "GenSigSendType" SG_ 128 VinVINSignalPos2 0;
BA_ "GenSigSendType" SG_ 128 VinVINSignalPos3 0;
BA_ "GenSigSendType" SG_ 128 VinVINSignalPos4 0;
BA_ "GenSigSendType" SG_ 128 VinVINSignalPos5 0;
BA_ "GenSigSendType" SG_ 128 VinVINSignalPos6 0;
BA_ "GenSigSendType" SG_ 128 VinVINSignalPos7 0;
BA_ "GenSigSendType" SG_ 118 DoorPassRealLockSts 0;
BA_ "GenSigSendType" SG_ 118 DoorPassReRealLockSts 0;
BA_ "GenSigSendType" SG_ 118 DoorSldngLeReRelsReq 0;
BA_ "GenSigSendType" SG_ 118 DoorSldngRiReRelsReq 0;
BA_ "GenSigSendType" SG_ 118 PassLockContnSts 0;
BA_ "GenSigStartValue" SG_ 118 VehSpdLgt_UB 1;
BA_ "GenSigSendType" SG_ 118 VehSpdLgtA 0;
BA_ "GenSigSendType" SG_ 118 VehSpdLgtChks 0;
BA_ "GenSigFuncType" SG_ 118 VehSpdLgtChks 15;
BA_ "GenSigDataID" SG_ 118 VehSpdLgtChks "0x37";
BA_ "GenSigSendType" SG_ 118 VehSpdLgtCntr 0;
BA_ "GenSigFuncType" SG_ 118 VehSpdLgtCntr 16;
BA_ "GenSigSendType" SG_ 118 VehSpdLgtQf 0;
BA_ "GenSigStartValue" SG_ 118 VehSpdLgtQf 1;
BA_ "GenSigSendType" SG_ 280 DoorDrvrRealLockSts 0;
BA_ "GenSigSendType" SG_ 280 DoorDrvrReRealLockSts 0;
BA_ "GenSigSendType" SG_ 280 DrvrLockContnSts 0;
BA_ "GenSigSendType" SG_ 280 TopPercTrFromHmi 0;
BA_ "GenSigStartValue" SG_ 280 TopPercTrFromHmi 101;
BA_ "GenSigSendType" SG_ 280 TrOpenPosnReqFromHmi 0;
BA_ "GenSigStartValue" SG_ 280 TrOpenPosnReqFromHmi 101;
BA_ "GenSigSendType" SG_ 280 TrRelsReq 0;
BA_ "GenSigSendType" SG_ 921 TrsmActrPosnSafeTrsmActrPosn 0;
BA_ "GenSigStartValue" SG_ 921 TrsmActrPosnSafeTrsmActrPosn 7;
BA_ "GenSigSendType" SG_ 921 TrsmActrPosnSafeTrsmActrPosnChks 0;
BA_ "GenSigFuncType" SG_ 921 TrsmActrPosnSafeTrsmActrPosnChks 15;
BA_ "GenSigDataID" SG_ 921 TrsmActrPosnSafeTrsmActrPosnChks "0x40";
BA_ "GenSigSendType" SG_ 921 TrsmActrPosnSafeTrsmActrPosnCntr 0;
BA_ "GenSigFuncType" SG_ 921 TrsmActrPosnSafeTrsmActrPosnCntr 16;
BA_ "GenSigSendType" SG_ 921 VehTiAndDataDataValid 0;
BA_ "GenSigSendType" SG_ 921 VehTiAndDataDay 0;
BA_ "GenSigStartValue" SG_ 921 VehTiAndDataDay 1;
BA_ "GenSigSendType" SG_ 921 VehTiAndDataHr1 0;
BA_ "GenSigSendType" SG_ 921 VehTiAndDataMins1 0;
BA_ "GenSigSendType" SG_ 921 VehTiAndDataMth1 0;
BA_ "GenSigStartValue" SG_ 921 VehTiAndDataMth1 1;
BA_ "GenSigSendType" SG_ 921 VehTiAndDataSec1 0;
BA_ "GenSigSendType" SG_ 921 VehTiAndDataYr1 0;
BA_ "GenSigSendType" SG_ 552 DrvrSeatAdpvLumSetg 0;
BA_ "GenSigSendType" SG_ 552 HmiSeatHeatgForRowSecLe 0;
BA_ "GenSigStartValue" SG_ 552 HmiSeatHeatgForRowSecLe 7;
BA_ "GenSigSendType" SG_ 552 HmiSeatHeatgForRowSecRi 0;
BA_ "GenSigStartValue" SG_ 552 HmiSeatHeatgForRowSecRi 7;
BA_ "GenSigSendType" SG_ 552 HmiSeatHeatgForRowThrdLe 0;
BA_ "GenSigStartValue" SG_ 552 HmiSeatHeatgForRowThrdLe 7;
BA_ "GenSigSendType" SG_ 552 HmiSeatHeatgForRowThrdRi 0;
BA_ "GenSigStartValue" SG_ 552 HmiSeatHeatgForRowThrdRi 7;
BA_ "GenSigSendType" SG_ 552 HmiSeatVentnForRowSecLe 0;
BA_ "GenSigStartValue" SG_ 552 HmiSeatVentnForRowSecLe 7;
BA_ "GenSigSendType" SG_ 552 HmiSeatVentnForRowSecRi 0;
BA_ "GenSigStartValue" SG_ 552 HmiSeatVentnForRowSecRi 7;
BA_ "GenSigSendType" SG_ 552 HmiSeatVentnForRowThrdLe 0;
BA_ "GenSigStartValue" SG_ 552 HmiSeatVentnForRowThrdLe 7;
BA_ "GenSigSendType" SG_ 552 HmiSeatVentnForRowThrdRi 0;
BA_ "GenSigStartValue" SG_ 552 HmiSeatVentnForRowThrdRi 7;
BA_ "GenSigSendType" SG_ 552 KeyScanActv 0;
BA_ "GenSigSendType" SG_ 552 PrkgStsToEDRAPATo 0;
BA_ "GenSigSendType" SG_ 552 PrkgStsToEDRHPATo 0;
BA_ "GenSigSendType" SG_ 552 PrkgStsToEDRLSDAandTBATo 0;
BA_ "GenSigSendType" SG_ 552 PrkgStsToEDRreserved1 0;
BA_ "GenSigSendType" SG_ 552 PrkgStsToEDRreserved2 0;
BA_ "GenSigSendType" SG_ 552 PrkgStsToEDRreserved3 0;
BA_ "GenSigSendType" SG_ 552 PrkgStsToEDRRPATo 0;
VAL_ 1290 WakeUpReasonsforTRM 741 "WakeupReasons_871868" 740 "WakeupReasons_871957" 739 "WakeupReasons_871729" 738 "WakeupReasons_700779" 737 "WakeupReasons_839414" 736 "WakeupReasons_675025" 735 "WakeupReasons_671146" 734 "WakeupReasons_1031929" 733 "WakeupReasons_1033548" 732 "WakeupReasons_1033537" 731 "WakeupReasons_1033479" 730 "WakeupReasons_1030765" 729 "WakeupReasons_1028674" 728 "WakeupReasons_1033567" 727 "WakeupReasons_1033543" 726 "WakeupReasons_1033549" 725 "WakeupReasons_1033554" 724 "WakeupReasons_1033563" 723 "WakeupReasons_1033558" 722 "WakeupReasons_1029384" 721 "WakeupReasons_1029383" 720 "WakeupReasons_1029382" 719 "WakeupReasons_1032619" 718 "WakeupReasons_1024928" 717 "WakeupReasons_1033547" 716 "WakeupReasons_1033541" 715 "WakeupReasons_1033562" 714 "WakeupReasons_1033564" 713 "WakeupReasons_986765" 712 "WakeupReasons_1026103" 711 "WakeupReasons_1030764" 710 "WakeupReasons_1030941" 709 "WakeupReasons_1033556" 708 "WakeupReasons_1033539" 707 "WakeupReasons_1033534" 706 "WakeupReasons_1032477" 705 "WakeupReasons_1031280" 704 "WakeupReasons_1033542" 703 "WakeupReasons_1033632" 702 "WakeupReasons_1033533" 701 "WakeupReasons_1029166" 700 "WakeupReasons_1033538" 699 "WakeupReasons_1031789" 698 "WakeupReasons_1033552" 697 "WakeupReasons_1033553" 696 "WakeupReasons_1033559" 695 "WakeupReasons_1033544" 694 "WakeupReasons_1033561" 693 "WakeupReasons_1031029" 692 "WakeupReasons_1030360" 691 "WakeupReasons_1030761" 690 "WakeupReasons_1033550" 689 "WakeupReasons_1032579" 688 "WakeupReasons_1033557" 687 "WakeupReasons_1031936" 686 "WakeupReasons_1033566" 685 "WakeupReasons_1033551" 684 "WakeupReasons_1033540" 683 "WakeupReasons_1030760" 682 "WakeupReasons_1029735" 681 "WakeupReasons_1033565" 680 "WakeupReasons_852370" 679 "WakeupReasons_1033555" 678 "WakeupReasons_1033546" 677 "WakeupReasons_1032743" 676 "WakeupReasons_1032791" 675 "WakeupReasons_1033569" 674 "WakeupReasons_1031030" 673 "WakeupReasons_1028778" 672 "WakeupReasons_1030759" 671 "WakeupReasons_1031907" 670 "WakeupReasons_1033560" 669 "WakeupReasons_1031288" 668 "WakeupReasons_1030302" 667 "WakeupReasons_1031765" 666 "WakeupReasons_1031990" 665 "WakeupReasons_1028729" 664 "WakeupReasons_1030362" 663 "WakeupReasons_1030361" 662 "WakeupReasons_1030297" 661 "WakeupReasons_1030293" 660 "WakeupReasons_527345" 659 "WakeupReasons_988154" 658 "WakeupReasons_533580" 657 "WakeupReasons_533581" 656 "WakeupReasons_533576" 655 "WakeupReasons_1030255" 654 "WakeupReasons_527348" 653 "WakeupReasons_533578" 652 "WakeupReasons_527347" 651 "WakeupReasons_527346" 650 "WakeupReasons_ADCUReserve" 649 "WakeupReasons_885767" 648 "WakeupReasons_909025" 647 "WakeupReasons_909026" 646 "WakeupReasons_858177" 645 "WakeupReasons_858169" 644 "WakeupReasons_858152" 643 "WakeupReasons_973575" 642 "WakeupReason_973574" 641 "WakeupReason_987405" 640 "WakeupReason_858187" 639 "WakeupReason_988826" 638 "WakeupReason_988821" 637 "WakeupReason_987485" 636 "WakeupReason_908128" 635 "WakeupReason_908115" 634 "WakeupReason_856234" 633 "WakeupReason_856224" 632 "WakeupReason_858189" 631 "WakeupReason_858188" 630 "WakeupReason_872056" 629 "WakeupReason_870276" 628 "WakeupReason_858191" 627 "WakeupReason_847054" 626 "WakeupReason_856465" 625 "WakeupReason_872253" 624 "WakeupReason_855003" 623 "WakeupReason_855002" 622 "WakeupReason_854947" 621 "WakeupReason_855134" 620 "WakeupReason_854839" 619 "WakeupReason_854999" 618 "WakeupReason_855029" 617 "WakeupReason_714340" 616 "WakeupReason_852947" 615 "WakeupReason_852944" 614 "WakeupReason_852646" 613 "WakeupReason_852537" 612 "WakeupReason_852388" 611 "WakeupReason_852385" 610 "WakeupReason_852298" 609 "WakeupReason_852273" 608 "WakeupReason_852248" 607 "WakeupReason_852219" 606 "WakeupReason_852218" 605 "WakeupReason_852215" 604 "WakeupReason_852200" 603 "WakeupReason_852195" 602 "WakeupReason_852194" 601 "WakeupReason_852184" 600 "WakeupReason_852180" 599 "WakeupReason_852050" 598 "WakeupReason_852010" 597 "WakeupReason_851743" 596 "WakeupReason_851482" 595 "WakeupReason_702420" 594 "WakeupReason_667533" 593 "WakeupReason_645735" 592 "WakeupReason_362462" 591 "WakeupReason_361474" 590 "WakeupReason_361441" 589 "WakeupReason_846002" 588 "WakeupReason_845930" 587 "WakeupReason_842273" 586 "WakeupReason_846372" 585 "WakeupReason_675489" 584 "WakeupReason_675452" 583 "WakeupReason_298032" 582 "WakeupReason_322113" 581 "WakeupReason_320145" 580 "WakeupReason_841275" 579 "WakeupReason_839787" 578 "WakeupReason_839181" 577 "WakeupReason_714677" 576 "WakeupReason_840035" 566 "WakeupReason_839458" 565 "WakeupReason_837760" 564 "WakeupReason_702903" 563 "WakeupReason_837962" 562 "WakeupReason_703140" 561 "WakeupReason_837833" 560 "WakeupReason_839705" 559 "WakeupReason_839473" 558 "WakeupReason_838116" 557 "WakeupReason_717832" 556 "WakeupReason_714697" 555 "WakeupReason_714799" 554 "WakeupReason_714806" 553 "WakeupReason_709196" 552 "WakeupReason_710893" 551 "WakeupReason_708964" 550 "WakeupReason_715529" 549 "WakeupReason_714265" 548 "WakeupReason_714172" 547 "WakeupReason_713799" 546 "WakeupReason_706194" 545 "WakeupReason_713568" 544 "WakeupReason_710807" 543 "WakeupReason_714679" 542 "WakeupReason_714678" 541 "WakeupReason_715842" 540 "WakeupReason_714030" 539 "WakeupReason_710922" 538 "WakeupReason_716243" 537 "WakeupReason_713786" 536 "WakeupReason_714675" 535 "WakeupReason_702478" 534 "WakeupReason_713752" 533 "WakeupReasons_700530" 532 "WakeupReasons_698631" 531 "WakeupReasons_702452" 530 "WakeupReasons_700565" 529 "WakeupReasons_702402" 528 "WakeupReasons_702439" 527 "WakeupReasons_702448" 526 "WakeupReasons_701872" 525 "WakeupReasons_699114" 524 "WakeupReasons_702240" 523 "WakeupReasons_701270" 522 "WakeupReasons_533751" 521 "WakeupReasons_698581" 520 "WakeupReasons_698130" 519 "WakeupReasons_700130" 518 "WakeupReasons_699921" 517 "WakeupReasons_699919" 516 "WakeupReasons_700486" 515 "WakeupReasons_700782" 514 "WakeupReasons_696971" 513 "WakeupReasons_700692" 512 "WakeupReasons_698385" 511 "WakeupReasons_699922" 510 "WakeupReasons_697967" 509 "WakeupReasons_700684" 508 "WakeupReasons_644379" 507 "WakeupReasons_336435" 506 "WakeupReasons_683263" 505 "WakeupReasons_700554" 504 "WakeupReasons_691992" 503 "WakeupReasons_698129" 502 "WakeupReasons_696850" 501 "WakeupReasons_702088" 500 "WakeupReasons_696612" 499 "WakeupReasons_691994" 498 "WakeupReasons_700483" 497 "WakeupReasons_702204" 496 "WakeupReasons_700603" 495 "WakeupReasons_700215" 494 "WakeupReasons_701509" 493 "WakeupReasons_701508" 492 "WakeupReasons_700484" 491 "WakeupReasons_217907" 490 "WakeupReasons_194966" 489 "WakeupReasons_702174" 488 "WakeupReasons_697145" 487 "WakeupReasons_296931" 486 "WakeupReasons_700687" 485 "WakeupReasons_700686" 484 "WakeupReasons_698409" 483 "WakeupReasons_533750" 482 "WakeupReasons_700467" 481 "WakeupReasons_687404" 480 "WakeupReasons_681813" 479 "WakeupReasons_698288" 478 "WakeupReasons_698660" 477 "WakeupReasons_691993" 476 "WakeupReasons_700485" 475 "WakeupReasons_700425" 474 "WakeupReasons_702197" 473 "WakeupReasons_637992" 472 "WakeupReasons_698488" 471 "WakeupReasons_691991" 470 "WakeupReasons_692547" 469 "WakeupReasons_693914" 468 "WakeupReasons_693024" 467 "WakeupReasons_693005" 466 "WakeupReasons_667949" 465 "WakeupReasons_686281" 464 "WakeupReasons_680764" 463 "WakeupReasons_512384" 462 "WakeupReasons_692019" 461 "WakeupReasons_533850" 460 "WakeupReasons_533849" 459 "WakeupReasons_667188" 458 "WakeupReasons_514652" 457 "WakeupReasons_514651" 456 "WakeupReasons_112024" 455 "WakeupReasons_300690" 454 "WakeupReasons_299532" 453 "WakeupReasons_299531" 452 "WakeupReasons_299120" 451 "WakeupReasons_273516" 450 "WakeupReasons_265694" 449 "WakeupReasons_692439" 448 "WakeupReasons_354831" 447 "WakeupReasons_680765" 446 "WakeupReasons_45895" 445 "WakeupReasons_644275" 444 "WakeupReasons_351189" 443 "WakeupReasons_226570" 442 "WakeupReasons_654489" 441 "WakeupReasons_110181" 440 "WakeupReasons_226569" 439 "WakeupReasons_45896" 438 "WakeupReasons_112031" 437 "WakeupReasons_110173" 436 "WakeupReasons_677781" 435 "WakeupReasons_690939" 434 "WakeupReasons_354809" 433 "WakeupReasons_692022" 432 "WakeupReasons_690593" 431 "WakeupReasons_226571" 430 "WakeupReasons_675594" 429 "WakeupReasons_226565" 428 "WakeupReasons_692020" 427 "WakeupReasons_112035" 426 "WakeupReasons_112027" 425 "WakeupReasons_354672" 424 "WakeupReasons_168967" 423 "WakeupReasons_354674" 422 "WakeupReasons_168968" 421 "WakeupReasons_641483" 420 "WakeupReasons_641482" 419 "WakeupReasons_265698" 418 "WakeupReasons_265699" 417 "WakeupReasons_360491" 416 "WakeupReasons_357498" 415 "WakeupReasons_170290" 414 "WakeupReasons_690385" 413 "WakeupReasons_692021" 412 "WakeupReasons_91254" 411 "WakeupReasons_346654" 410 "WakeupReasons_200637" 409 "WakeupReasons_170285" 408 "WakeupReasons_265678" 407 "WakeupReasons_683934" 406 "WakeupReasons_680763" 405 "WakeupReasons_682074" 404 "WakeupReasons_682154" 403 "WakeupReasons_682152" 402 "WakeupReasons_682155" 401 "WakeupReasons_682153" 400 "WakeupReasons_682078" 399 "WakeupReasons_682076" 398 "WakeupReasons_682077" 397 "WakeupReasons_676285" 396 "WakeupReasons_681023" 395 "WakeupReasons_682023" 394 "WakeupReasons_681789" 393 "WakeupReasons_682688" 392 "WakeupReasons_682037" 391 "WakeupReasons_682032" 390 "WakeupReasons_681915" 389 "WakeupReasons_674839" 388 "WakeupReasons_682034" 387 "WakeupReasons_681711" 386 "WakeupReasons_681031" 385 "WakeupReasons_681134" 384 "WakeupReasons_670462" 383 "WakeupReasons_681028" 382 "WakeupReasons_680975" 381 "WakeupReasons_680974" 380 "WakeupReasons_668523" 379 "WakeupReasons_669822" 378 "WakeupReasons_680712" 377 "WakeupReasons_671005" 376 "WakeupReasons_177214" 375 "WakeupReasons_45655" 374 "WakeupReasons_667872" 373 "WakeupReasons_264964" 372 "WakeupReasons_262871" 371 "WakeupReasons_264691" 370 "WakeupReasons_297056" 369 "WakeupReasons_233755" 368 "WakeupReasons_145161" 367 "WakeupReasons_667842" 366 "WakeupReasons_46020" 365 "WakeupReasons_667874" 364 "WakeupReasons_667981" 363 "WakeupReasons_224211" 362 "WakeupReasons_45902" 361 "WakeupReasons_329457" 360 "WakeupReasons_88458" 359 "WakeupReasons_45900" 358 "WakeupReasons_83199" 357 "WakeupReasons_532933" 356 "WakeupReasons_532932" 355 "WakeupReasons_670942" 354 "WakeupReasons_305818" 353 "WakeupReasons_75103" 352 "WakeupReasons_667987" 351 "WakeupReasons_667983" 350 "WakeupReasons_675745" 349 "WakeupReasons_356598" 348 "WakeupReasons_128671" 347 "WakeupReasons_69216" 346 "WakeupReasons_264697" 345 "WakeupReasons_264943" 344 "WakeupReasons_197644" 343 "WakeupReasons_675564" 342 "WakeupReasons_657120" 341 "WakeupReasons_265745" 340 "WakeupReasons_657121" 339 "WakeupReasons_667982" 338 "WakeupReasons_674223" 337 "WakeupReasons_127926" 336 "WakeupReasons_127924" 335 "WakeupReasons_262872" 334 "WakeupReasons_45848" 333 "WakeupReasons_45847" 332 "WakeupReasons_45846" 331 "WakeupReasons_667869" 330 "WakeupReasons_45890" 329 "WakeupReasons_45888" 328 "WakeupReasons_670962" 327 "WakeupReasons_667973" 326 "WakeupReasons_45877" 325 "WakeupReasons_667980" 324 "WakeupReasons_45876" 323 "WakeupReasons_45871" 322 "WakeupReasons_45875" 321 "WakeupReasons_45872" 320 "WakeupReasons_45870" 319 "WakeupReasons_45869" 318 "WakeupReasons_80608" 317 "WakeupReasons_45898" 316 "WakeupReasons_45897" 315 "WakeupReasons_69679" 314 "WakeupReasons_69678" 313 "WakeupReasons_45887" 312 "WakeupReasons_263473" 311 "WakeupReasons_265131" 310 "WakeupReasons_268983" 309 "WakeupReasons_139075" 308 "WakeupReasons_200090" 307 "WakeupReasons_199714" 306 "WakeupReasons_80609" 305 "WakeupReasons_106669" 304 "WakeupReasons_675742" 303 "WakeupReasons_46017" 302 "WakeupReasons_670354" 301 "WakeupReasons_667985" 300 "WakeupReasons_670966" 299 "WakeupReasons_667871" 298 "WakeupReasons_193474" 297 "WakeupReasons_113348" 296 "WakeupReasons_532556" 295 "WakeupReasons_532555" 294 "WakeupReasons_667988" 293 "WakeupReasons_182918" 292 "WakeupReasons_311279" 291 "WakeupReasons_667848" 290 "WakeupReasons_667850" 289 "WakeupReasons_668393" 288 "WakeupReasons_668395" 287 "WakeupReasons_670753" 286 "WakeupReasons_667922" 285 "WakeupReasons_669447" 284 "WakeupReasons_670928" 283 "WakeupReasons_669465" 282 "WakeupReasons_676265" 281 "WakeupReasons_667947" 280 "WakeupReasons_667879" 279 "WakeupReasons_675837" 278 "WakeupReasons_675494" 277 "WakeupReasons_674958" 276 "WakeupReasons_675064" 275 "WakeupReasons_674953" 274 "WakeupReasons_658188" 273 "WakeupReasons_337991" 272 "WakeupReasons_197653" 271 "WakeupReasons_269140" 270 "WakeupReasons_312881" 269 "WakeupReasons_215560" 268 "WakeupReasons_269034" 267 "WakeupReasons_4471" 266 "WakeupReasons_185490" 265 "WakeupReasons_185457" 264 "WakeupReasons_198452" 263 "WakeupReasons_200683" 262 "WakeupReasons_358832" 261 "WakeupReasons_NMPDUReceived" 260 "WakeupReasons_670345" 259 "WakeupReasons_109467" 258 "WakeupReasons_109466" 257 "WakeupReasons_636801" 256 "WakeupReasons_45849" 255 "WakeupReasons_45850" 254 "WakeupReasons_45851" 253 "WakeupReasons_45852" 252 "WakeupReasons_45854" 251 "WakeupReasons_45853" 250 "WakeupReasons_45856" 249 "WakeupReasons_533872" 248 "WakeupReasons_516327" 247 "WakeupReasons_359559" 246 "WakeupReasons_241902" 245 "WakeupReasons_533372" 244 "WakeupReasons_533371" 243 "WakeupReasons_533370" 242 "WakeupReasons_315981" 241 "WakeupReasons_45858" 240 "WakeupReasons_668529" 239 "WakeupReasons_670087" 238 "WakeupReasons_668531" 237 "WakeupReasons_223920" 236 "WakeupReasons_176748" 235 "WakeupReasons_146470" 234 "WakeupReasons_112799" 233 "WakeupReasons_95949" 232 "WakeupReasons_156440" 231 "WakeupReasons_166267" 230 "WakeupReasons_101727" 229 "WakeupReasons_101728" 228 "WakeupReasons_101725" 227 "WakeupReasons_101706" 226 "WakeupReasons_659350" 225 "WakeupReasons_667820" 224 "WakeupReasons_331194" 223 "WakeupReasons_652546" 222 "WakeupReasons_224553" 221 "WakeupReasons_224552" 220 "WakeupReasons_110885" 219 "WakeupReasons_667953" 218 "WakeupReasons_667962" 217 "WakeupReasons_224550" 216 "WakeupReasons_197665" 215 "WakeupReasons_225961" 214 "WakeupReasons_198433" 213 "WakeupReasons_526438" 212 "WakeupReasons_316796" 211 "WakeupReasons_335068" 210 "WakeupReasons_535214" 209 "WakeupReasons_264726" 208 "WakeupReasons_360542" 207 "WakeupReasons_531743" 206 "WakeupReasons_226967" 205 "WakeupReasons_318382" 204 "WakeupReasons_199159" 203 "WakeupReasons_223715" 202 "WakeupReasons_643973" 201 "WakeupReasons_319401" 200 "WakeupReasons_264712" 199 "WakeupReasons_526426" 198 "WakeupReasons_533050" 197 "WakeupReasons_265937" 196 "WakeupReasons_108834" 195 "WakeupReasons_636556" 194 "WakeupReasons_655340" 193 "WakeupReasons_320895" 192 "WakeupReasons_321077" 191 "WakeupReasons_321323" 190 "WakeupReasons_321319" 189 "WakeupReasons_321057" 188 "WakeupReasons_359187" 187 "WakeupReasons_321317" 186 "WakeupReasons_355214" 185 "WakeupReasons_652361" 184 "WakeupReasons_192030" 183 "WakeupReasons_534145" 182 "WakeupReasons_526445" 181 "WakeupReasons_360299" 180 "WakeupReasons_525705" 179 "WakeupReasons_534077" 178 "WakeupReasons_359211" 177 "WakeupReasons_300681" 176 "WakeupReasons_198484" 175 "WakeupReasons_356549" 174 "WakeupReasons_360543" 173 "WakeupReasons_318342" 172 "WakeupReasons_299547" 171 "WakeupReasons_646109" 170 "WakeupReasons_645753" 169 "WakeupReasons_514502" 168 "WakeupReasons_515804" 167 "WakeupReasons_298808" 166 "WakeupReasons_265330" 165 "WakeupReasons_265328" 164 "WakeupReasons_265305" 163 "WakeupReasons_361279" 162 "WakeupReasons_361272" 161 "WakeupReasons_160596" 160 "WakeupReasons_197648" 159 "WakeupReasons_658603" 158 "WakeupReasons_322857" 157 "WakeupReasons_108810" 156 "WakeupReasons_179103" 155 "WakeupReasons_321845" 154 "WakeupReasons_340667" 153 "WakeupReasons_299117" 152 "WakeupReasons_514503" 151 "WakeupReasons_532007" 150 "WakeupReasons_337565" 149 "WakeupReasons_320631" 148 "WakeupReasons_354791" 147 "WakeupReasons_317616" 146 "WakeupReasons_644550" 145 "WakeupReasons_265232" 144 "WakeupReasons_514545" 143 "WakeupReasons_526429" 142 "WakeupReasons_265569" 141 "WakeupReasons_108841" 140 "WakeupReasons_160602" 139 "WakeupReasons_160597" 138 "WakeupReasons_264958" 137 "WakeupReasons_300682" 136 "WakeupReasons_224634" 135 "WakeupReasons_224617" 134 "WakeupReasons_220322" 133 "WakeupReasons_300427" 132 "WakeupReasons_269156" 131 "WakeupReasons_145462" 130 "WakeupReasons_145454" 129 "WakeupReasons_145419" 128 "WakeupReasons_145288" 127 "WakeupReasons_145373" 126 "WakeupReasons_145385" 125 "WakeupReasons_145362" 124 "WakeupReasons_145399" 123 "WakeupReasons_145388" 122 "WakeupReasons_145330" 121 "WakeupReasons_152774" 120 "WakeupReasons_145319" 119 "WakeupReasons_145311" 118 "WakeupReasons_106774" 117 "WakeupReasons_533044" 116 "WakeupReasons_636692" 115 "WakeupReasons_355409" 114 "WakeupReasons_133749" 113 "WakeupReasons_156412" 112 "WakeupReasons_320287" 111 "WakeupReasons_201348" 110 "WakeupReasons_264962" 109 "WakeupReasons_169884" 108 "WakeupReasons_45867" 107 "WakeupReasons_45866" 106 "WakeupReasons_659549" 105 "WakeupReasons_45864" 104 "WakeupReasons_201815" 103 "WakeupReasons_224831" 102 "WakeupReasons_222553" 101 "WakeupReasons_140678" 100 "WakeupReasons_169945" 99 "WakeupReasons_95444" 98 "WakeupReasons_145688" 97 "WakeupReasons_356190" 96 "WakeupReasons_264934" 95 "WakeupReasons_264932" 94 "WakeupReasons_152786" 93 "WakeupReasons_144970" 92 "WakeupReasons_186489" 91 "WakeupReasons_144897" 90 "WakeupReasons_199172" 89 "WakeupReasons_145707" 88 "WakeupReasons_152237" 87 "WakeupReasons_67182" 86 "WakeupReasons_338820" 85 "WakeupReasons_634710" 84 "WakeupReasons_109387" 83 "WakeupReasons_320126" 82 "WakeupReasons_109367" 81 "WakeupReasons_315364" 80 "WakeupReasons_297868" 79 "WakeupReasons_645810" 78 "WakeupReasons_634696" 77 "WakeupReasons_138997" 76 "WakeupReasons_360006" 75 "WakeupReasons_224061" 74 "WakeupReasons_68481" 73 "WakeupReasons_109364" 72 "WakeupReasons_68644" 71 "WakeupReasons_224065" 70 "WakeupReasons_119273" 69 "WakeupReasons_109382" 68 "WakeupReasons_360008" 67 "WakeupReasons_68676" 66 "WakeupReasons_645094" 65 "WakeupReasons_361509" 64 "WakeupReasons_361505" 63 "WakeupReasons_360904" 62 "WakeupReasons_355601" 61 "WakeupReasons_320277" 60 "WakeupReasons_319422" 59 "WakeupReasons_320282" 58 "WakeupReasons_169894" 57 "WakeupReasons_266860" 56 "WakeupReasons_45656" 55 "WakeupReasons_21997" 54 "WakeupReasons_225696" 53 "WakeupReasons_200156" 52 "WakeupReasons_161066" 51 "WakeupReasons_185670" 50 "WakeupReasons_197826" 49 "WakeupReasons_176921" 48 "WakeupReasons_108776" 47 "WakeupReasons_265333" 46 "WakeupReasons_100281" 45 "WakeupReasons_100278" 44 "WakeupReasons_100300" 43 "WakeupReasons_100275" 42 "WakeupReasons_100298" 41 "WakeupReasons_319139" 40 "WakeupReasons_170807" 39 "WakeupReasons_200937" 38 "WakeupReasons_182033" 37 "WakeupReasons_191050" 36 "WakeupReasons_264876" 35 "WakeupReasons_197642" 34 "WakeupReasons_170865" 33 "WakeupReasons_168966" 32 "WakeupReasons_667948" 31 "WakeupReasons_169655" 30 "WakeupReasons_667945" 29 "WakeupReasons_74188" 28 "WakeupReasons_321583" 27 "WakeupReasons_88125" 26 "WakeupReasons_88123" 25 "WakeupReasons_91253" 24 "WakeupReasons_21973" 23 "WakeupReasons_140084" 22 "WakeupReasons_45657" 21 "WakeupReasons_45659" 20 "WakeupReasons_22100" 19 "WakeupReasons_22013" 18 "WakeupReasons_22005" 17 "WakeupReasons_45794" 16 "WakeupReasons_45793" 15 "WakeupReasons_21901" 14 "WakeupReasons_658500" 13 "WakeupReasons_269739" 12 "WakeupReasons_269735" 11 "WakeupReasons_269740" 10 "WakeupReasons_22060" 9 "WakeupReasons_49446" 8 "WakeupReasons_22058" 7 "WakeupReasons_45654" 6 "WakeupReasons_264933" 5 "WakeupReasons_197643" 4 "WakeupReasons_168965" 3 "WakeupReasons_667951" 2 "WakeupReasons_169654" 1 "WakeupReasons_667950" 0 "WakeupReasons_0" ;
VAL_ 1354 VFCVectorTRMVFCid0 1 "VFCOnOff_On" 0 "VFCOnOff_Off" ;
VAL_ 1354 VFCVectorTRMVFCid1 1 "VFCOnOff_On" 0 "VFCOnOff_Off" ;
VAL_ 1354 VFCVectorTRMVFCid10 1 "VFCOnOff_On" 0 "VFCOnOff_Off" ;
VAL_ 1354 VFCVectorTRMVFCid11 1 "VFCOnOff_On" 0 "VFCOnOff_Off" ;
VAL_ 1354 VFCVectorTRMVFCid12 1 "VFCOnOff_On" 0 "VFCOnOff_Off" ;
VAL_ 1354 VFCVectorTRMVFCid13 1 "VFCOnOff_On" 0 "VFCOnOff_Off" ;
VAL_ 1354 VFCVectorTRMVFCid14 1 "VFCOnOff_On" 0 "VFCOnOff_Off" ;
VAL_ 1354 VFCVectorTRMVFCid15 1 "VFCOnOff_On" 0 "VFCOnOff_Off" ;
VAL_ 1354 VFCVectorTRMVFCid16 1 "VFCOnOff_On" 0 "VFCOnOff_Off" ;
VAL_ 1354 VFCVectorTRMVFCid17 1 "VFCOnOff_On" 0 "VFCOnOff_Off" ;
VAL_ 1354 VFCVectorTRMVFCid18 1 "VFCOnOff_On" 0 "VFCOnOff_Off" ;
VAL_ 1354 VFCVectorTRMVFCid19 1 "VFCOnOff_On" 0 "VFCOnOff_Off" ;
VAL_ 1354 VFCVectorTRMVFCid2 1 "VFCOnOff_On" 0 "VFCOnOff_Off" ;
VAL_ 1354 VFCVectorTRMVFCid20 1 "VFCOnOff_On" 0 "VFCOnOff_Off" ;
VAL_ 1354 VFCVectorTRMVFCid21 1 "VFCOnOff_On" 0 "VFCOnOff_Off" ;
VAL_ 1354 VFCVectorTRMVFCid22 1 "VFCOnOff_On" 0 "VFCOnOff_Off" ;
VAL_ 1354 VFCVectorTRMVFCid23 1 "VFCOnOff_On" 0 "VFCOnOff_Off" ;
VAL_ 1354 VFCVectorTRMVFCid24 1 "VFCOnOff_On" 0 "VFCOnOff_Off" ;
VAL_ 1354 VFCVectorTRMVFCid25 1 "VFCOnOff_On" 0 "VFCOnOff_Off" ;
VAL_ 1354 VFCVectorTRMVFCid26 1 "VFCOnOff_On" 0 "VFCOnOff_Off" ;
VAL_ 1354 VFCVectorTRMVFCid27 1 "VFCOnOff_On" 0 "VFCOnOff_Off" ;
VAL_ 1354 VFCVectorTRMVFCid28 1 "VFCOnOff_On" 0 "VFCOnOff_Off" ;
VAL_ 1354 VFCVectorTRMVFCid29 1 "VFCOnOff_On" 0 "VFCOnOff_Off" ;
VAL_ 1354 VFCVectorTRMVFCid3 1 "VFCOnOff_On" 0 "VFCOnOff_Off" ;
VAL_ 1354 VFCVectorTRMVFCid30 1 "VFCOnOff_On" 0 "VFCOnOff_Off" ;
VAL_ 1354 VFCVectorTRMVFCid31 1 "VFCOnOff_On" 0 "VFCOnOff_Off" ;
VAL_ 1354 VFCVectorTRMVFCid32 1 "VFCOnOff_On" 0 "VFCOnOff_Off" ;
VAL_ 1354 VFCVectorTRMVFCid33 1 "VFCOnOff_On" 0 "VFCOnOff_Off" ;
VAL_ 1354 VFCVectorTRMVFCid34 1 "VFCOnOff_On" 0 "VFCOnOff_Off" ;
VAL_ 1354 VFCVectorTRMVFCid35 1 "VFCOnOff_On" 0 "VFCOnOff_Off" ;
VAL_ 1354 VFCVectorTRMVFCid36 1 "VFCOnOff_On" 0 "VFCOnOff_Off" ;
VAL_ 1354 VFCVectorTRMVFCid37 1 "VFCOnOff_On" 0 "VFCOnOff_Off" ;
VAL_ 1354 VFCVectorTRMVFCid38 1 "VFCOnOff_On" 0 "VFCOnOff_Off" ;
VAL_ 1354 VFCVectorTRMVFCid39 1 "VFCOnOff_On" 0 "VFCOnOff_Off" ;
VAL_ 1354 VFCVectorTRMVFCid4 1 "VFCOnOff_On" 0 "VFCOnOff_Off" ;
VAL_ 1354 VFCVectorTRMVFCid40 1 "VFCOnOff_On" 0 "VFCOnOff_Off" ;
VAL_ 1354 VFCVectorTRMVFCid41 1 "VFCOnOff_On" 0 "VFCOnOff_Off" ;
VAL_ 1354 VFCVectorTRMVFCid42 1 "VFCOnOff_On" 0 "VFCOnOff_Off" ;
VAL_ 1354 VFCVectorTRMVFCid43 1 "VFCOnOff_On" 0 "VFCOnOff_Off" ;
VAL_ 1354 VFCVectorTRMVFCid44 1 "VFCOnOff_On" 0 "VFCOnOff_Off" ;
VAL_ 1354 VFCVectorTRMVFCid45 1 "VFCOnOff_On" 0 "VFCOnOff_Off" ;
VAL_ 1354 VFCVectorTRMVFCid46 1 "VFCOnOff_On" 0 "VFCOnOff_Off" ;
VAL_ 1354 VFCVectorTRMVFCid47 1 "VFCOnOff_On" 0 "VFCOnOff_Off" ;
VAL_ 1354 VFCVectorTRMVFCid48 1 "VFCOnOff_On" 0 "VFCOnOff_Off" ;
VAL_ 1354 VFCVectorTRMVFCid49 1 "VFCOnOff_On" 0 "VFCOnOff_Off" ;
VAL_ 1354 VFCVectorTRMVFCid5 1 "VFCOnOff_On" 0 "VFCOnOff_Off" ;
VAL_ 1354 VFCVectorTRMVFCid50 1 "VFCOnOff_On" 0 "VFCOnOff_Off" ;
VAL_ 1354 VFCVectorTRMVFCid51 1 "VFCOnOff_On" 0 "VFCOnOff_Off" ;
VAL_ 1354 VFCVectorTRMVFCid52 1 "VFCOnOff_On" 0 "VFCOnOff_Off" ;
VAL_ 1354 VFCVectorTRMVFCid53 1 "VFCOnOff_On" 0 "VFCOnOff_Off" ;
VAL_ 1354 VFCVectorTRMVFCid54 1 "VFCOnOff_On" 0 "VFCOnOff_Off" ;
VAL_ 1354 VFCVectorTRMVFCid55 1 "VFCOnOff_On" 0 "VFCOnOff_Off" ;
VAL_ 1354 VFCVectorTRMVFCid56 1 "VFCOnOff_On" 0 "VFCOnOff_Off" ;
VAL_ 1354 VFCVectorTRMVFCid57 1 "VFCOnOff_On" 0 "VFCOnOff_Off" ;
VAL_ 1354 VFCVectorTRMVFCid58 1 "VFCOnOff_On" 0 "VFCOnOff_Off" ;
VAL_ 1354 VFCVectorTRMVFCid59 1 "VFCOnOff_On" 0 "VFCOnOff_Off" ;
VAL_ 1354 VFCVectorTRMVFCid6 1 "VFCOnOff_On" 0 "VFCOnOff_Off" ;
VAL_ 1354 VFCVectorTRMVFCid60 1 "VFCOnOff_On" 0 "VFCOnOff_Off" ;
VAL_ 1354 VFCVectorTRMVFCid61 1 "VFCOnOff_On" 0 "VFCOnOff_Off" ;
VAL_ 1354 VFCVectorTRMVFCid7 1 "VFCOnOff_On" 0 "VFCOnOff_Off" ;
VAL_ 1354 VFCVectorTRMVFCid8 1 "VFCOnOff_On" 0 "VFCOnOff_Off" ;
VAL_ 1354 VFCVectorTRMVFCid9 1 "VFCOnOff_On" 0 "VFCOnOff_Off" ;
VAL_ 1345 VFCVectorZCUDMVFCid0 1 "VFCOnOff_On" 0 "VFCOnOff_Off" ;
VAL_ 1345 VFCVectorZCUDMVFCid1 1 "VFCOnOff_On" 0 "VFCOnOff_Off" ;
VAL_ 1345 VFCVectorZCUDMVFCid10 1 "VFCOnOff_On" 0 "VFCOnOff_Off" ;
VAL_ 1345 VFCVectorZCUDMVFCid11 1 "VFCOnOff_On" 0 "VFCOnOff_Off" ;
VAL_ 1345 VFCVectorZCUDMVFCid12 1 "VFCOnOff_On" 0 "VFCOnOff_Off" ;
VAL_ 1345 VFCVectorZCUDMVFCid13 1 "VFCOnOff_On" 0 "VFCOnOff_Off" ;
VAL_ 1345 VFCVectorZCUDMVFCid14 1 "VFCOnOff_On" 0 "VFCOnOff_Off" ;
VAL_ 1345 VFCVectorZCUDMVFCid15 1 "VFCOnOff_On" 0 "VFCOnOff_Off" ;
VAL_ 1345 VFCVectorZCUDMVFCid16 1 "VFCOnOff_On" 0 "VFCOnOff_Off" ;
VAL_ 1345 VFCVectorZCUDMVFCid17 1 "VFCOnOff_On" 0 "VFCOnOff_Off" ;
VAL_ 1345 VFCVectorZCUDMVFCid18 1 "VFCOnOff_On" 0 "VFCOnOff_Off" ;
VAL_ 1345 VFCVectorZCUDMVFCid19 1 "VFCOnOff_On" 0 "VFCOnOff_Off" ;
VAL_ 1345 VFCVectorZCUDMVFCid2 1 "VFCOnOff_On" 0 "VFCOnOff_Off" ;
VAL_ 1345 VFCVectorZCUDMVFCid20 1 "VFCOnOff_On" 0 "VFCOnOff_Off" ;
VAL_ 1345 VFCVectorZCUDMVFCid21 1 "VFCOnOff_On" 0 "VFCOnOff_Off" ;
VAL_ 1345 VFCVectorZCUDMVFCid22 1 "VFCOnOff_On" 0 "VFCOnOff_Off" ;
VAL_ 1345 VFCVectorZCUDMVFCid23 1 "VFCOnOff_On" 0 "VFCOnOff_Off" ;
VAL_ 1345 VFCVectorZCUDMVFCid24 1 "VFCOnOff_On" 0 "VFCOnOff_Off" ;
VAL_ 1345 VFCVectorZCUDMVFCid25 1 "VFCOnOff_On" 0 "VFCOnOff_Off" ;
VAL_ 1345 VFCVectorZCUDMVFCid26 1 "VFCOnOff_On" 0 "VFCOnOff_Off" ;
VAL_ 1345 VFCVectorZCUDMVFCid27 1 "VFCOnOff_On" 0 "VFCOnOff_Off" ;
VAL_ 1345 VFCVectorZCUDMVFCid28 1 "VFCOnOff_On" 0 "VFCOnOff_Off" ;
VAL_ 1345 VFCVectorZCUDMVFCid29 1 "VFCOnOff_On" 0 "VFCOnOff_Off" ;
VAL_ 1345 VFCVectorZCUDMVFCid3 1 "VFCOnOff_On" 0 "VFCOnOff_Off" ;
VAL_ 1345 VFCVectorZCUDMVFCid30 1 "VFCOnOff_On" 0 "VFCOnOff_Off" ;
VAL_ 1345 VFCVectorZCUDMVFCid31 1 "VFCOnOff_On" 0 "VFCOnOff_Off" ;
VAL_ 1345 VFCVectorZCUDMVFCid32 1 "VFCOnOff_On" 0 "VFCOnOff_Off" ;
VAL_ 1345 VFCVectorZCUDMVFCid33 1 "VFCOnOff_On" 0 "VFCOnOff_Off" ;
VAL_ 1345 VFCVectorZCUDMVFCid34 1 "VFCOnOff_On" 0 "VFCOnOff_Off" ;
VAL_ 1345 VFCVectorZCUDMVFCid35 1 "VFCOnOff_On" 0 "VFCOnOff_Off" ;
VAL_ 1345 VFCVectorZCUDMVFCid36 1 "VFCOnOff_On" 0 "VFCOnOff_Off" ;
VAL_ 1345 VFCVectorZCUDMVFCid37 1 "VFCOnOff_On" 0 "VFCOnOff_Off" ;
VAL_ 1345 VFCVectorZCUDMVFCid38 1 "VFCOnOff_On" 0 "VFCOnOff_Off" ;
VAL_ 1345 VFCVectorZCUDMVFCid39 1 "VFCOnOff_On" 0 "VFCOnOff_Off" ;
VAL_ 1345 VFCVectorZCUDMVFCid4 1 "VFCOnOff_On" 0 "VFCOnOff_Off" ;
VAL_ 1345 VFCVectorZCUDMVFCid40 1 "VFCOnOff_On" 0 "VFCOnOff_Off" ;
VAL_ 1345 VFCVectorZCUDMVFCid41 1 "VFCOnOff_On" 0 "VFCOnOff_Off" ;
VAL_ 1345 VFCVectorZCUDMVFCid42 1 "VFCOnOff_On" 0 "VFCOnOff_Off" ;
VAL_ 1345 VFCVectorZCUDMVFCid43 1 "VFCOnOff_On" 0 "VFCOnOff_Off" ;
VAL_ 1345 VFCVectorZCUDMVFCid44 1 "VFCOnOff_On" 0 "VFCOnOff_Off" ;
VAL_ 1345 VFCVectorZCUDMVFCid45 1 "VFCOnOff_On" 0 "VFCOnOff_Off" ;
VAL_ 1345 VFCVectorZCUDMVFCid46 1 "VFCOnOff_On" 0 "VFCOnOff_Off" ;
VAL_ 1345 VFCVectorZCUDMVFCid47 1 "VFCOnOff_On" 0 "VFCOnOff_Off" ;
VAL_ 1345 VFCVectorZCUDMVFCid48 1 "VFCOnOff_On" 0 "VFCOnOff_Off" ;
VAL_ 1345 VFCVectorZCUDMVFCid49 1 "VFCOnOff_On" 0 "VFCOnOff_Off" ;
VAL_ 1345 VFCVectorZCUDMVFCid5 1 "VFCOnOff_On" 0 "VFCOnOff_Off" ;
VAL_ 1345 VFCVectorZCUDMVFCid50 1 "VFCOnOff_On" 0 "VFCOnOff_Off" ;
VAL_ 1345 VFCVectorZCUDMVFCid51 1 "VFCOnOff_On" 0 "VFCOnOff_Off" ;
VAL_ 1345 VFCVectorZCUDMVFCid52 1 "VFCOnOff_On" 0 "VFCOnOff_Off" ;
VAL_ 1345 VFCVectorZCUDMVFCid53 1 "VFCOnOff_On" 0 "VFCOnOff_Off" ;
VAL_ 1345 VFCVectorZCUDMVFCid54 1 "VFCOnOff_On" 0 "VFCOnOff_Off" ;
VAL_ 1345 VFCVectorZCUDMVFCid55 1 "VFCOnOff_On" 0 "VFCOnOff_Off" ;
VAL_ 1345 VFCVectorZCUDMVFCid56 1 "VFCOnOff_On" 0 "VFCOnOff_Off" ;
VAL_ 1345 VFCVectorZCUDMVFCid57 1 "VFCOnOff_On" 0 "VFCOnOff_Off" ;
VAL_ 1345 VFCVectorZCUDMVFCid58 1 "VFCOnOff_On" 0 "VFCOnOff_Off" ;
VAL_ 1345 VFCVectorZCUDMVFCid59 1 "VFCOnOff_On" 0 "VFCOnOff_Off" ;
VAL_ 1345 VFCVectorZCUDMVFCid6 1 "VFCOnOff_On" 0 "VFCOnOff_Off" ;
VAL_ 1345 VFCVectorZCUDMVFCid60 1 "VFCOnOff_On" 0 "VFCOnOff_Off" ;
VAL_ 1345 VFCVectorZCUDMVFCid61 1 "VFCOnOff_On" 0 "VFCOnOff_Off" ;
VAL_ 1345 VFCVectorZCUDMVFCid7 1 "VFCOnOff_On" 0 "VFCOnOff_Off" ;
VAL_ 1345 VFCVectorZCUDMVFCid8 1 "VFCOnOff_On" 0 "VFCOnOff_Off" ;
VAL_ 1345 VFCVectorZCUDMVFCid9 1 "VFCOnOff_On" 0 "VFCOnOff_Off" ;
VAL_ 64 DoorDrvrSts 2 "DoorSts2_Clsd" 1 "DoorSts2_Opend" 0 "DoorSts2_Ukwn" ;
VAL_ 64 DoorLeReSts 2 "DoorSts2_Clsd" 1 "DoorSts2_Opend" 0 "DoorSts2_Ukwn" ;
VAL_ 64 TrNoKeyPrsntAcoustReq 1 "OnOff1_On" 0 "OnOff1_Off" ;
VAL_ 64 TrOpenerReqTrigSrc 7 "TrOpenerTrigSrc1_TrByAppch" 6 "TrOpenerTrigSrc1_TrHMI" 5 "TrOpenerTrigSrc1_TrShutFace" 4 "TrOpenerTrigSrc1_TrHndlOutd" 3 "TrOpenerTrigSrc1_TrByFootOper" 2 "TrOpenerTrigSrc1_TrSwtIntr" 1 "TrOpenerTrigSrc1_TrKeyRem" 0 "TrOpenerTrigSrc1_TrNoTrigSrc" ;
VAL_ 64 TrOpenerReqTrOpenerReq 4 "TrOpenerReq1_TrOpenerClsDly" 3 "TrOpenerReq1_TrOpenerStop" 2 "TrOpenerReq1_TrOpenerCls" 1 "TrOpenerReq1_TrOpenerOpen" 0 "TrOpenerReq1_TrOpenerIdle" ;
VAL_ 64 TwliBriSts 1 "TwliBriSts1_Day" 0 "TwliBriSts1_Night" ;
VAL_ 64 VehMtnStVehMtnSt 7 "VehMtnSt2_RollgBackwVal2" 6 "VehMtnSt2_RollgBackwVal1" 5 "VehMtnSt2_RollgFwdVal2" 4 "VehMtnSt2_RollgFwdVal1" 3 "VehMtnSt2_StandStillVal3" 2 "VehMtnSt2_StandStillVal2" 1 "VehMtnSt2_StandStillVal1" 0 "VehMtnSt2_Ukwn" ;
VAL_ 1164 TiAndDateIndcnDataValid 1 "NoYes1_Yes" 0 "NoYes1_No" ;
VAL_ 224 DoorPassSts 2 "DoorSts2_Clsd" 1 "DoorSts2_Opend" 0 "DoorSts2_Ukwn" ;
VAL_ 224 DoorRiReSts 2 "DoorSts2_Clsd" 1 "DoorSts2_Opend" 0 "DoorSts2_Ukwn" ;
VAL_ 224 TopPosTrFromHmi 5 "PosPerc1_81to100PercTopPos" 4 "PosPerc1_61to80PercTopPos" 3 "PosPerc1_41to60PercTopPos" 2 "PosPerc1_21to40PercTopPos" 1 "PosPerc1_0to20PercTopPos" 0 "PosPerc1_NoReq" ;
VAL_ 224 TrlrLampChkReqFromHmi 3 "StrtStopReq1_Resd" 2 "StrtStopReq1_StopReq" 1 "StrtStopReq1_StrtReq" 0 "StrtStopReq1_Idle" ;
VAL_ 224 TrlrLiFogActvt 1 "OnOff1_On" 0 "OnOff1_Off" ;
VAL_ 224 TrPosnUpprProgmReq 1 "OnOff1_On" 0 "OnOff1_Off" ;
VAL_ 224 TrSts 2 "DoorSts2_Clsd" 1 "DoorSts2_Opend" 0 "DoorSts2_Ukwn" ;
VAL_ 240 TrlrLiPosnActvt 3 "OnOffCrit1_NotVld2" 2 "OnOffCrit1_On" 1 "OnOffCrit1_Off" 0 "OnOffCrit1_NotVld1" ;
VAL_ 240 VehModMngtGlbSafe1CarModSts1 5 "CarModSts1_CarModDyno" 3 "CarModSts1_CarModCrash" 2 "CarModSts1_CarModFcy" 1 "CarModSts1_CarModTrnsp" 0 "CarModSts1_CarModNorm" ;
VAL_ 240 VehModMngtGlbSafe1FltEgyCnsWdSts 1 "FltEgyCns1_Flt" 0 "FltEgyCns1_NoFlt" ;
VAL_ 240 VehModMngtGlbSafe1UsgModSts 13 "UsgModSts1_UsgModDrvg" 11 "UsgModSts1_UsgModActv" 2 "UsgModSts1_UsgModCnvinc" 1 "UsgModSts1_UsgModInActv" 0 "UsgModSts1_UsgModAbdnd" ;
VAL_ 880 AD4DrvrBeltWarnForBkp 4 "Resd2" 3 "Resd1" 2 "ActvnFHi" 1 "ActvnFLo" 0 "NoActvn" ;
VAL_ 880 EngSt1WdStsEngSt1WdSts 9 "EngSt1_AftRun" 8 "EngSt1_RunngRemStrtd" 7 "EngSt1_RunngStrtgInProgs" 6 "EngSt1_RunngStb" 5 "EngSt1_RunngRunng" 4 "EngSt1_StrtgInProgs" 3 "EngSt1_PreStrtg" 2 "EngSt1_Rdy" 1 "EngSt1_Awake" 0 "EngSt1_Ini" ;
VAL_ 816 VehBattUSysUQf 3 "GenQf1_AccurData" 2 "GenQf1_DataAccurNotWithinSpcn" 1 "GenQf1_TmpUndefdData" 0 "GenQf1_UndefindDataAccur" ;
VAL_ 881 AD4DrvrBeltWarn 4 "Resd2" 3 "Resd1" 2 "ActvnFHi" 1 "ActvnFLo" 0 "NoActvn" ;
VAL_ 881 CarModCrashSaved 1 "NoYes1_Yes" 0 "NoYes1_No" ;
VAL_ 881 DrvrSeatSnsrSts 3 "OkNokDi_Reserved" 2 "OkNokDi_Disabled" 1 "OkNokDi_NotOk" 0 "OkNokDi_Ok" ;
VAL_ 881 HvBattPreChrgReq 1 "OnOff1_On" 0 "OnOff1_Off" ;
VAL_ 881 PostImpctBrkgRdy 3 "PostImpctBrkgRdy_Resd" 2 "PostImpctBrkgRdy_Di" 1 "PostImpctBrkgRdy_Yes" 0 "PostImpctBrkgRdy_No" ;
VAL_ 881 RlyPwrDistbnCmd1WdPreBattSaveCmd 1 "OnOff1_On" 0 "OnOff1_Off" ;
VAL_ 881 SeatOccptAtRowSecDrSide2 3 "OccptPresSt1_Undefd2" 2 "OccptPresSt1_OccptPrsnt" 1 "OccptPresSt1_OccptNotPrsnt" 0 "OccptPresSt1_Undefd1" ;
VAL_ 881 SeatOccptAtRowSecDrSideSnsSts2 3 "OkNokDi_Reserved" 2 "OkNokDi_Disabled" 1 "OkNokDi_NotOk" 0 "OkNokDi_Ok" ;
VAL_ 912 DispOfPrpsnMod 15 "DispOfPrpsnMod4_PrpsnMotElecAndEngOn" 14 "DispOfPrpsnMod4_PrpsnMotElecAndEngChrgn" 13 "DispOfPrpsnMod4_Abnormal" 12 "DispOfPrpsnMod4_BrkgRgnAndEngOnAndChrgn" 11 "DispOfPrpsnMod4_BrkgRgnAndOnEng" 10 "DispOfPrpsnMod4_BrkgRgnAndEngOff" 9 "DispOfPrpsnMod4_NoPrpsnMotElecAndOnEngAndChrgn" 8 "DispOfPrpsnMod4_NoPrpsnMotElecAndOnEng" 7 "DispOfPrpsnMod4_NoPrpsnMotElecAndEngOff" 6 "DispOfPrpsnMod4_OnlyPrpsnMotElec" 5 "DispOfPrpsnMod4_OnlyEngPrpsnAndChrgn" 4 "DispOfPrpsnMod4_OnlyEngPrpsn" 3 "DispOfPrpsnMod4_PrpsnMotElecAndPrpsnEngAndChrgn" 2 "DispOfPrpsnMod4_PrpsnMotElecAndPrpsnEng" 1 "DispOfPrpsnMod4_ChrgnWithOnBdChrgr" 0 "DispOfPrpsnMod4_NotRdy" ;
VAL_ 912 DispOfPrpsnModForEv 15 "DispOfPrpsnModForEv_Reserved7" 14 "DispOfPrpsnModForEv_Invalid" 13 "DispOfPrpsnModForEv_Abnormal" 12 "DispOfPrpsnModForEv_Reserved6" 11 "DispOfPrpsnModForEv_Reserved5" 10 "DispOfPrpsnModForEv_Reserved4" 9 "DispOfPrpsnModForEv_Reserved3" 8 "DispOfPrpsnModForEv_Reserved2" 7 "DispOfPrpsnModForEv_Reserved1" 6 "DispOfPrpsnModForEv_Rgn" 5 "DispOfPrpsnModForEv_NoPrpsnMotElec" 4 "DispOfPrpsnModForEv_OnlyPrpsnMotElecRe" 3 "DispOfPrpsnModForEv_OnlyPrpsnMotElecFrnt" 2 "DispOfPrpsnModForEv_PureElecAWD" 1 "DispOfPrpsnModForEv_Charging" 0 "DispOfPrpsnModForEv_NotReady" ;
VAL_ 912 DrvrSeatPosPercSeatPosFrntHeiQF 3 "Qf1_DataCalcdWithDevDefd" 2 "Qf1_DevOfDataNotWithinRngAllwd" 1 "Qf1_DataTmpUndefdAndEvlnInProgs" 0 "Qf1_DevOfDataUndefd" ;
VAL_ 912 DrvrSeatPosPercSeatPosHeiQF 3 "Qf1_DataCalcdWithDevDefd" 2 "Qf1_DevOfDataNotWithinRngAllwd" 1 "Qf1_DataTmpUndefdAndEvlnInProgs" 0 "Qf1_DevOfDataUndefd" ;
VAL_ 912 DrvrSeatPosPercSeatPosSldQF 3 "Qf1_DataCalcdWithDevDefd" 2 "Qf1_DevOfDataNotWithinRngAllwd" 1 "Qf1_DataTmpUndefdAndEvlnInProgs" 0 "Qf1_DevOfDataUndefd" ;
VAL_ 912 PassAirbLampStsRecPassAirbLampSt 3 "PassAirbLampSts1_Resd2" 2 "PassAirbLampSts1_LampStsNotOk" 1 "PassAirbLampSts1_LampStsOk" 0 "PassAirbLampSts1_Resd1" ;
VAL_ 912 RlyPwrDistbnCmd1WdIgnRlyExtCmd 1 "OnOff1_On" 0 "OnOff1_Off" ;
VAL_ 924 RiFrntTireMsgBattLoSt 1 "Normalwarning_Warning" 0 "Normalwarning_Normal" ;
VAL_ 924 RiFrntTireMsgFastLoseWarnFlg 1 "Normalwarning_Warning" 0 "Normalwarning_Normal" ;
VAL_ 924 RiFrntTireMsgMsgOldFlg 1 "Normalwarning_Warning" 0 "Normalwarning_Normal" ;
VAL_ 924 RiFrntTireMsgPWarnFlg 3 "PWarnFlg_Reserve" 2 "PWarnFlg_HighPressureWarning" 1 "PWarnFlg_LowPressureWarning" 0 "PWarnFlg_Normal" ;
VAL_ 924 RiFrntTireMsgSysWarnFlg 1 "Normalwarning_Warning" 0 "Normalwarning_Normal" ;
VAL_ 924 RiFrntTireMsgTireFillgAssiPSts 1 "Normalwarning_Warning" 0 "Normalwarning_Normal" ;
VAL_ 924 RiFrntTireMsgTWarnFlg 1 "Normalwarning_Warning" 0 "Normalwarning_Normal" ;
VAL_ 924 RiReTireMsgBattLoSt 1 "Normalwarning_Warning" 0 "Normalwarning_Normal" ;
VAL_ 924 RiReTireMsgFastLoseWarnFlg 1 "Normalwarning_Warning" 0 "Normalwarning_Normal" ;
VAL_ 924 RiReTireMsgMsgOldFlg 1 "Normalwarning_Warning" 0 "Normalwarning_Normal" ;
VAL_ 924 RiReTireMsgPWarnFlg 3 "PWarnFlg_Reserve" 2 "PWarnFlg_HighPressureWarning" 1 "PWarnFlg_LowPressureWarning" 0 "PWarnFlg_Normal" ;
VAL_ 924 RiReTireMsgSysWarnFlg 1 "Normalwarning_Warning" 0 "Normalwarning_Normal" ;
VAL_ 924 RiReTireMsgTireFillgAssiPSts 1 "Normalwarning_Warning" 0 "Normalwarning_Normal" ;
VAL_ 924 RiReTireMsgTWarnFlg 1 "Normalwarning_Warning" 0 "Normalwarning_Normal" ;
VAL_ 904 AsyAutDrvCtrlTyp 3 "AsyAutDrvCtrlTyp_D2D" 2 "AsyAutDrvCtrlTyp_GPilot" 1 "AsyAutDrvCtrlTyp_ACC" 0 "AsyAutDrvCtrlTyp_Inactive" ;
VAL_ 904 BrkAndAbsWarnIndcnReqAbsWarnIndc 3 "AbsWarnIndcnReq_AbsWarnIndcnOffReq" 2 "AbsWarnIndcnReq_Resd2" 1 "AbsWarnIndcnReq_AbsWarnIndcnFlsgReq" 0 "AbsWarnIndcnReq_AbsWarnIndcnOnReq" ;
VAL_ 904 BrkAndAbsWarnIndcnReqBrkWarnIndc 1 "OnOff2_Off" 0 "OnOff2_On" ;
VAL_ 904 CrsCtrlrActvnOk 1 "OnOff1_On" 0 "OnOff1_Off" ;
VAL_ 904 CrsCtrlrStbOk 1 "OnOff1_On" 0 "OnOff1_Off" ;
VAL_ 904 EscCtrlIndcn 2 "DevSts1_Flt" 1 "DevSts1_Off" 0 "DevSts1_On" ;
VAL_ 904 SwtLiHzrdWarn 1 "PsdNotPsd_Psd" 0 "PsdNotPsd_NotPsd" ;
VAL_ 870 DrvgAstOnSysSts 9 "DrvgAstOnSysSts_Reserved3" 8 "DrvgAstOnSysSts_Reserved2" 7 "DrvgAstOnSysSts_Reserved1" 6 "DrvgAstOnSysSts_Failure" 5 "DrvgAstOnSysSts_Stop" 4 "DrvgAstOnSysSts_MRM" 3 "DrvgAstOnSysSts_Warning" 2 "DrvgAstOnSysSts_Standby" 1 "DrvgAstOnSysSts_OFF" 0 "DrvgAstOnSysSts_Default" ;
VAL_ 870 ReqForPassAirbIndcnAckd 1 "ReqForPassAirbIndcnAckd_MsgAckd" 0 "ReqForPassAirbIndcnAckd_Idle" ;
VAL_ 870 RlyPwrDistbnCmd1WdIgnRlyCmd 1 "OnOff1_On" 0 "OnOff1_Off" ;
VAL_ 870 SumActv 1 "Boolean_TRUE" 0 "Boolean_FALSE" ;
VAL_ 800 AsyALgtStsAsyALgtSts 9 "AsyALgtSts_Reserved3" 8 "AsyALgtSts_AccSts1_PermanentFailure" 7 "AsyALgtSts_AccSts1_TemporaryFailure" 6 "AsyALgtSts_AccSts1_StandWait" 5 "AsyALgtSts_AccSts1_StandActive" 4 "AsyALgtSts_AccSts1_Override" 3 "AsyALgtSts_Reserved2" 2 "AsyALgtSts_AccSts1_Active" 1 "AsyALgtSts_AccSts1_StandBy" 0 "AsyALgtSts_Reserved1" ;
VAL_ 800 DoorDrvrLockSts 3 "LockSts2_SafeLockd" 2 "LockSts2_Lockd" 1 "LockSts2_Unlckd" 0 "LockSts2_LockStsUkwn" ;
VAL_ 800 DoorLeReLockSts 3 "LockSts2_SafeLockd" 2 "LockSts2_Lockd" 1 "LockSts2_Unlckd" 0 "LockSts2_LockStsUkwn" ;
VAL_ 800 DoorPassLockSts 3 "LockSts2_SafeLockd" 2 "LockSts2_Lockd" 1 "LockSts2_Unlckd" 0 "LockSts2_LockStsUkwn" ;
VAL_ 800 DoorRiReLockSts 3 "LockSts2_SafeLockd" 2 "LockSts2_Lockd" 1 "LockSts2_Unlckd" 0 "LockSts2_LockStsUkwn" ;
VAL_ 385 EmgyAsscTrigSts 3 "AfsStsReq_Fault" 2 "AfsStsReq_ManuallySet" 1 "AfsStsReq_AutomaticallySet" 0 "AfsStsReq_Inactive" ;
VAL_ 900 BrkPedlrRatQf 3 "GenQf1_AccurData" 2 "GenQf1_DataAccurNotWithinSpcn" 1 "GenQf1_TmpUndefdData" 0 "GenQf1_UndefindDataAccur" ;
VAL_ 900 BrkTracCtrlActv 1 "CtrlSts1_InCtrl" 0 "CtrlSts1_NoCtrl" ;
VAL_ 900 CllsnMtgtnFctSts 7 "CllsnMtgtnFctSts_Reserved3" 6 "CllsnMtgtnFctSts_Reserved2" 5 "CllsnMtgtnFctSts_AEB_PEDNotAvalid" 4 "CllsnMtgtnFctSts_PermenentError" 3 "CllsnMtgtnFctSts_TemporaryError" 2 "CllsnMtgtnFctSts_ON" 1 "CllsnMtgtnFctSts_OFF" 0 "CllsnMtgtnFctSts_Reserved1" ;
VAL_ 900 CrsCtrlrSts 3 "CrsCtrlrSts1_Actv" 2 "CrsCtrlrSts1_Stb" 1 "CrsCtrlrSts1_Off" ;
VAL_ 900 DrvrCrsCtrlFctSeld 7 "DrvrCrsCtrlFctSeldTyp_OffRoadCrsCtrlFc" 6 "DrvrCrsCtrlFctSeldTyp_AccFct_Resu" 5 "DrvrCrsCtrlFctSeldTyp_AccFct_Main_Swt" 4 "DrvrCrsCtrlFctSeldTyp_CrsCtrlFct_Resu" 3 "DrvrCrsCtrlFctSeldTyp_CrsCtrlFct_Main_Swt" 2 "DrvrCrsCtrlFctSeldTyp_SpdLimFct_Resu" 1 "DrvrCrsCtrlFctSeldTyp_SpdLimFct_Main_Swt" 0 "DrvrCrsCtrlFctSeldTyp_Off" ;
VAL_ 900 EscStEscSt 4 "EscSt1_UsrOff" 3 "EscSt1_PrmntErr" 2 "EscSt1_TmpErr" 1 "EscSt1_Ok" 0 "EscSt1_Inin" ;
VAL_ 916 LeFrntTireMsgBattLoSt 1 "Normalwarning_Warning" 0 "Normalwarning_Normal" ;
VAL_ 916 LeFrntTireMsgFastLoseWarnFlg 1 "Normalwarning_Warning" 0 "Normalwarning_Normal" ;
VAL_ 916 LeFrntTireMsgMsgOldFlg 1 "Normalwarning_Warning" 0 "Normalwarning_Normal" ;
VAL_ 916 LeFrntTireMsgPWarnFlg 3 "PWarnFlg_Reserve" 2 "PWarnFlg_HighPressureWarning" 1 "PWarnFlg_LowPressureWarning" 0 "PWarnFlg_Normal" ;
VAL_ 916 LeFrntTireMsgSysWarnFlg 1 "Normalwarning_Warning" 0 "Normalwarning_Normal" ;
VAL_ 916 LeFrntTireMsgTireFillgAssiPSts 1 "Normalwarning_Warning" 0 "Normalwarning_Normal" ;
VAL_ 916 LeFrntTireMsgTWarnFlg 1 "Normalwarning_Warning" 0 "Normalwarning_Normal" ;
VAL_ 916 LeReTireMsgBattLoSt 1 "Normalwarning_Warning" 0 "Normalwarning_Normal" ;
VAL_ 916 LeReTireMsgFastLoseWarnFlg 1 "Normalwarning_Warning" 0 "Normalwarning_Normal" ;
VAL_ 916 LeReTireMsgMsgOldFlg 1 "Normalwarning_Warning" 0 "Normalwarning_Normal" ;
VAL_ 916 LeReTireMsgPWarnFlg 3 "PWarnFlg_Reserve" 2 "PWarnFlg_HighPressureWarning" 1 "PWarnFlg_LowPressureWarning" 0 "PWarnFlg_Normal" ;
VAL_ 916 LeReTireMsgSysWarnFlg 1 "Normalwarning_Warning" 0 "Normalwarning_Normal" ;
VAL_ 916 LeReTireMsgTireFillgAssiPSts 1 "Normalwarning_Warning" 0 "Normalwarning_Normal" ;
VAL_ 916 LeReTireMsgTWarnFlg 1 "Normalwarning_Warning" 0 "Normalwarning_Normal" ;
VAL_ 920 PassSeatPosPercSeatPosFrntHeiQF 3 "Qf1_DataCalcdWithDevDefd" 2 "Qf1_DevOfDataNotWithinRngAllwd" 1 "Qf1_DataTmpUndefdAndEvlnInProgs" 0 "Qf1_DevOfDataUndefd" ;
VAL_ 920 PassSeatPosPercSeatPosHeiQF 3 "Qf1_DataCalcdWithDevDefd" 2 "Qf1_DevOfDataNotWithinRngAllwd" 1 "Qf1_DataTmpUndefdAndEvlnInProgs" 0 "Qf1_DevOfDataUndefd" ;
VAL_ 920 PassSeatPosPercSeatPosSldQF 3 "Qf1_DataCalcdWithDevDefd" 2 "Qf1_DevOfDataNotWithinRngAllwd" 1 "Qf1_DataTmpUndefdAndEvlnInProgs" 0 "Qf1_DevOfDataUndefd" ;
VAL_ 888 PinionSteerAgGroupPinionSte_0000 3 "GenQf1_AccurData" 2 "GenQf1_DataAccurNotWithinSpcn" 1 "GenQf1_TmpUndefdData" 0 "GenQf1_UndefindDataAccur" ;
VAL_ 888 PinionSteerAgGroupPinionSte_0001 3 "GenQf1_AccurData" 2 "GenQf1_DataAccurNotWithinSpcn" 1 "GenQf1_TmpUndefdData" 0 "GenQf1_UndefindDataAccur" ;
VAL_ 888 PinionSteerAgGroupSteerWhlTqQf 3 "GenQf1_AccurData" 2 "GenQf1_DataAccurNotWithinSpcn" 1 "GenQf1_TmpUndefdData" 0 "GenQf1_UndefindDataAccur" ;
VAL_ 837 AbsCtrlActvCtrlSts1 1 "CtrlSts1_InCtrl" 0 "CtrlSts1_NoCtrl" ;
VAL_ 837 AbsSts 1 "DevErrSts2_Flt" 0 "DevErrSts2_NoFlt" ;
VAL_ 518 CllsnAidPost 1 "OnOff1_On" 0 "OnOff1_Off" ;
VAL_ 518 SldngDoorLeReModSts 1 "DoorModSts_Manual" 0 "DoorModSts_Electronal" ;
VAL_ 518 SldngDoorRiReModSts 1 "DoorModSts_Manual" 0 "DoorModSts_Electronal" ;
VAL_ 518 TrlrLampChkAutReq 1 "OnOff1_On" 0 "OnOff1_Off" ;
VAL_ 518 TwbrRelsReq 2 "OnOffNoReq_Off" 1 "OnOffNoReq_On" 0 "OnOffNoReq_NoReq" ;
VAL_ 36 AccrpedlStsFltSts 1 "Flt_Fault" 0 "Flt_NoFault" ;
VAL_ 815 BrkPedlPsdBrkPedlNotPsdSafe 1 "NoYes1_Yes" 0 "NoYes1_No" ;
VAL_ 815 BrkPedlPsdBrkPedlPsd 1 "NoYes1_Yes" 0 "NoYes1_No" ;
VAL_ 815 BrkPedlPsdQf 3 "GenQf1_AccurData" 2 "GenQf1_DataAccurNotWithinSpcn" 1 "GenQf1_TmpUndefdData" 0 "GenQf1_UndefindDataAccur" ;
VAL_ 815 ThrdRowLeSeatDispMassgFctMassgIn 3 "MassgIntenLvl_Off" 2 "MassgIntenLvl_IntenHi" 1 "MassgIntenLvl_IntenNorm" 0 "MassgIntenLvl_IntenLo" ;
VAL_ 815 ThrdRowLeSeatDispMassgFctMassgPr 7 "MassgProgTyp_Prog8" 6 "MassgProgTyp_Prog7" 5 "MassgProgTyp_Prog6" 4 "MassgProgTyp_Prog5" 3 "MassgProgTyp_Prog4" 2 "MassgProgTyp_Prog3" 1 "MassgProgTyp_Prog2" 0 "MassgProgTyp_Prog1" ;
VAL_ 815 ThrdRowLeSeatDispMassgFctOnOffl2 2 "OnOffl2_Idle" 1 "OnOffl2_On" 0 "OnOffl2_Off" ;
VAL_ 815 ThrdRowRiSeatDispMassgFctMassgIn 3 "MassgIntenLvl_Off" 2 "MassgIntenLvl_IntenHi" 1 "MassgIntenLvl_IntenNorm" 0 "MassgIntenLvl_IntenLo" ;
VAL_ 815 ThrdRowRiSeatDispMassgFctMassgPr 7 "MassgProgTyp_Prog8" 6 "MassgProgTyp_Prog7" 5 "MassgProgTyp_Prog6" 4 "MassgProgTyp_Prog5" 3 "MassgProgTyp_Prog4" 2 "MassgProgTyp_Prog3" 1 "MassgProgTyp_Prog2" 0 "MassgProgTyp_Prog1" ;
VAL_ 815 ThrdRowRiSeatDispMassgFctOnOffl2 2 "OnOffl2_Idle" 1 "OnOffl2_On" 0 "OnOffl2_Off" ;
VAL_ 84 BrkSysCylPMstActQf 3 "GenQf1_AccurData" 2 "GenQf1_DataAccurNotWithinSpcn" 1 "GenQf1_TmpUndefdData" 0 "GenQf1_UndefindDataAccur" ;
VAL_ 84 BrkSysCylPMstVirtQf 3 "GenQf1_AccurData" 2 "GenQf1_DataAccurNotWithinSpcn" 1 "GenQf1_TmpUndefdData" 0 "GenQf1_UndefindDataAccur" ;
VAL_ 84 DoorOpenwarnLeIndcn 3 "LcmaIndcn_LcmaWarnLvl2" 2 "LcmaIndcn_NotUsed" 1 "LcmaIndcn_LcmaWarnLvl1" 0 "LcmaIndcn_NoLcmaWarn" ;
VAL_ 84 DoorOpenwarnRiIndcn 3 "LcmaIndcn_LcmaWarnLvl2" 2 "LcmaIndcn_NotUsed" 1 "LcmaIndcn_LcmaWarnLvl1" 0 "LcmaIndcn_NoLcmaWarn" ;
VAL_ 84 LowrTailgOpenHmiReq 3 "DoorOpenerStop" 2 "DoorOpenerCls" 1 "DoorOpenerOpen" 0 "DoorOpenerIdle" ;
VAL_ 131 CllsnFwdWarn 2 "CllsnFwdWarnReq_LatentWarning" 1 "CllsnFwdWarnReq_WarningActive" 0 "CllsnFwdWarnReq_NoWarning" ;
VAL_ 131 CllsnThreat 3 "CllsnThreat1_ThreatHi" 2 "CllsnThreat1_ThreatMed" 1 "CllsnThreat1_ThreatLo" 0 "CllsnThreat1_Ukwn" ;
VAL_ 131 FctaIndcnLe 3 "LcmaIndcn_LcmaWarnLvl2" 2 "LcmaIndcn_NotUsed" 1 "LcmaIndcn_LcmaWarnLvl1" 0 "LcmaIndcn_NoLcmaWarn" ;
VAL_ 131 FctaIndcnRi 3 "LcmaIndcn_LcmaWarnLvl2" 2 "LcmaIndcn_NotUsed" 1 "LcmaIndcn_LcmaWarnLvl1" 0 "LcmaIndcn_NoLcmaWarn" ;
VAL_ 131 SftyDecelGroupSafeAsySftyEnaDece 1 "OnOff1_On" 0 "OnOff1_Off" ;
VAL_ 305 EpbStsEpbSts 15 "EpbSts_Err" 14 "EpbSts_Resd14" 13 "EpbSts_Resd13" 12 "EpbSts_BrkgDyn" 11 "EpbSts_Resd11" 10 "EpbSts_BrkgDynDegraded" 9 "EpbSts_ActrAllReld" 8 "EpbSts_Resd8" 7 "EpbSts_Resd7" 6 "EpbSts_BrkgDynByActr" 5 "EpbSts_AllInTran" 4 "EpbSts_Resd4" 3 "EpbSts_AllAppld" 2 "EpbSts_Resd2" 1 "EpbSts_Resd1" 0 "EpbSts_Resd0" ;
VAL_ 305 VehSpdIndcdVeSpdIndcdUnit 2 "VehSpdIndcdUnit_UkwnUnit" 1 "VehSpdIndcdUnit_Mph" 0 "VehSpdIndcdUnit_Kmph" ;
VAL_ 120 GearLvrIndcn 7 "GearLvrIndcn2_Undefd" 6 "GearLvrIndcn2_Resd2" 5 "GearLvrIndcn2_Resd1" 4 "GearLvrIndcn2_ManModeIndcn" 3 "GearLvrIndcn2_DrvIndcn" 2 "GearLvrIndcn2_NeutIndcn" 1 "GearLvrIndcn2_RvsIndcn" 0 "GearLvrIndcn2_ParkIndcn" ;
VAL_ 120 OccupyMonStsDrvrSts 3 "OccptPresSt1_Undefd2" 2 "OccptPresSt1_OccptPrsnt" 1 "OccptPresSt1_OccptNotPrsnt" 0 "OccptPresSt1_Undefd1" ;
VAL_ 120 OccupyMonStsPassSts 3 "OccptPresSt1_Undefd2" 2 "OccptPresSt1_OccptPrsnt" 1 "OccptPresSt1_OccptNotPrsnt" 0 "OccptPresSt1_Undefd1" ;
VAL_ 120 OccupyMonStsSeccLeSts 3 "OccptPresSt1_Undefd2" 2 "OccptPresSt1_OccptPrsnt" 1 "OccptPresSt1_OccptNotPrsnt" 0 "OccptPresSt1_Undefd1" ;
VAL_ 120 OccupyMonStsSecMidSts 3 "OccptPresSt1_Undefd2" 2 "OccptPresSt1_OccptPrsnt" 1 "OccptPresSt1_OccptNotPrsnt" 0 "OccptPresSt1_Undefd1" ;
VAL_ 120 OccupyMonStsSecRiSts 3 "OccptPresSt1_Undefd2" 2 "OccptPresSt1_OccptPrsnt" 1 "OccptPresSt1_OccptNotPrsnt" 0 "OccptPresSt1_Undefd1" ;
VAL_ 120 OccupyMonStsThrdLeSts 3 "OccptPresSt1_Undefd2" 2 "OccptPresSt1_OccptPrsnt" 1 "OccptPresSt1_OccptNotPrsnt" 0 "OccptPresSt1_Undefd1" ;
VAL_ 120 OccupyMonStsThrdMidSts 3 "OccptPresSt1_Undefd2" 2 "OccptPresSt1_OccptPrsnt" 1 "OccptPresSt1_OccptNotPrsnt" 0 "OccptPresSt1_Undefd1" ;
VAL_ 120 OccupyMonStsThrdRiSts 3 "OccptPresSt1_Undefd2" 2 "OccptPresSt1_OccptPrsnt" 1 "OccptPresSt1_OccptNotPrsnt" 0 "OccptPresSt1_Undefd1" ;
VAL_ 120 SeatOccptAtRowSecPasSide2 3 "OccptPresSt1_Undefd2" 2 "OccptPresSt1_OccptPrsnt" 1 "OccptPresSt1_OccptNotPrsnt" 0 "OccptPresSt1_Undefd1" ;
VAL_ 120 SeatOccptAtRowSecPasSideSnsSts2 3 "OkNokDi_Reserved" 2 "OkNokDi_Disabled" 1 "OkNokDi_NotOk" 0 "OkNokDi_Ok" ;
VAL_ 120 SwtIndcrIndcrTypExtReq 2 "IndcrTypExt1_Ri" 1 "IndcrTypExt1_Le" 0 "IndcrTypExt1_Off" ;
VAL_ 120 SwtIndcrIndcrTypExtReqToUpdQf 3 "Qf1_DataCalcdWithDevDefd" 2 "Qf1_DevOfDataNotWithinRngAllwd" 1 "Qf1_DataTmpUndefdAndEvlnInProgs" 0 "Qf1_DevOfDataUndefd" ;
VAL_ 118 DoorPassRealLockSts 3 "LockSts2_SafeLockd" 2 "LockSts2_Lockd" 1 "LockSts2_Unlckd" 0 "LockSts2_LockStsUkwn" ;
VAL_ 118 DoorPassReRealLockSts 3 "LockSts2_SafeLockd" 2 "LockSts2_Lockd" 1 "LockSts2_Unlckd" 0 "LockSts2_LockStsUkwn" ;
VAL_ 118 DoorSldngLeReRelsReq 3 "OnOffSafe1_OnOffSafeInvld2" 2 "OnOffSafe1_OnOffSafeOff" 1 "OnOffSafe1_OnOffSafeOn" 0 "OnOffSafe1_OnOffSafeInvld1" ;
VAL_ 118 DoorSldngRiReRelsReq 3 "OnOffSafe1_OnOffSafeInvld2" 2 "OnOffSafe1_OnOffSafeOff" 1 "OnOffSafe1_OnOffSafeOn" 0 "OnOffSafe1_OnOffSafeInvld1" ;
VAL_ 118 PassLockContnSts 1 "Boolean_TRUE" 0 "Boolean_FALSE" ;
VAL_ 118 VehSpdLgtQf 3 "GenQf1_AccurData" 2 "GenQf1_DataAccurNotWithinSpcn" 1 "GenQf1_TmpUndefdData" 0 "GenQf1_UndefindDataAccur" ;
VAL_ 280 DoorDrvrRealLockSts 3 "LockSts2_SafeLockd" 2 "LockSts2_Lockd" 1 "LockSts2_Unlckd" 0 "LockSts2_LockStsUkwn" ;
VAL_ 280 DoorDrvrReRealLockSts 3 "LockSts2_SafeLockd" 2 "LockSts2_Lockd" 1 "LockSts2_Unlckd" 0 "LockSts2_LockStsUkwn" ;
VAL_ 280 DrvrLockContnSts 1 "Boolean_TRUE" 0 "Boolean_FALSE" ;
VAL_ 280 TrRelsReq 3 "OnOffSafe1_OnOffSafeInvld2" 2 "OnOffSafe1_OnOffSafeOff" 1 "OnOffSafe1_OnOffSafeOn" 0 "OnOffSafe1_OnOffSafeInvld1" ;
VAL_ 921 TrsmActrPosnSafeTrsmActrPosn 7 "TrsmActrPosn1_Undefd" 6 "TrsmActrPosn1_Drv" 5 "TrsmActrPosn1_NeutDrv" 4 "TrsmActrPosn1_Neut" 3 "TrsmActrPosn1_RvsNeut" 2 "TrsmActrPosn1_Rvs" 1 "TrsmActrPosn1_ParkRvs" 0 "TrsmActrPosn1_Park" ;
VAL_ 921 VehTiAndDataDataValid 1 "NoYes1_Yes" 0 "NoYes1_No" ;
VAL_ 552 DrvrSeatAdpvLumSetg 1 "OnOff1_On" 0 "OnOff1_Off" ;
VAL_ 552 HmiSeatHeatgForRowSecLe 7 "SeatClimaLvl1_idle" 6 "SeatClimaLvl1_Resvd2" 5 "SeatClimaLvl1_Resvd1" 4 "SeatClimaLvl1_Auto" 3 "SeatClimaLvl1_Lvl3" 2 "SeatClimaLvl1_Lvl2" 1 "SeatClimaLvl1_Lvl1" 0 "SeatClimaLvl1_Off" ;
VAL_ 552 HmiSeatHeatgForRowSecRi 7 "SeatClimaLvl1_idle" 6 "SeatClimaLvl1_Resvd2" 5 "SeatClimaLvl1_Resvd1" 4 "SeatClimaLvl1_Auto" 3 "SeatClimaLvl1_Lvl3" 2 "SeatClimaLvl1_Lvl2" 1 "SeatClimaLvl1_Lvl1" 0 "SeatClimaLvl1_Off" ;
VAL_ 552 HmiSeatHeatgForRowThrdLe 7 "SeatClimaLvl1_idle" 6 "SeatClimaLvl1_Resvd2" 5 "SeatClimaLvl1_Resvd1" 4 "SeatClimaLvl1_Auto" 3 "SeatClimaLvl1_Lvl3" 2 "SeatClimaLvl1_Lvl2" 1 "SeatClimaLvl1_Lvl1" 0 "SeatClimaLvl1_Off" ;
VAL_ 552 HmiSeatHeatgForRowThrdRi 7 "SeatClimaLvl1_idle" 6 "SeatClimaLvl1_Resvd2" 5 "SeatClimaLvl1_Resvd1" 4 "SeatClimaLvl1_Auto" 3 "SeatClimaLvl1_Lvl3" 2 "SeatClimaLvl1_Lvl2" 1 "SeatClimaLvl1_Lvl1" 0 "SeatClimaLvl1_Off" ;
VAL_ 552 HmiSeatVentnForRowSecLe 7 "SeatClimaLvl1_idle" 6 "SeatClimaLvl1_Resvd2" 5 "SeatClimaLvl1_Resvd1" 4 "SeatClimaLvl1_Auto" 3 "SeatClimaLvl1_Lvl3" 2 "SeatClimaLvl1_Lvl2" 1 "SeatClimaLvl1_Lvl1" 0 "SeatClimaLvl1_Off" ;
VAL_ 552 HmiSeatVentnForRowSecRi 7 "SeatClimaLvl1_idle" 6 "SeatClimaLvl1_Resvd2" 5 "SeatClimaLvl1_Resvd1" 4 "SeatClimaLvl1_Auto" 3 "SeatClimaLvl1_Lvl3" 2 "SeatClimaLvl1_Lvl2" 1 "SeatClimaLvl1_Lvl1" 0 "SeatClimaLvl1_Off" ;
VAL_ 552 HmiSeatVentnForRowThrdLe 7 "SeatClimaLvl1_idle" 6 "SeatClimaLvl1_Resvd2" 5 "SeatClimaLvl1_Resvd1" 4 "SeatClimaLvl1_Auto" 3 "SeatClimaLvl1_Lvl3" 2 "SeatClimaLvl1_Lvl2" 1 "SeatClimaLvl1_Lvl1" 0 "SeatClimaLvl1_Off" ;
VAL_ 552 HmiSeatVentnForRowThrdRi 7 "SeatClimaLvl1_idle" 6 "SeatClimaLvl1_Resvd2" 5 "SeatClimaLvl1_Resvd1" 4 "SeatClimaLvl1_Auto" 3 "SeatClimaLvl1_Lvl3" 2 "SeatClimaLvl1_Lvl2" 1 "SeatClimaLvl1_Lvl1" 0 "SeatClimaLvl1_Off" ;
VAL_ 552 KeyScanActv 1 "Boolean_TRUE" 0 "Boolean_FALSE" ;
VAL_ 552 PrkgStsToEDRAPATo 7 "APATo_Reserved3" 6 "APATo_Reserved2" 5 "APATo_Reserved1" 4 "APATo_Active" 3 "APATo_StandBy" 2 "APATo_Off" 1 "APATo_Faulted" 0 "APATo_Defualt" ;
VAL_ 552 PrkgStsToEDRHPATo 7 "APATo_Reserved3" 6 "APATo_Reserved2" 5 "APATo_Reserved1" 4 "APATo_Active" 3 "APATo_StandBy" 2 "APATo_Off" 1 "APATo_Faulted" 0 "APATo_Defualt" ;
VAL_ 552 PrkgStsToEDRLSDAandTBATo 7 "APATo_Reserved3" 6 "APATo_Reserved2" 5 "APATo_Reserved1" 4 "APATo_Active" 3 "APATo_StandBy" 2 "APATo_Off" 1 "APATo_Faulted" 0 "APATo_Defualt" ;
VAL_ 552 PrkgStsToEDRreserved1 7 "APATo_Reserved3" 6 "APATo_Reserved2" 5 "APATo_Reserved1" 4 "APATo_Active" 3 "APATo_StandBy" 2 "APATo_Off" 1 "APATo_Faulted" 0 "APATo_Defualt" ;
VAL_ 552 PrkgStsToEDRreserved2 7 "APATo_Reserved3" 6 "APATo_Reserved2" 5 "APATo_Reserved1" 4 "APATo_Active" 3 "APATo_StandBy" 2 "APATo_Off" 1 "APATo_Faulted" 0 "APATo_Defualt" ;
VAL_ 552 PrkgStsToEDRreserved3 7 "APATo_Reserved3" 6 "APATo_Reserved2" 5 "APATo_Reserved1" 4 "APATo_Active" 3 "APATo_StandBy" 2 "APATo_Off" 1 "APATo_Faulted" 0 "APATo_Defualt" ;
VAL_ 552 PrkgStsToEDRRPATo 7 "APATo_Reserved3" 6 "APATo_Reserved2" 5 "APATo_Reserved1" 4 "APATo_Active" 3 "APATo_StandBy" 2 "APATo_Off" 1 "APATo_Faulted" 0 "APATo_Defualt" ;
SIG_GROUP_ 1354 VFCVectorTRM 1 : VFCVectorTRMVFCid35 VFCVectorTRMVFCid39 VFCVectorTRMVFCid25 VFCVectorTRMVFCid27 VFCVectorTRMVFCid10 VFCVectorTRMVFCid12 VFCVectorTRMVFCid9 VFCVectorTRMVFCid6 VFCVectorTRMVFCid8 VFCVectorTRMVFCid21 VFCVectorTRMVFCid41 VFCVectorTRMVFCid57 VFCVectorTRMVFCid48 VFCVectorTRMVFCid36 VFCVectorTRMVFCid47 VFCVectorTRMVFCid0 VFCVectorTRMVFCid26 VFCVectorTRMVFCid11 VFCVectorTRMVFCid50 VFCVectorTRMVFCid24 VFCVectorTRMVFCid40 VFCVectorTRMVFCid15 VFCVectorTRMVFCid18 VFCVectorTRMVFCid19 VFCVectorTRMVFCid16 VFCVectorTRMVFCid23 VFCVectorTRMVFCid58 VFCVectorTRMVFCid30 VFCVectorTRMVFCid51 VFCVectorTRMVFCid60 VFCVectorTRMVFCid32 VFCVectorTRMVFCid7 VFCVectorTRMVFCid56 VFCVectorTRMVFCid54 VFCVectorTRMVFCid42 VFCVectorTRMVFCid53 VFCVectorTRMVFCid28 VFCVectorTRMVFCid5 VFCVectorTRMVFCid61 VFCVectorTRMVFCid29 VFCVectorTRMVFCid49 VFCVectorTRMVFCid43 VFCVectorTRMVFCid20 VFCVectorTRMVFCid31 VFCVectorTRMVFCid13 VFCVectorTRMVFCid46 VFCVectorTRMVFCid37 VFCVectorTRMBlockID VFCVectorTRMVFCid38 VFCVectorTRMVFCid2 VFCVectorTRMVFCid34 VFCVectorTRMVFCid52 VFCVectorTRMVFCid4 VFCVectorTRMVFCid1 VFCVectorTRMVFCid17 VFCVectorTRMVFCid59 VFCVectorTRMVFCid3 VFCVectorTRMVFCid22 VFCVectorTRMVFCid33 VFCVectorTRMVFCid45 VFCVectorTRMVFCid44 VFCVectorTRMVFCid14 VFCVectorTRMVFCid55;
SIG_GROUP_ 1345 VFCVectorZCUDM 1 : VFCVectorZCUDMVFCid47 VFCVectorZCUDMVFCid28 VFCVectorZCUDMVFCid31 VFCVectorZCUDMBlockID VFCVectorZCUDMVFCid44 VFCVectorZCUDMVFCid54 VFCVectorZCUDMVFCid52 VFCVectorZCUDMVFCid4 VFCVectorZCUDMVFCid57 VFCVectorZCUDMVFCid9 VFCVectorZCUDMVFCid33 VFCVectorZCUDMVFCid45 VFCVectorZCUDMVFCid3 VFCVectorZCUDMVFCid59 VFCVectorZCUDMVFCid12 VFCVectorZCUDMVFCid49 VFCVectorZCUDMVFCid60 VFCVectorZCUDMVFCid21 VFCVectorZCUDMVFCid56 VFCVectorZCUDMVFCid37 VFCVectorZCUDMVFCid30 VFCVectorZCUDMVFCid58 VFCVectorZCUDMVFCid36 VFCVectorZCUDMVFCid41 VFCVectorZCUDMVFCid61 VFCVectorZCUDMVFCid39 VFCVectorZCUDMVFCid42 VFCVectorZCUDMVFCid15 VFCVectorZCUDMVFCid53 VFCVectorZCUDMVFCid20 VFCVectorZCUDMVFCid25 VFCVectorZCUDMVFCid55 VFCVectorZCUDMVFCid48 VFCVectorZCUDMVFCid13 VFCVectorZCUDMVFCid5 VFCVectorZCUDMVFCid11 VFCVectorZCUDMVFCid7 VFCVectorZCUDMVFCid17 VFCVectorZCUDMVFCid16 VFCVectorZCUDMVFCid22 VFCVectorZCUDMVFCid46 VFCVectorZCUDMVFCid23 VFCVectorZCUDMVFCid50 VFCVectorZCUDMVFCid0 VFCVectorZCUDMVFCid10 VFCVectorZCUDMVFCid8 VFCVectorZCUDMVFCid18 VFCVectorZCUDMVFCid6 VFCVectorZCUDMVFCid19 VFCVectorZCUDMVFCid51 VFCVectorZCUDMVFCid24 VFCVectorZCUDMVFCid43 VFCVectorZCUDMVFCid29 VFCVectorZCUDMVFCid14 VFCVectorZCUDMVFCid32 VFCVectorZCUDMVFCid27 VFCVectorZCUDMVFCid2 VFCVectorZCUDMVFCid26 VFCVectorZCUDMVFCid40 VFCVectorZCUDMVFCid34 VFCVectorZCUDMVFCid35 VFCVectorZCUDMVFCid38 VFCVectorZCUDMVFCid1;
SIG_GROUP_ 64 TrOpenerReq 1 : TrOpenerReqTrOpenerReq TrOpenerReqTrigSrc;
SIG_GROUP_ 64 VehMtnSt 1 : VehMtnStCntr VehMtnStVehMtnSt VehMtnStChks;
SIG_GROUP_ 1164 TiAndDateIndcn 1 : TiAndDateIndcnSec1 TiAndDateIndcnMins1 TiAndDateIndcnDay TiAndDateIndcnDataValid TiAndDateIndcnHr1 TiAndDateIndcnYr1 TiAndDateIndcnMth1;
SIG_GROUP_ 240 VehModMngtGlbSafe1 1 : VehModMngtGlbSafe1EgyLvlElecSubt VehModMngtGlbSafe1CarModSts1 VehModMngtGlbSafe1Chks VehModMngtGlbSafe1PwrLvlElecSubt VehModMngtGlbSafe1PwrLvlElecMai VehModMngtGlbSafe1FltEgyCnsWdSts VehModMngtGlbSafe1EgyLvlElecMai VehModMngtGlbSafe1Cntr VehModMngtGlbSafe1CarModSubtypWd VehModMngtGlbSafe1UsgModSts;
SIG_GROUP_ 880 EngSt1WdSts 1 : EngSt1WdStsCntr EngSt1WdStsChks EngSt1WdStsEngSt1WdSts;
SIG_GROUP_ 816 ChrgnUReq 1 : ChrgnUReqCntr ChrgnUReqChrgnUReq ChrgnUReqChks;
SIG_GROUP_ 816 VehBattU 1 : VehBattUSysUQf VehBattUSysU;
SIG_GROUP_ 912 DrvrSeatPosPerc 1 : DrvrSeatPosPercSeatPosFrntHeiPer DrvrSeatPosPercSeatPosSldQF DrvrSeatPosPercSeatPosHeiPerc DrvrSeatPosPercSeatPosSldPerc DrvrSeatPosPercSeatPosHeiQF DrvrSeatPosPercSeatPosFrntHeiQF;
SIG_GROUP_ 912 PassAirbLampStsRec 1 : PassAirbLampStsRecPassAirbL_0000 PassAirbLampStsRecPassAirbLampSt PassAirbLampStsRecPassAirbL_0001;
SIG_GROUP_ 924 RiFrntTireMsg 1 : RiFrntTireMsgTireFillgAssiPSts RiFrntTireMsgSysWarnFlg RiFrntTireMsgPWarnFlg RiFrntTireMsgMsgOldFlg RiFrntTireMsgBattLoSt RiFrntTireMsgT RiFrntTireMsgP RiFrntTireMsgTWarnFlg RiFrntTireMsgFastLoseWarnFlg;
SIG_GROUP_ 924 RiReTireMsg 1 : RiReTireMsgP RiReTireMsgTWarnFlg RiReTireMsgSysWarnFlg RiReTireMsgMsgOldFlg RiReTireMsgTireFillgAssiPSts RiReTireMsgPWarnFlg RiReTireMsgBattLoSt RiReTireMsgFastLoseWarnFlg RiReTireMsgT;
SIG_GROUP_ 904 BrkAndAbsWarnIndcnReq 1 : BrkAndAbsWarnIndcnReqChks BrkAndAbsWarnIndcnReqBrkWarnIndc BrkAndAbsWarnIndcnReqCntr BrkAndAbsWarnIndcnReqAbsWarnIndc;
SIG_GROUP_ 800 AsyALgtSts 1 : AsyALgtStsAsyALgtSts AsyALgtStsCntr AsyALgtStsChks;
SIG_GROUP_ 900 EscSt 1 : EscStCntr EscStChks EscStEscSt;
SIG_GROUP_ 900 BrkPedlrRat 1 : BrkPedlrRatQf BrkPedlrRatPerc;
SIG_GROUP_ 916 LeFrntTireMsg 1 : LeFrntTireMsgP LeFrntTireMsgMsgOldFlg LeFrntTireMsgTireFillgAssiPSts LeFrntTireMsgPWarnFlg LeFrntTireMsgTWarnFlg LeFrntTireMsgSysWarnFlg LeFrntTireMsgFastLoseWarnFlg LeFrntTireMsgT LeFrntTireMsgBattLoSt;
SIG_GROUP_ 916 LeReTireMsg 1 : LeReTireMsgBattLoSt LeReTireMsgP LeReTireMsgT LeReTireMsgTireFillgAssiPSts LeReTireMsgFastLoseWarnFlg LeReTireMsgMsgOldFlg LeReTireMsgSysWarnFlg LeReTireMsgPWarnFlg LeReTireMsgTWarnFlg;
SIG_GROUP_ 920 PassSeatPosPerc 1 : PassSeatPosPercSeatPosHeiPerc PassSeatPosPercSeatPosSldPerc PassSeatPosPercSeatPosFrntHeiQF PassSeatPosPercSeatPosSldQF PassSeatPosPercSeatPosFrntHeiPer PassSeatPosPercSeatPosHeiQF;
SIG_GROUP_ 888 PinionSteerAgGroup 1 : PinionSteerAgGroupChks PinionSteerAgGroupPinionSteerAg1 PinionSteerAgGroupCntr PinionSteerAgGroupSteerWhlTq PinionSteerAgGroupPinionSte_0000 PinionSteerAgGroupPinionSteerAgS PinionSteerAgGroupPinionSte_0001 PinionSteerAgGroupSteerWhlTqQf;
SIG_GROUP_ 837 AbsCtrlActv 1 : AbsCtrlActvCtrlSts1 AbsCtrlActvChks AbsCtrlActvCntr;
SIG_GROUP_ 518 AccrPedlRat 1 : AccrPedlRatAccrPedlRat AccrPedlRatCntr AccrPedlRatChks;
SIG_GROUP_ 36 AccrpedlSts 1 : AccrpedlStsChks AccrpedlStsFltSts AccrpedlStsCntr;
SIG_GROUP_ 815 ThrdRowLeSeatDispMassgFct 1 : ThrdRowLeSeatDispMassgFctMassgIn ThrdRowLeSeatDispMassgFctMassgPr ThrdRowLeSeatDispMassgFctOnOffl2;
SIG_GROUP_ 815 BrkPedlPsd 1 : BrkPedlPsdBrkPedlNotPsdSafe BrkPedlPsdCntr BrkPedlPsdBrkPedlPsd BrkPedlPsdChks BrkPedlPsdQf;
SIG_GROUP_ 815 ThrdRowRiSeatDispMassgFct 1 : ThrdRowRiSeatDispMassgFctMassgPr ThrdRowRiSeatDispMassgFctMassgIn ThrdRowRiSeatDispMassgFctOnOffl2;
SIG_GROUP_ 84 BrkSysCylPMst 1 : BrkSysCylPMstAct BrkSysCylPMstActQf BrkSysCylPMstTar BrkSysCylPMstVirtQf BrkSysCylPMstVirt BrkSysCylPMstCntr BrkSysCylPMstChks;
SIG_GROUP_ 131 SftyDecelGroupSafe 1 : SftyDecelGroupSafeChks SftyDecelGroupSafeCntr SftyDecelGroupSafeAsySftyDecelRe SftyDecelGroupSafeAsySftyEnaDece;
SIG_GROUP_ 305 VehSpdIndcd 1 : VehSpdIndcdVeSpdIndcdUnit VehSpdIndcdVehSpdIndcd;
SIG_GROUP_ 305 EpbSts 1 : EpbStsEpbSts EpbStsCntr EpbStsChks;
SIG_GROUP_ 120 OccupyMonSts 1 : OccupyMonStsThrdMidSts OccupyMonStsSecMidSts OccupyMonStsThrdLeSts OccupyMonStsPassSts OccupyMonStsSecRiSts OccupyMonStsDrvrSts OccupyMonStsThrdRiSts OccupyMonStsSeccLeSts;
SIG_GROUP_ 120 SwtIndcr 1 : SwtIndcrIndcrTypExtReq SwtIndcrIndcrTypExtReqToUpdQf SwtIndcrIndcrTypExtReqChks SwtIndcrIndcrTypExtReqCntr;
SIG_GROUP_ 323 PosnBrief 1 : PosnBriefPosnLgt PosnBriefPosnLat;
SIG_GROUP_ 832 VehCfgPrm 1 : VehCfgPrmCCPBytePosn4 VehCfgPrmCCPBytePosn5 VehCfgPrmBlkIDBytePosn1 VehCfgPrmCCPBytePosn8 VehCfgPrmCCPBytePosn2 VehCfgPrmCCPBytePosn6 VehCfgPrmCCPBytePosn3 VehCfgPrmCCPBytePosn7;
SIG_GROUP_ 306 VehCfgPrmExt 1 : VehCfgPrmExtCCPBytePosn8 VehCfgPrmExtCCPBytePosn4 VehCfgPrmExtCCPBytePosn3 VehCfgPrmExtCCPBytePosn5 VehCfgPrmExtBlkIDBytePosn1 VehCfgPrmExtCCPBytePosn6 VehCfgPrmExtCCPBytePosn7 VehCfgPrmExtCCPBytePosn2;
SIG_GROUP_ 128 Vin 1 : VinVINSignalPos1 VinVINSignalPos7 VinVINSignalPos6 VinVINSignalPos4 VinVINSignalPos5 VinVINSignalPos2 VinBlockNr VinVINSignalPos3;
SIG_GROUP_ 118 VehSpdLgt 1 : VehSpdLgtQf VehSpdLgtCntr VehSpdLgtChks VehSpdLgtA;
SIG_GROUP_ 921 TrsmActrPosnSafe 1 : TrsmActrPosnSafeTrsmActrPosn TrsmActrPosnSafeTrsmActrPosnCntr TrsmActrPosnSafeTrsmActrPosnChks;
SIG_GROUP_ 921 VehTiAndData 1 : VehTiAndDataDay VehTiAndDataHr1 VehTiAndDataSec1 VehTiAndDataYr1 VehTiAndDataMth1 VehTiAndDataDataValid VehTiAndDataMins1;
SIG_GROUP_ 552 PrkgStsToEDR 1 : PrkgStsToEDRreserved2 PrkgStsToEDRHPATo PrkgStsToEDRreserved1 PrkgStsToEDRLSDAandTBATo PrkgStsToEDRAPATo PrkgStsToEDRreserved3 PrkgStsToEDRRPATo;
